[part 11 of 11: packages /CANAnalyzer/CommunicationClusters to /CANAnalyzer/DataTypes]
AUTOSAR XML (schema 00051)
package /CANAnalyzer/CommunicationClusters  (continued)
  can cluster CAN_FD_IPB_41  (continued)
    can physical channel Channel  (continued)
      frame TPDiagnosisFlash_FBD_Miko_IPB: id 0x2C8, frame-length=64, can-addressing-mode=STANDARD, can-frame-rx-behavior=CAN-FD, can-frame-tx-behavior=CAN-FD
        pdu TPDiagnosisFlash_FBD_Miko_IPB: length=64, unused-bit-pattern=0
          signal TPDiagnosisFlashFBD_MikoIPB_Byte00: start 0, 8 bit, little-endian, data-type-policy=OVERRIDE, base-type=uint8, compu {phys=raw}, range phys 0..252
          signal TPDiagnosisFlashFBD_MikoIPB_Byte01: start 8, 8 bit, little-endian, data-type-policy=OVERRIDE, base-type=uint8, compu {phys=raw}, range phys 0..252
          signal TPDiagnosisFlashFBD_MikoIPB_Byte02: start 16, 8 bit, little-endian, data-type-policy=OVERRIDE, base-type=uint8, compu {phys=raw}, range phys 0..252
          signal TPDiagnosisFlashFBD_MikoIPB_Byte03: start 24, 8 bit, little-endian, data-type-policy=OVERRIDE, base-type=uint8, compu {phys=raw}, range phys 0..252
          signal TPDiagnosisFlashFBD_MikoIPB_Byte04: start 32, 8 bit, little-endian, data-type-policy=OVERRIDE, base-type=uint8, compu {phys=raw}, range phys 0..252
          signal TPDiagnosisFlashFBD_MikoIPB_Byte05: start 40, 8 bit, little-endian, data-type-policy=OVERRIDE, base-type=uint8, compu {phys=raw}, range phys 0..252
          signal TPDiagnosisFlashFBD_MikoIPB_Byte06: start 48, 8 bit, little-endian, data-type-policy=OVERRIDE, base-type=uint8, compu {phys=raw}, range phys 0..252
          signal TPDiagnosisFlashFBD_MikoIPB_Byte07: start 56, 8 bit, little-endian, data-type-policy=OVERRIDE, base-type=uint8, compu {phys=raw}, range phys 0..252
          signal TPDiagnosisFlashFBD_MikoIPB_Byte08: start 64, 8 bit, little-endian, data-type-policy=OVERRIDE, base-type=uint8, compu {phys=raw}, range phys 0..252
          signal TPDiagnosisFlashFBD_MikoIPB_Byte09: start 72, 8 bit, little-endian, data-type-policy=OVERRIDE, base-type=uint8, compu {phys=raw}, range phys 0..252
          signal TPDiagnosisFlashFBD_MikoIPB_Byte10: start 80, 8 bit, little-endian, data-type-policy=OVERRIDE, base-type=uint8, compu {phys=raw}, range phys 0..252
          signal TPDiagnosisFlashFBD_MikoIPB_Byte11: start 88, 8 bit, little-endian, data-type-policy=OVERRIDE, base-type=uint8, compu {phys=raw}, range phys 0..252
          signal TPDiagnosisFlashFBD_MikoIPB_Byte12: start 96, 8 bit, little-endian, data-type-policy=OVERRIDE, base-type=uint8, compu {phys=raw}, range phys 0..252
          signal TPDiagnosisFlashFBD_MikoIPB_Byte13: start 104, 8 bit, little-endian, data-type-policy=OVERRIDE, base-type=uint8, compu {phys=raw}, range phys 0..252
          signal TPDiagnosisFlashFBD_MikoIPB_Byte14: start 112, 8 bit, little-endian, data-type-policy=OVERRIDE, base-type=uint8, compu {phys=raw}, range phys 0..252
          signal TPDiagnosisFlashFBD_MikoIPB_Byte15: start 120, 8 bit, little-endian, data-type-policy=OVERRIDE, base-type=uint8, compu {phys=raw}, range phys 0..252
          signal TPDiagnosisFlashFBD_MikoIPB_Byte16: start 128, 8 bit, little-endian, data-type-policy=OVERRIDE, base-type=uint8, compu {phys=raw}, range phys 0..252
          signal TPDiagnosisFlashFBD_MikoIPB_Byte17: start 136, 8 bit, little-endian, data-type-policy=OVERRIDE, base-type=uint8, compu {phys=raw}, range phys 0..252
          signal TPDiagnosisFlashFBD_MikoIPB_Byte18: start 144, 8 bit, little-endian, data-type-policy=OVERRIDE, base-type=uint8, compu {phys=raw}, range phys 0..252
          signal TPDiagnosisFlashFBD_MikoIPB_Byte19: start 152, 8 bit, little-endian, data-type-policy=OVERRIDE, base-type=uint8, compu {phys=raw}, range phys 0..252
          signal TPDiagnosisFlashFBD_MikoIPB_Byte20: start 160, 8 bit, little-endian, data-type-policy=OVERRIDE, base-type=uint8, compu {phys=raw}, range phys 0..252
          signal TPDiagnosisFlashFBD_MikoIPB_Byte21: start 168, 8 bit, little-endian, data-type-policy=OVERRIDE, base-type=uint8, compu {phys=raw}, range phys 0..252
          signal TPDiagnosisFlashFBD_MikoIPB_Byte22: start 176, 8 bit, little-endian, data-type-policy=OVERRIDE, base-type=uint8, compu {phys=raw}, range phys 0..252
          signal TPDiagnosisFlashFBD_MikoIPB_Byte23: start 184, 8 bit, little-endian, data-type-policy=OVERRIDE, base-type=uint8, compu {phys=raw}, range phys 0..252
          signal TPDiagnosisFlashFBD_MikoIPB_Byte24: start 192, 8 bit, little-endian, data-type-policy=OVERRIDE, base-type=uint8, compu {phys=raw}, range phys 0..252
          signal TPDiagnosisFlashFBD_MikoIPB_Byte25: start 200, 8 bit, little-endian, data-type-policy=OVERRIDE, base-type=uint8, compu {phys=raw}, range phys 0..252
          signal TPDiagnosisFlashFBD_MikoIPB_Byte26: start 208, 8 bit, little-endian, data-type-policy=OVERRIDE, base-type=uint8, compu {phys=raw}, range phys 0..252
          signal TPDiagnosisFlashFBD_MikoIPB_Byte27: start 216, 8 bit, little-endian, data-type-policy=OVERRIDE, base-type=uint8, compu {phys=raw}, range phys 0..252
          signal TPDiagnosisFlashFBD_MikoIPB_Byte28: start 224, 8 bit, little-endian, data-type-policy=OVERRIDE, base-type=uint8, compu {phys=raw}, range phys 0..252
          signal TPDiagnosisFlashFBD_MikoIPB_Byte29: start 232, 8 bit, little-endian, data-type-policy=OVERRIDE, base-type=uint8, compu {phys=raw}, range phys 0..252
          signal TPDiagnosisFlashFBD_MikoIPB_Byte30: start 240, 8 bit, little-endian, data-type-policy=OVERRIDE, base-type=uint8, compu {phys=raw}, range phys 0..252
          signal TPDiagnosisFlashFBD_MikoIPB_Byte31: start 248, 8 bit, little-endian, data-type-policy=OVERRIDE, base-type=uint8, compu {phys=raw}, range phys 0..252
          signal TPDiagnosisFlashFBD_MikoIPB_Byte32: start 256, 8 bit, little-endian, data-type-policy=OVERRIDE, base-type=uint8, compu {phys=raw}, range phys 0..252
          signal TPDiagnosisFlashFBD_MikoIPB_Byte33: start 264, 8 bit, little-endian, data-type-policy=OVERRIDE, base-type=uint8, compu {phys=raw}, range phys 0..252
          signal TPDiagnosisFlashFBD_MikoIPB_Byte34: start 272, 8 bit, little-endian, data-type-policy=OVERRIDE, base-type=uint8, compu {phys=raw}, range phys 0..252
          signal TPDiagnosisFlashFBD_MikoIPB_Byte35: start 280, 8 bit, little-endian, data-type-policy=OVERRIDE, base-type=uint8, compu {phys=raw}, range phys 0..252
          signal TPDiagnosisFlashFBD_MikoIPB_Byte36: start 288, 8 bit, little-endian, data-type-policy=OVERRIDE, base-type=uint8, compu {phys=raw}, range phys 0..252
          signal TPDiagnosisFlashFBD_MikoIPB_Byte37: start 296, 8 bit, little-endian, data-type-policy=OVERRIDE, base-type=uint8, compu {phys=raw}, range phys 0..252
          signal TPDiagnosisFlashFBD_MikoIPB_Byte38: start 304, 8 bit, little-endian, data-type-policy=OVERRIDE, base-type=uint8, compu {phys=raw}, range phys 0..252
          signal TPDiagnosisFlashFBD_MikoIPB_Byte39: start 312, 8 bit, little-endian, data-type-policy=OVERRIDE, base-type=uint8, compu {phys=raw}, range phys 0..252
          signal TPDiagnosisFlashFBD_MikoIPB_Byte40: start 320, 8 bit, little-endian, data-type-policy=OVERRIDE, base-type=uint8, compu {phys=raw}, range phys 0..252
          signal TPDiagnosisFlashFBD_MikoIPB_Byte41: start 328, 8 bit, little-endian, data-type-policy=OVERRIDE, base-type=uint8, compu {phys=raw}, range phys 0..252
          signal TPDiagnosisFlashFBD_MikoIPB_Byte42: start 336, 8 bit, little-endian, data-type-policy=OVERRIDE, base-type=uint8, compu {phys=raw}, range phys 0..252
          signal TPDiagnosisFlashFBD_MikoIPB_Byte43: start 344, 8 bit, little-endian, data-type-policy=OVERRIDE, base-type=uint8, compu {phys=raw}, range phys 0..252
          signal TPDiagnosisFlashFBD_MikoIPB_Byte44: start 352, 8 bit, little-endian, data-type-policy=OVERRIDE, base-type=uint8, compu {phys=raw}, range phys 0..252
          signal TPDiagnosisFlashFBD_MikoIPB_Byte45: start 360, 8 bit, little-endian, data-type-policy=OVERRIDE, base-type=uint8, compu {phys=raw}, range phys 0..252
          signal TPDiagnosisFlashFBD_MikoIPB_Byte46: start 368, 8 bit, little-endian, data-type-policy=OVERRIDE, base-type=uint8, compu {phys=raw}, range phys 0..252
          signal TPDiagnosisFlashFBD_MikoIPB_Byte47: start 376, 8 bit, little-endian, data-type-policy=OVERRIDE, base-type=uint8, compu {phys=raw}, range phys 0..252
          signal TPDiagnosisFlashFBD_MikoIPB_Byte48: start 384, 8 bit, little-endian, data-type-policy=OVERRIDE, base-type=uint8, compu {phys=raw}, range phys 0..252
          signal TPDiagnosisFlashFBD_MikoIPB_Byte49: start 392, 8 bit, little-endian, data-type-policy=OVERRIDE, base-type=uint8, compu {phys=raw}, range phys 0..252
          signal TPDiagnosisFlashFBD_MikoIPB_Byte50: start 400, 8 bit, little-endian, data-type-policy=OVERRIDE, base-type=uint8, compu {phys=raw}, range phys 0..252
          signal TPDiagnosisFlashFBD_MikoIPB_Byte51: start 408, 8 bit, little-endian, data-type-policy=OVERRIDE, base-type=uint8, compu {phys=raw}, range phys 0..252
          signal TPDiagnosisFlashFBD_MikoIPB_Byte52: start 416, 8 bit, little-endian, data-type-policy=OVERRIDE, base-type=uint8, compu {phys=raw}, range phys 0..252
          signal TPDiagnosisFlashFBD_MikoIPB_Byte53: start 424, 8 bit, little-endian, data-type-policy=OVERRIDE, base-type=uint8, compu {phys=raw}, range phys 0..252
          signal TPDiagnosisFlashFBD_MikoIPB_Byte54: start 432, 8 bit, little-endian, data-type-policy=OVERRIDE, base-type=uint8, compu {phys=raw}, range phys 0..252
          signal TPDiagnosisFlashFBD_MikoIPB_Byte55: start 440, 8 bit, little-endian, data-type-policy=OVERRIDE, base-type=uint8, compu {phys=raw}, range phys 0..252
          signal TPDiagnosisFlashFBD_MikoIPB_Byte56: start 448, 8 bit, little-endian, data-type-policy=OVERRIDE, base-type=uint8, compu {phys=raw}, range phys 0..252
          signal TPDiagnosisFlashFBD_MikoIPB_Byte57: start 456, 8 bit, little-endian, data-type-policy=OVERRIDE, base-type=uint8, compu {phys=raw}, range phys 0..252
          signal TPDiagnosisFlashFBD_MikoIPB_Byte58: start 464, 8 bit, little-endian, data-type-policy=OVERRIDE, base-type=uint8, compu {phys=raw}, range phys 0..252
          signal TPDiagnosisFlashFBD_MikoIPB_Byte59: start 472, 8 bit, little-endian, data-type-policy=OVERRIDE, base-type=uint8, compu {phys=raw}, range phys 0..252
          signal TPDiagnosisFlashFBD_MikoIPB_Byte60: start 480, 8 bit, little-endian, data-type-policy=OVERRIDE, base-type=uint8, compu {phys=raw}, range phys 0..252
          signal TPDiagnosisFlashFBD_MikoIPB_Byte61: start 488, 8 bit, little-endian, data-type-policy=OVERRIDE, base-type=uint8, compu {phys=raw}, range phys 0..252
          signal TPDiagnosisFlashFBD_MikoIPB_Byte62: start 496, 8 bit, little-endian, data-type-policy=OVERRIDE, base-type=uint8, compu {phys=raw}, range phys 0..252
          signal TPDiagnosisFlashFBD_MikoIPB_Byte63: start 504, 8 bit, little-endian, data-type-policy=OVERRIDE, base-type=uint8, compu {phys=raw}, range phys 0..252
      frame TPDiagnosisFlash_FBD_MM_IPB: id 0x366, frame-length=64, can-addressing-mode=STANDARD, can-frame-rx-behavior=CAN-FD, can-frame-tx-behavior=CAN-FD
        pdu TPDiagnosisFlash_FBD_MM_IPB: length=64, unused-bit-pattern=0
          signal TPDiagnosisFlashFBD_MMIPB_Byte00: start 0, 8 bit, little-endian, data-type-policy=OVERRIDE, base-type=uint8, compu {phys=raw}, range phys 0..252
          signal TPDiagnosisFlashFBD_MMIPB_Byte01: start 8, 8 bit, little-endian, data-type-policy=OVERRIDE, base-type=uint8, compu {phys=raw}, range phys 0..252
          signal TPDiagnosisFlashFBD_MMIPB_Byte02: start 16, 8 bit, little-endian, data-type-policy=OVERRIDE, base-type=uint8, compu {phys=raw}, range phys 0..252
          signal TPDiagnosisFlashFBD_MMIPB_Byte03: start 24, 8 bit, little-endian, data-type-policy=OVERRIDE, base-type=uint8, compu {phys=raw}, range phys 0..252
          signal TPDiagnosisFlashFBD_MMIPB_Byte04: start 32, 8 bit, little-endian, data-type-policy=OVERRIDE, base-type=uint8, compu {phys=raw}, range phys 0..252
          signal TPDiagnosisFlashFBD_MMIPB_Byte05: start 40, 8 bit, little-endian, data-type-policy=OVERRIDE, base-type=uint8, compu {phys=raw}, range phys 0..252
          signal TPDiagnosisFlashFBD_MMIPB_Byte06: start 48, 8 bit, little-endian, data-type-policy=OVERRIDE, base-type=uint8, compu {phys=raw}, range phys 0..252
          signal TPDiagnosisFlashFBD_MMIPB_Byte07: start 56, 8 bit, little-endian, data-type-policy=OVERRIDE, base-type=uint8, compu {phys=raw}, range phys 0..252
          signal TPDiagnosisFlashFBD_MMIPB_Byte08: start 64, 8 bit, little-endian, data-type-policy=OVERRIDE, base-type=uint8, compu {phys=raw}, range phys 0..252
          signal TPDiagnosisFlashFBD_MMIPB_Byte09: start 72, 8 bit, little-endian, data-type-policy=OVERRIDE, base-type=uint8, compu {phys=raw}, range phys 0..252
          signal TPDiagnosisFlashFBD_MMIPB_Byte10: start 80, 8 bit, little-endian, data-type-policy=OVERRIDE, base-type=uint8, compu {phys=raw}, range phys 0..252
          signal TPDiagnosisFlashFBD_MMIPB_Byte11: start 88, 8 bit, little-endian, data-type-policy=OVERRIDE, base-type=uint8, compu {phys=raw}, range phys 0..252
          signal TPDiagnosisFlashFBD_MMIPB_Byte12: start 96, 8 bit, little-endian, data-type-policy=OVERRIDE, base-type=uint8, compu {phys=raw}, range phys 0..252
          signal TPDiagnosisFlashFBD_MMIPB_Byte13: start 104, 8 bit, little-endian, data-type-policy=OVERRIDE, base-type=uint8, compu {phys=raw}, range phys 0..252
          signal TPDiagnosisFlashFBD_MMIPB_Byte14: start 112, 8 bit, little-endian, data-type-policy=OVERRIDE, base-type=uint8, compu {phys=raw}, range phys 0..252
          signal TPDiagnosisFlashFBD_MMIPB_Byte15: start 120, 8 bit, little-endian, data-type-policy=OVERRIDE, base-type=uint8, compu {phys=raw}, range phys 0..252
          signal TPDiagnosisFlashFBD_MMIPB_Byte16: start 128, 8 bit, little-endian, data-type-policy=OVERRIDE, base-type=uint8, compu {phys=raw}, range phys 0..252
          signal TPDiagnosisFlashFBD_MMIPB_Byte17: start 136, 8 bit, little-endian, data-type-policy=OVERRIDE, base-type=uint8, compu {phys=raw}, range phys 0..252
          signal TPDiagnosisFlashFBD_MMIPB_Byte18: start 144, 8 bit, little-endian, data-type-policy=OVERRIDE, base-type=uint8, compu {phys=raw}, range phys 0..252
          signal TPDiagnosisFlashFBD_MMIPB_Byte19: start 152, 8 bit, little-endian, data-type-policy=OVERRIDE, base-type=uint8, compu {phys=raw}, range phys 0..252
          signal TPDiagnosisFlashFBD_MMIPB_Byte20: start 160, 8 bit, little-endian, data-type-policy=OVERRIDE, base-type=uint8, compu {phys=raw}, range phys 0..252
          signal TPDiagnosisFlashFBD_MMIPB_Byte21: start 168, 8 bit, little-endian, data-type-policy=OVERRIDE, base-type=uint8, compu {phys=raw}, range phys 0..252
          signal TPDiagnosisFlashFBD_MMIPB_Byte22: start 176, 8 bit, little-endian, data-type-policy=OVERRIDE, base-type=uint8, compu {phys=raw}, range phys 0..252
          signal TPDiagnosisFlashFBD_MMIPB_Byte23: start 184, 8 bit, little-endian, data-type-policy=OVERRIDE, base-type=uint8, compu {phys=raw}, range phys 0..252
          signal TPDiagnosisFlashFBD_MMIPB_Byte24: start 192, 8 bit, little-endian, data-type-policy=OVERRIDE, base-type=uint8, compu {phys=raw}, range phys 0..252
          signal TPDiagnosisFlashFBD_MMIPB_Byte25: start 200, 8 bit, little-endian, data-type-policy=OVERRIDE, base-type=uint8, compu {phys=raw}, range phys 0..252
          signal TPDiagnosisFlashFBD_MMIPB_Byte26: start 208, 8 bit, little-endian, data-type-policy=OVERRIDE, base-type=uint8, compu {phys=raw}, range phys 0..252
          signal TPDiagnosisFlashFBD_MMIPB_Byte27: start 216, 8 bit, little-endian, data-type-policy=OVERRIDE, base-type=uint8, compu {phys=raw}, range phys 0..252
          signal TPDiagnosisFlashFBD_MMIPB_Byte28: start 224, 8 bit, little-endian, data-type-policy=OVERRIDE, base-type=uint8, compu {phys=raw}, range phys 0..252
          signal TPDiagnosisFlashFBD_MMIPB_Byte29: start 232, 8 bit, little-endian, data-type-policy=OVERRIDE, base-type=uint8, compu {phys=raw}, range phys 0..252
          signal TPDiagnosisFlashFBD_MMIPB_Byte30: start 240, 8 bit, little-endian, data-type-policy=OVERRIDE, base-type=uint8, compu {phys=raw}, range phys 0..252
          signal TPDiagnosisFlashFBD_MMIPB_Byte31: start 248, 8 bit, little-endian, data-type-policy=OVERRIDE, base-type=uint8, compu {phys=raw}, range phys 0..252
          signal TPDiagnosisFlashFBD_MMIPB_Byte32: start 256, 8 bit, little-endian, data-type-policy=OVERRIDE, base-type=uint8, compu {phys=raw}, range phys 0..252
          signal TPDiagnosisFlashFBD_MMIPB_Byte33: start 264, 8 bit, little-endian, data-type-policy=OVERRIDE, base-type=uint8, compu {phys=raw}, range phys 0..252
          signal TPDiagnosisFlashFBD_MMIPB_Byte34: start 272, 8 bit, little-endian, data-type-policy=OVERRIDE, base-type=uint8, compu {phys=raw}, range phys 0..252
          signal TPDiagnosisFlashFBD_MMIPB_Byte35: start 280, 8 bit, little-endian, data-type-policy=OVERRIDE, base-type=uint8, compu {phys=raw}, range phys 0..252
          signal TPDiagnosisFlashFBD_MMIPB_Byte36: start 288, 8 bit, little-endian, data-type-policy=OVERRIDE, base-type=uint8, compu {phys=raw}, range phys 0..252
          signal TPDiagnosisFlashFBD_MMIPB_Byte37: start 296, 8 bit, little-endian, data-type-policy=OVERRIDE, base-type=uint8, compu {phys=raw}, range phys 0..252
          signal TPDiagnosisFlashFBD_MMIPB_Byte38: start 304, 8 bit, little-endian, data-type-policy=OVERRIDE, base-type=uint8, compu {phys=raw}, range phys 0..252
          signal TPDiagnosisFlashFBD_MMIPB_Byte39: start 312, 8 bit, little-endian, data-type-policy=OVERRIDE, base-type=uint8, compu {phys=raw}, range phys 0..252
          signal TPDiagnosisFlashFBD_MMIPB_Byte40: start 320, 8 bit, little-endian, data-type-policy=OVERRIDE, base-type=uint8, compu {phys=raw}, range phys 0..252
          signal TPDiagnosisFlashFBD_MMIPB_Byte41: start 328, 8 bit, little-endian, data-type-policy=OVERRIDE, base-type=uint8, compu {phys=raw}, range phys 0..252
          signal TPDiagnosisFlashFBD_MMIPB_Byte42: start 336, 8 bit, little-endian, data-type-policy=OVERRIDE, base-type=uint8, compu {phys=raw}, range phys 0..252
          signal TPDiagnosisFlashFBD_MMIPB_Byte43: start 344, 8 bit, little-endian, data-type-policy=OVERRIDE, base-type=uint8, compu {phys=raw}, range phys 0..252
          signal TPDiagnosisFlashFBD_MMIPB_Byte44: start 352, 8 bit, little-endian, data-type-policy=OVERRIDE, base-type=uint8, compu {phys=raw}, range phys 0..252
          signal TPDiagnosisFlashFBD_MMIPB_Byte45: start 360, 8 bit, little-endian, data-type-policy=OVERRIDE, base-type=uint8, compu {phys=raw}, range phys 0..252
          signal TPDiagnosisFlashFBD_MMIPB_Byte46: start 368, 8 bit, little-endian, data-type-policy=OVERRIDE, base-type=uint8, compu {phys=raw}, range phys 0..252
          signal TPDiagnosisFlashFBD_MMIPB_Byte47: start 376, 8 bit, little-endian, data-type-policy=OVERRIDE, base-type=uint8, compu {phys=raw}, range phys 0..252
          signal TPDiagnosisFlashFBD_MMIPB_Byte48: start 384, 8 bit, little-endian, data-type-policy=OVERRIDE, base-type=uint8, compu {phys=raw}, range phys 0..252
          signal TPDiagnosisFlashFBD_MMIPB_Byte49: start 392, 8 bit, little-endian, data-type-policy=OVERRIDE, base-type=uint8, compu {phys=raw}, range phys 0..252
          signal TPDiagnosisFlashFBD_MMIPB_Byte50: start 400, 8 bit, little-endian, data-type-policy=OVERRIDE, base-type=uint8, compu {phys=raw}, range phys 0..252
          signal TPDiagnosisFlashFBD_MMIPB_Byte51: start 408, 8 bit, little-endian, data-type-policy=OVERRIDE, base-type=uint8, compu {phys=raw}, range phys 0..252
          signal TPDiagnosisFlashFBD_MMIPB_Byte52: start 416, 8 bit, little-endian, data-type-policy=OVERRIDE, base-type=uint8, compu {phys=raw}, range phys 0..252
          signal TPDiagnosisFlashFBD_MMIPB_Byte53: start 424, 8 bit, little-endian, data-type-policy=OVERRIDE, base-type=uint8, compu {phys=raw}, range phys 0..252
          signal TPDiagnosisFlashFBD_MMIPB_Byte54: start 432, 8 bit, little-endian, data-type-policy=OVERRIDE, base-type=uint8, compu {phys=raw}, range phys 0..252
          signal TPDiagnosisFlashFBD_MMIPB_Byte55: start 440, 8 bit, little-endian, data-type-policy=OVERRIDE, base-type=uint8, compu {phys=raw}, range phys 0..252
          signal TPDiagnosisFlashFBD_MMIPB_Byte56: start 448, 8 bit, little-endian, data-type-policy=OVERRIDE, base-type=uint8, compu {phys=raw}, range phys 0..252
          signal TPDiagnosisFlashFBD_MMIPB_Byte57: start 456, 8 bit, little-endian, data-type-policy=OVERRIDE, base-type=uint8, compu {phys=raw}, range phys 0..252
          signal TPDiagnosisFlashFBD_MMIPB_Byte58: start 464, 8 bit, little-endian, data-type-policy=OVERRIDE, base-type=uint8, compu {phys=raw}, range phys 0..252
          signal TPDiagnosisFlashFBD_MMIPB_Byte59: start 472, 8 bit, little-endian, data-type-policy=OVERRIDE, base-type=uint8, compu {phys=raw}, range phys 0..252
          signal TPDiagnosisFlashFBD_MMIPB_Byte60: start 480, 8 bit, little-endian, data-type-policy=OVERRIDE, base-type=uint8, compu {phys=raw}, range phys 0..252
          signal TPDiagnosisFlashFBD_MMIPB_Byte61: start 488, 8 bit, little-endian, data-type-policy=OVERRIDE, base-type=uint8, compu {phys=raw}, range phys 0..252
          signal TPDiagnosisFlashFBD_MMIPB_Byte62: start 496, 8 bit, little-endian, data-type-policy=OVERRIDE, base-type=uint8, compu {phys=raw}, range phys 0..252
          signal TPDiagnosisFlashFBD_MMIPB_Byte63: start 504, 8 bit, little-endian, data-type-policy=OVERRIDE, base-type=uint8, compu {phys=raw}, range phys 0..252
      frame TPDiagnosisFlash_FBD_Trunk_IPB: id 0x2C9, frame-length=64, can-addressing-mode=STANDARD, can-frame-rx-behavior=CAN-FD, can-frame-tx-behavior=CAN-FD
        pdu TPDiagnosisFlash_FBD_Trunk_IPB: length=64, unused-bit-pattern=0
          signal TPDiagnosisFlashFBD_TrunkIPB_Byte00: start 0, 8 bit, little-endian, data-type-policy=OVERRIDE, base-type=uint8, compu {phys=raw}, range phys 0..252
          signal TPDiagnosisFlashFBD_TrunkIPB_Byte01: start 8, 8 bit, little-endian, data-type-policy=OVERRIDE, base-type=uint8, compu {phys=raw}, range phys 0..252
          signal TPDiagnosisFlashFBD_TrunkIPB_Byte02: start 16, 8 bit, little-endian, data-type-policy=OVERRIDE, base-type=uint8, compu {phys=raw}, range phys 0..252
          signal TPDiagnosisFlashFBD_TrunkIPB_Byte03: start 24, 8 bit, little-endian, data-type-policy=OVERRIDE, base-type=uint8, compu {phys=raw}, range phys 0..252
          signal TPDiagnosisFlashFBD_TrunkIPB_Byte04: start 32, 8 bit, little-endian, data-type-policy=OVERRIDE, base-type=uint8, compu {phys=raw}, range phys 0..252
          signal TPDiagnosisFlashFBD_TrunkIPB_Byte05: start 40, 8 bit, little-endian, data-type-policy=OVERRIDE, base-type=uint8, compu {phys=raw}, range phys 0..252
          signal TPDiagnosisFlashFBD_TrunkIPB_Byte06: start 48, 8 bit, little-endian, data-type-policy=OVERRIDE, base-type=uint8, compu {phys=raw}, range phys 0..252
          signal TPDiagnosisFlashFBD_TrunkIPB_Byte07: start 56, 8 bit, little-endian, data-type-policy=OVERRIDE, base-type=uint8, compu {phys=raw}, range phys 0..252
          signal TPDiagnosisFlashFBD_TrunkIPB_Byte08: start 64, 8 bit, little-endian, data-type-policy=OVERRIDE, base-type=uint8, compu {phys=raw}, range phys 0..252
          signal TPDiagnosisFlashFBD_TrunkIPB_Byte09: start 72, 8 bit, little-endian, data-type-policy=OVERRIDE, base-type=uint8, compu {phys=raw}, range phys 0..252
          signal TPDiagnosisFlashFBD_TrunkIPB_Byte10: start 80, 8 bit, little-endian, data-type-policy=OVERRIDE, base-type=uint8, compu {phys=raw}, range phys 0..252
          signal TPDiagnosisFlashFBD_TrunkIPB_Byte11: start 88, 8 bit, little-endian, data-type-policy=OVERRIDE, base-type=uint8, compu {phys=raw}, range phys 0..252
          signal TPDiagnosisFlashFBD_TrunkIPB_Byte12: start 96, 8 bit, little-endian, data-type-policy=OVERRIDE, base-type=uint8, compu {phys=raw}, range phys 0..252
          signal TPDiagnosisFlashFBD_TrunkIPB_Byte13: start 104, 8 bit, little-endian, data-type-policy=OVERRIDE, base-type=uint8, compu {phys=raw}, range phys 0..252
          signal TPDiagnosisFlashFBD_TrunkIPB_Byte14: start 112, 8 bit, little-endian, data-type-policy=OVERRIDE, base-type=uint8, compu {phys=raw}, range phys 0..252
          signal TPDiagnosisFlashFBD_TrunkIPB_Byte15: start 120, 8 bit, little-endian, data-type-policy=OVERRIDE, base-type=uint8, compu {phys=raw}, range phys 0..252
          signal TPDiagnosisFlashFBD_TrunkIPB_Byte16: start 128, 8 bit, little-endian, data-type-policy=OVERRIDE, base-type=uint8, compu {phys=raw}, range phys 0..252
          signal TPDiagnosisFlashFBD_TrunkIPB_Byte17: start 136, 8 bit, little-endian, data-type-policy=OVERRIDE, base-type=uint8, compu {phys=raw}, range phys 0..252
          signal TPDiagnosisFlashFBD_TrunkIPB_Byte18: start 144, 8 bit, little-endian, data-type-policy=OVERRIDE, base-type=uint8, compu {phys=raw}, range phys 0..252
          signal TPDiagnosisFlashFBD_TrunkIPB_Byte19: start 152, 8 bit, little-endian, data-type-policy=OVERRIDE, base-type=uint8, compu {phys=raw}, range phys 0..252
          signal TPDiagnosisFlashFBD_TrunkIPB_Byte20: start 160, 8 bit, little-endian, data-type-policy=OVERRIDE, base-type=uint8, compu {phys=raw}, range phys 0..252
          signal TPDiagnosisFlashFBD_TrunkIPB_Byte21: start 168, 8 bit, little-endian, data-type-policy=OVERRIDE, base-type=uint8, compu {phys=raw}, range phys 0..252
          signal TPDiagnosisFlashFBD_TrunkIPB_Byte22: start 176, 8 bit, little-endian, data-type-policy=OVERRIDE, base-type=uint8, compu {phys=raw}, range phys 0..252
          signal TPDiagnosisFlashFBD_TrunkIPB_Byte23: start 184, 8 bit, little-endian, data-type-policy=OVERRIDE, base-type=uint8, compu {phys=raw}, range phys 0..252
          signal TPDiagnosisFlashFBD_TrunkIPB_Byte24: start 192, 8 bit, little-endian, data-type-policy=OVERRIDE, base-type=uint8, compu {phys=raw}, range phys 0..252
          signal TPDiagnosisFlashFBD_TrunkIPB_Byte25: start 200, 8 bit, little-endian, data-type-policy=OVERRIDE, base-type=uint8, compu {phys=raw}, range phys 0..252
          signal TPDiagnosisFlashFBD_TrunkIPB_Byte26: start 208, 8 bit, little-endian, data-type-policy=OVERRIDE, base-type=uint8, compu {phys=raw}, range phys 0..252
          signal TPDiagnosisFlashFBD_TrunkIPB_Byte27: start 216, 8 bit, little-endian, data-type-policy=OVERRIDE, base-type=uint8, compu {phys=raw}, range phys 0..252
          signal TPDiagnosisFlashFBD_TrunkIPB_Byte28: start 224, 8 bit, little-endian, data-type-policy=OVERRIDE, base-type=uint8, compu {phys=raw}, range phys 0..252
          signal TPDiagnosisFlashFBD_TrunkIPB_Byte29: start 232, 8 bit, little-endian, data-type-policy=OVERRIDE, base-type=uint8, compu {phys=raw}, range phys 0..252
          signal TPDiagnosisFlashFBD_TrunkIPB_Byte30: start 240, 8 bit, little-endian, data-type-policy=OVERRIDE, base-type=uint8, compu {phys=raw}, range phys 0..252
          signal TPDiagnosisFlashFBD_TrunkIPB_Byte31: start 248, 8 bit, little-endian, data-type-policy=OVERRIDE, base-type=uint8, compu {phys=raw}, range phys 0..252
          signal TPDiagnosisFlashFBD_TrunkIPB_Byte32: start 256, 8 bit, little-endian, data-type-policy=OVERRIDE, base-type=uint8, compu {phys=raw}, range phys 0..252
          signal TPDiagnosisFlashFBD_TrunkIPB_Byte33: start 264, 8 bit, little-endian, data-type-policy=OVERRIDE, base-type=uint8, compu {phys=raw}, range phys 0..252
          signal TPDiagnosisFlashFBD_TrunkIPB_Byte34: start 272, 8 bit, little-endian, data-type-policy=OVERRIDE, base-type=uint8, compu {phys=raw}, range phys 0..252
          signal TPDiagnosisFlashFBD_TrunkIPB_Byte35: start 280, 8 bit, little-endian, data-type-policy=OVERRIDE, base-type=uint8, compu {phys=raw}, range phys 0..252
          signal TPDiagnosisFlashFBD_TrunkIPB_Byte36: start 288, 8 bit, little-endian, data-type-policy=OVERRIDE, base-type=uint8, compu {phys=raw}, range phys 0..252
          signal TPDiagnosisFlashFBD_TrunkIPB_Byte37: start 296, 8 bit, little-endian, data-type-policy=OVERRIDE, base-type=uint8, compu {phys=raw}, range phys 0..252
          signal TPDiagnosisFlashFBD_TrunkIPB_Byte38: start 304, 8 bit, little-endian, data-type-policy=OVERRIDE, base-type=uint8, compu {phys=raw}, range phys 0..252
          signal TPDiagnosisFlashFBD_TrunkIPB_Byte39: start 312, 8 bit, little-endian, data-type-policy=OVERRIDE, base-type=uint8, compu {phys=raw}, range phys 0..252
          signal TPDiagnosisFlashFBD_TrunkIPB_Byte40: start 320, 8 bit, little-endian, data-type-policy=OVERRIDE, base-type=uint8, compu {phys=raw}, range phys 0..252
          signal TPDiagnosisFlashFBD_TrunkIPB_Byte41: start 328, 8 bit, little-endian, data-type-policy=OVERRIDE, base-type=uint8, compu {phys=raw}, range phys 0..252
          signal TPDiagnosisFlashFBD_TrunkIPB_Byte42: start 336, 8 bit, little-endian, data-type-policy=OVERRIDE, base-type=uint8, compu {phys=raw}, range phys 0..252
          signal TPDiagnosisFlashFBD_TrunkIPB_Byte43: start 344, 8 bit, little-endian, data-type-policy=OVERRIDE, base-type=uint8, compu {phys=raw}, range phys 0..252
          signal TPDiagnosisFlashFBD_TrunkIPB_Byte44: start 352, 8 bit, little-endian, data-type-policy=OVERRIDE, base-type=uint8, compu {phys=raw}, range phys 0..252
          signal TPDiagnosisFlashFBD_TrunkIPB_Byte45: start 360, 8 bit, little-endian, data-type-policy=OVERRIDE, base-type=uint8, compu {phys=raw}, range phys 0..252
          signal TPDiagnosisFlashFBD_TrunkIPB_Byte46: start 368, 8 bit, little-endian, data-type-policy=OVERRIDE, base-type=uint8, compu {phys=raw}, range phys 0..252
          signal TPDiagnosisFlashFBD_TrunkIPB_Byte47: start 376, 8 bit, little-endian, data-type-policy=OVERRIDE, base-type=uint8, compu {phys=raw}, range phys 0..252
          signal TPDiagnosisFlashFBD_TrunkIPB_Byte48: start 384, 8 bit, little-endian, data-type-policy=OVERRIDE, base-type=uint8, compu {phys=raw}, range phys 0..252
          signal TPDiagnosisFlashFBD_TrunkIPB_Byte49: start 392, 8 bit, little-endian, data-type-policy=OVERRIDE, base-type=uint8, compu {phys=raw}, range phys 0..252
          signal TPDiagnosisFlashFBD_TrunkIPB_Byte50: start 400, 8 bit, little-endian, data-type-policy=OVERRIDE, base-type=uint8, compu {phys=raw}, range phys 0..252
          signal TPDiagnosisFlashFBD_TrunkIPB_Byte51: start 408, 8 bit, little-endian, data-type-policy=OVERRIDE, base-type=uint8, compu {phys=raw}, range phys 0..252
          signal TPDiagnosisFlashFBD_TrunkIPB_Byte52: start 416, 8 bit, little-endian, data-type-policy=OVERRIDE, base-type=uint8, compu {phys=raw}, range phys 0..252
          signal TPDiagnosisFlashFBD_TrunkIPB_Byte53: start 424, 8 bit, little-endian, data-type-policy=OVERRIDE, base-type=uint8, compu {phys=raw}, range phys 0..252
          signal TPDiagnosisFlashFBD_TrunkIPB_Byte54: start 432, 8 bit, little-endian, data-type-policy=OVERRIDE, base-type=uint8, compu {phys=raw}, range phys 0..252
          signal TPDiagnosisFlashFBD_TrunkIPB_Byte55: start 440, 8 bit, little-endian, data-type-policy=OVERRIDE, base-type=uint8, compu {phys=raw}, range phys 0..252
          signal TPDiagnosisFlashFBD_TrunkIPB_Byte56: start 448, 8 bit, little-endian, data-type-policy=OVERRIDE, base-type=uint8, compu {phys=raw}, range phys 0..252
          signal TPDiagnosisFlashFBD_TrunkIPB_Byte57: start 456, 8 bit, little-endian, data-type-policy=OVERRIDE, base-type=uint8, compu {phys=raw}, range phys 0..252
          signal TPDiagnosisFlashFBD_TrunkIPB_Byte58: start 464, 8 bit, little-endian, data-type-policy=OVERRIDE, base-type=uint8, compu {phys=raw}, range phys 0..252
          signal TPDiagnosisFlashFBD_TrunkIPB_Byte59: start 472, 8 bit, little-endian, data-type-policy=OVERRIDE, base-type=uint8, compu {phys=raw}, range phys 0..252
          signal TPDiagnosisFlashFBD_TrunkIPB_Byte60: start 480, 8 bit, little-endian, data-type-policy=OVERRIDE, base-type=uint8, compu {phys=raw}, range phys 0..252
          signal TPDiagnosisFlashFBD_TrunkIPB_Byte61: start 488, 8 bit, little-endian, data-type-policy=OVERRIDE, base-type=uint8, compu {phys=raw}, range phys 0..252
          signal TPDiagnosisFlashFBD_TrunkIPB_Byte62: start 496, 8 bit, little-endian, data-type-policy=OVERRIDE, base-type=uint8, compu {phys=raw}, range phys 0..252
          signal TPDiagnosisFlashFBD_TrunkIPB_Byte63: start 504, 8 bit, little-endian, data-type-policy=OVERRIDE, base-type=uint8, compu {phys=raw}, range phys 0..252
      frame TPDiagnosisFlash_FBD_VL_IPB: id 0x2CA, frame-length=64, can-addressing-mode=STANDARD, can-frame-rx-behavior=CAN-FD, can-frame-tx-behavior=CAN-FD
        pdu TPDiagnosisFlash_FBD_VL_IPB: length=64, unused-bit-pattern=0
          signal TPDiagnosisFlashFBD_VLIPB_Byte00: start 0, 8 bit, little-endian, data-type-policy=OVERRIDE, base-type=uint8, compu {phys=raw}, range phys 0..252
          signal TPDiagnosisFlashFBD_VLIPB_Byte01: start 8, 8 bit, little-endian, data-type-policy=OVERRIDE, base-type=uint8, compu {phys=raw}, range phys 0..252
          signal TPDiagnosisFlashFBD_VLIPB_Byte02: start 16, 8 bit, little-endian, data-type-policy=OVERRIDE, base-type=uint8, compu {phys=raw}, range phys 0..252
          signal TPDiagnosisFlashFBD_VLIPB_Byte03: start 24, 8 bit, little-endian, data-type-policy=OVERRIDE, base-type=uint8, compu {phys=raw}, range phys 0..252
          signal TPDiagnosisFlashFBD_VLIPB_Byte04: start 32, 8 bit, little-endian, data-type-policy=OVERRIDE, base-type=uint8, compu {phys=raw}, range phys 0..252
          signal TPDiagnosisFlashFBD_VLIPB_Byte05: start 40, 8 bit, little-endian, data-type-policy=OVERRIDE, base-type=uint8, compu {phys=raw}, range phys 0..252
          signal TPDiagnosisFlashFBD_VLIPB_Byte06: start 48, 8 bit, little-endian, data-type-policy=OVERRIDE, base-type=uint8, compu {phys=raw}, range phys 0..252
          signal TPDiagnosisFlashFBD_VLIPB_Byte07: start 56, 8 bit, little-endian, data-type-policy=OVERRIDE, base-type=uint8, compu {phys=raw}, range phys 0..252
          signal TPDiagnosisFlashFBD_VLIPB_Byte08: start 64, 8 bit, little-endian, data-type-policy=OVERRIDE, base-type=uint8, compu {phys=raw}, range phys 0..252
          signal TPDiagnosisFlashFBD_VLIPB_Byte09: start 72, 8 bit, little-endian, data-type-policy=OVERRIDE, base-type=uint8, compu {phys=raw}, range phys 0..252
          signal TPDiagnosisFlashFBD_VLIPB_Byte10: start 80, 8 bit, little-endian, data-type-policy=OVERRIDE, base-type=uint8, compu {phys=raw}, range phys 0..252
          signal TPDiagnosisFlashFBD_VLIPB_Byte11: start 88, 8 bit, little-endian, data-type-policy=OVERRIDE, base-type=uint8, compu {phys=raw}, range phys 0..252
          signal TPDiagnosisFlashFBD_VLIPB_Byte12: start 96, 8 bit, little-endian, data-type-policy=OVERRIDE, base-type=uint8, compu {phys=raw}, range phys 0..252
          signal TPDiagnosisFlashFBD_VLIPB_Byte13: start 104, 8 bit, little-endian, data-type-policy=OVERRIDE, base-type=uint8, compu {phys=raw}, range phys 0..252
          signal TPDiagnosisFlashFBD_VLIPB_Byte14: start 112, 8 bit, little-endian, data-type-policy=OVERRIDE, base-type=uint8, compu {phys=raw}, range phys 0..252
          signal TPDiagnosisFlashFBD_VLIPB_Byte15: start 120, 8 bit, little-endian, data-type-policy=OVERRIDE, base-type=uint8, compu {phys=raw}, range phys 0..252
          signal TPDiagnosisFlashFBD_VLIPB_Byte16: start 128, 8 bit, little-endian, data-type-policy=OVERRIDE, base-type=uint8, compu {phys=raw}, range phys 0..252
          signal TPDiagnosisFlashFBD_VLIPB_Byte17: start 136, 8 bit, little-endian, data-type-policy=OVERRIDE, base-type=uint8, compu {phys=raw}, range phys 0..252
          signal TPDiagnosisFlashFBD_VLIPB_Byte18: start 144, 8 bit, little-endian, data-type-policy=OVERRIDE, base-type=uint8, compu {phys=raw}, range phys 0..252
          signal TPDiagnosisFlashFBD_VLIPB_Byte19: start 152, 8 bit, little-endian, data-type-policy=OVERRIDE, base-type=uint8, compu {phys=raw}, range phys 0..252
          signal TPDiagnosisFlashFBD_VLIPB_Byte20: start 160, 8 bit, little-endian, data-type-policy=OVERRIDE, base-type=uint8, compu {phys=raw}, range phys 0..252
          signal TPDiagnosisFlashFBD_VLIPB_Byte21: start 168, 8 bit, little-endian, data-type-policy=OVERRIDE, base-type=uint8, compu {phys=raw}, range phys 0..252
          signal TPDiagnosisFlashFBD_VLIPB_Byte22: start 176, 8 bit, little-endian, data-type-policy=OVERRIDE, base-type=uint8, compu {phys=raw}, range phys 0..252
          signal TPDiagnosisFlashFBD_VLIPB_Byte23: start 184, 8 bit, little-endian, data-type-policy=OVERRIDE, base-type=uint8, compu {phys=raw}, range phys 0..252
          signal TPDiagnosisFlashFBD_VLIPB_Byte24: start 192, 8 bit, little-endian, data-type-policy=OVERRIDE, base-type=uint8, compu {phys=raw}, range phys 0..252
          signal TPDiagnosisFlashFBD_VLIPB_Byte25: start 200, 8 bit, little-endian, data-type-policy=OVERRIDE, base-type=uint8, compu {phys=raw}, range phys 0..252
          signal TPDiagnosisFlashFBD_VLIPB_Byte26: start 208, 8 bit, little-endian, data-type-policy=OVERRIDE, base-type=uint8, compu {phys=raw}, range phys 0..252
          signal TPDiagnosisFlashFBD_VLIPB_Byte27: start 216, 8 bit, little-endian, data-type-policy=OVERRIDE, base-type=uint8, compu {phys=raw}, range phys 0..252
          signal TPDiagnosisFlashFBD_VLIPB_Byte28: start 224, 8 bit, little-endian, data-type-policy=OVERRIDE, base-type=uint8, compu {phys=raw}, range phys 0..252
          signal TPDiagnosisFlashFBD_VLIPB_Byte29: start 232, 8 bit, little-endian, data-type-policy=OVERRIDE, base-type=uint8, compu {phys=raw}, range phys 0..252
          signal TPDiagnosisFlashFBD_VLIPB_Byte30: start 240, 8 bit, little-endian, data-type-policy=OVERRIDE, base-type=uint8, compu {phys=raw}, range phys 0..252
          signal TPDiagnosisFlashFBD_VLIPB_Byte31: start 248, 8 bit, little-endian, data-type-policy=OVERRIDE, base-type=uint8, compu {phys=raw}, range phys 0..252
          signal TPDiagnosisFlashFBD_VLIPB_Byte32: start 256, 8 bit, little-endian, data-type-policy=OVERRIDE, base-type=uint8, compu {phys=raw}, range phys 0..252
          signal TPDiagnosisFlashFBD_VLIPB_Byte33: start 264, 8 bit, little-endian, data-type-policy=OVERRIDE, base-type=uint8, compu {phys=raw}, range phys 0..252
          signal TPDiagnosisFlashFBD_VLIPB_Byte34: start 272, 8 bit, little-endian, data-type-policy=OVERRIDE, base-type=uint8, compu {phys=raw}, range phys 0..252
          signal TPDiagnosisFlashFBD_VLIPB_Byte35: start 280, 8 bit, little-endian, data-type-policy=OVERRIDE, base-type=uint8, compu {phys=raw}, range phys 0..252
          signal TPDiagnosisFlashFBD_VLIPB_Byte36: start 288, 8 bit, little-endian, data-type-policy=OVERRIDE, base-type=uint8, compu {phys=raw}, range phys 0..252
          signal TPDiagnosisFlashFBD_VLIPB_Byte37: start 296, 8 bit, little-endian, data-type-policy=OVERRIDE, base-type=uint8, compu {phys=raw}, range phys 0..252
          signal TPDiagnosisFlashFBD_VLIPB_Byte38: start 304, 8 bit, little-endian, data-type-policy=OVERRIDE, base-type=uint8, compu {phys=raw}, range phys 0..252
          signal TPDiagnosisFlashFBD_VLIPB_Byte39: start 312, 8 bit, little-endian, data-type-policy=OVERRIDE, base-type=uint8, compu {phys=raw}, range phys 0..252
          signal TPDiagnosisFlashFBD_VLIPB_Byte40: start 320, 8 bit, little-endian, data-type-policy=OVERRIDE, base-type=uint8, compu {phys=raw}, range phys 0..252
          signal TPDiagnosisFlashFBD_VLIPB_Byte41: start 328, 8 bit, little-endian, data-type-policy=OVERRIDE, base-type=uint8, compu {phys=raw}, range phys 0..252
          signal TPDiagnosisFlashFBD_VLIPB_Byte42: start 336, 8 bit, little-endian, data-type-policy=OVERRIDE, base-type=uint8, compu {phys=raw}, range phys 0..252
          signal TPDiagnosisFlashFBD_VLIPB_Byte43: start 344, 8 bit, little-endian, data-type-policy=OVERRIDE, base-type=uint8, compu {phys=raw}, range phys 0..252
          signal TPDiagnosisFlashFBD_VLIPB_Byte44: start 352, 8 bit, little-endian, data-type-policy=OVERRIDE, base-type=uint8, compu {phys=raw}, range phys 0..252
          signal TPDiagnosisFlashFBD_VLIPB_Byte45: start 360, 8 bit, little-endian, data-type-policy=OVERRIDE, base-type=uint8, compu {phys=raw}, range phys 0..252
          signal TPDiagnosisFlashFBD_VLIPB_Byte46: start 368, 8 bit, little-endian, data-type-policy=OVERRIDE, base-type=uint8, compu {phys=raw}, range phys 0..252
          signal TPDiagnosisFlashFBD_VLIPB_Byte47: start 376, 8 bit, little-endian, data-type-policy=OVERRIDE, base-type=uint8, compu {phys=raw}, range phys 0..252
          signal TPDiagnosisFlashFBD_VLIPB_Byte48: start 384, 8 bit, little-endian, data-type-policy=OVERRIDE, base-type=uint8, compu {phys=raw}, range phys 0..252
          signal TPDiagnosisFlashFBD_VLIPB_Byte49: start 392, 8 bit, little-endian, data-type-policy=OVERRIDE, base-type=uint8, compu {phys=raw}, range phys 0..252
          signal TPDiagnosisFlashFBD_VLIPB_Byte50: start 400, 8 bit, little-endian, data-type-policy=OVERRIDE, base-type=uint8, compu {phys=raw}, range phys 0..252
          signal TPDiagnosisFlashFBD_VLIPB_Byte51: start 408, 8 bit, little-endian, data-type-policy=OVERRIDE, base-type=uint8, compu {phys=raw}, range phys 0..252
          signal TPDiagnosisFlashFBD_VLIPB_Byte52: start 416, 8 bit, little-endian, data-type-policy=OVERRIDE, base-type=uint8, compu {phys=raw}, range phys 0..252
          signal TPDiagnosisFlashFBD_VLIPB_Byte53: start 424, 8 bit, little-endian, data-type-policy=OVERRIDE, base-type=uint8, compu {phys=raw}, range phys 0..252
          signal TPDiagnosisFlashFBD_VLIPB_Byte54: start 432, 8 bit, little-endian, data-type-policy=OVERRIDE, base-type=uint8, compu {phys=raw}, range phys 0..252
          signal TPDiagnosisFlashFBD_VLIPB_Byte55: start 440, 8 bit, little-endian, data-type-policy=OVERRIDE, base-type=uint8, compu {phys=raw}, range phys 0..252
          signal TPDiagnosisFlashFBD_VLIPB_Byte56: start 448, 8 bit, little-endian, data-type-policy=OVERRIDE, base-type=uint8, compu {phys=raw}, range phys 0..252
          signal TPDiagnosisFlashFBD_VLIPB_Byte57: start 456, 8 bit, little-endian, data-type-policy=OVERRIDE, base-type=uint8, compu {phys=raw}, range phys 0..252
          signal TPDiagnosisFlashFBD_VLIPB_Byte58: start 464, 8 bit, little-endian, data-type-policy=OVERRIDE, base-type=uint8, compu {phys=raw}, range phys 0..252
          signal TPDiagnosisFlashFBD_VLIPB_Byte59: start 472, 8 bit, little-endian, data-type-policy=OVERRIDE, base-type=uint8, compu {phys=raw}, range phys 0..252
          signal TPDiagnosisFlashFBD_VLIPB_Byte60: start 480, 8 bit, little-endian, data-type-policy=OVERRIDE, base-type=uint8, compu {phys=raw}, range phys 0..252
          signal TPDiagnosisFlashFBD_VLIPB_Byte61: start 488, 8 bit, little-endian, data-type-policy=OVERRIDE, base-type=uint8, compu {phys=raw}, range phys 0..252
          signal TPDiagnosisFlashFBD_VLIPB_Byte62: start 496, 8 bit, little-endian, data-type-policy=OVERRIDE, base-type=uint8, compu {phys=raw}, range phys 0..252
          signal TPDiagnosisFlashFBD_VLIPB_Byte63: start 504, 8 bit, little-endian, data-type-policy=OVERRIDE, base-type=uint8, compu {phys=raw}, range phys 0..252
      frame TPDiagnosisFlash_FBD_VM_IPB: id 0x2C6, frame-length=64, can-addressing-mode=STANDARD, can-frame-rx-behavior=CAN-FD, can-frame-tx-behavior=CAN-FD
        pdu TPDiagnosisFlash_FBD_VM_IPB: length=64, unused-bit-pattern=0
          signal TPDiagnosisFlashFBD_VMIPB_Byte00: start 0, 8 bit, little-endian, data-type-policy=OVERRIDE, base-type=uint8, compu {phys=raw}, range phys 0..252
          signal TPDiagnosisFlashFBD_VMIPB_Byte01: start 8, 8 bit, little-endian, data-type-policy=OVERRIDE, base-type=uint8, compu {phys=raw}, range phys 0..252
          signal TPDiagnosisFlashFBD_VMIPB_Byte02: start 16, 8 bit, little-endian, data-type-policy=OVERRIDE, base-type=uint8, compu {phys=raw}, range phys 0..252
          signal TPDiagnosisFlashFBD_VMIPB_Byte03: start 24, 8 bit, little-endian, data-type-policy=OVERRIDE, base-type=uint8, compu {phys=raw}, range phys 0..252
          signal TPDiagnosisFlashFBD_VMIPB_Byte04: start 32, 8 bit, little-endian, data-type-policy=OVERRIDE, base-type=uint8, compu {phys=raw}, range phys 0..252
          signal TPDiagnosisFlashFBD_VMIPB_Byte05: start 40, 8 bit, little-endian, data-type-policy=OVERRIDE, base-type=uint8, compu {phys=raw}, range phys 0..252
          signal TPDiagnosisFlashFBD_VMIPB_Byte06: start 48, 8 bit, little-endian, data-type-policy=OVERRIDE, base-type=uint8, compu {phys=raw}, range phys 0..252
          signal TPDiagnosisFlashFBD_VMIPB_Byte07: start 56, 8 bit, little-endian, data-type-policy=OVERRIDE, base-type=uint8, compu {phys=raw}, range phys 0..252
          signal TPDiagnosisFlashFBD_VMIPB_Byte08: start 64, 8 bit, little-endian, data-type-policy=OVERRIDE, base-type=uint8, compu {phys=raw}, range phys 0..252
          signal TPDiagnosisFlashFBD_VMIPB_Byte09: start 72, 8 bit, little-endian, data-type-policy=OVERRIDE, base-type=uint8, compu {phys=raw}, range phys 0..252
          signal TPDiagnosisFlashFBD_VMIPB_Byte10: start 80, 8 bit, little-endian, data-type-policy=OVERRIDE, base-type=uint8, compu {phys=raw}, range phys 0..252
          signal TPDiagnosisFlashFBD_VMIPB_Byte11: start 88, 8 bit, little-endian, data-type-policy=OVERRIDE, base-type=uint8, compu {phys=raw}, range phys 0..252
          signal TPDiagnosisFlashFBD_VMIPB_Byte12: start 96, 8 bit, little-endian, data-type-policy=OVERRIDE, base-type=uint8, compu {phys=raw}, range phys 0..252
          signal TPDiagnosisFlashFBD_VMIPB_Byte13: start 104, 8 bit, little-endian, data-type-policy=OVERRIDE, base-type=uint8, compu {phys=raw}, range phys 0..252
          signal TPDiagnosisFlashFBD_VMIPB_Byte14: start 112, 8 bit, little-endian, data-type-policy=OVERRIDE, base-type=uint8, compu {phys=raw}, range phys 0..252
          signal TPDiagnosisFlashFBD_VMIPB_Byte15: start 120, 8 bit, little-endian, data-type-policy=OVERRIDE, base-type=uint8, compu {phys=raw}, range phys 0..252
          signal TPDiagnosisFlashFBD_VMIPB_Byte16: start 128, 8 bit, little-endian, data-type-policy=OVERRIDE, base-type=uint8, compu {phys=raw}, range phys 0..252
          signal TPDiagnosisFlashFBD_VMIPB_Byte17: start 136, 8 bit, little-endian, data-type-policy=OVERRIDE, base-type=uint8, compu {phys=raw}, range phys 0..252
          signal TPDiagnosisFlashFBD_VMIPB_Byte18: start 144, 8 bit, little-endian, data-type-policy=OVERRIDE, base-type=uint8, compu {phys=raw}, range phys 0..252
          signal TPDiagnosisFlashFBD_VMIPB_Byte19: start 152, 8 bit, little-endian, data-type-policy=OVERRIDE, base-type=uint8, compu {phys=raw}, range phys 0..252
          signal TPDiagnosisFlashFBD_VMIPB_Byte20: start 160, 8 bit, little-endian, data-type-policy=OVERRIDE, base-type=uint8, compu {phys=raw}, range phys 0..252
          signal TPDiagnosisFlashFBD_VMIPB_Byte21: start 168, 8 bit, little-endian, data-type-policy=OVERRIDE, base-type=uint8, compu {phys=raw}, range phys 0..252
          signal TPDiagnosisFlashFBD_VMIPB_Byte22: start 176, 8 bit, little-endian, data-type-policy=OVERRIDE, base-type=uint8, compu {phys=raw}, range phys 0..252
          signal TPDiagnosisFlashFBD_VMIPB_Byte23: start 184, 8 bit, little-endian, data-type-policy=OVERRIDE, base-type=uint8, compu {phys=raw}, range phys 0..252
          signal TPDiagnosisFlashFBD_VMIPB_Byte24: start 192, 8 bit, little-endian, data-type-policy=OVERRIDE, base-type=uint8, compu {phys=raw}, range phys 0..252
          signal TPDiagnosisFlashFBD_VMIPB_Byte25: start 200, 8 bit, little-endian, data-type-policy=OVERRIDE, base-type=uint8, compu {phys=raw}, range phys 0..252
          signal TPDiagnosisFlashFBD_VMIPB_Byte26: start 208, 8 bit, little-endian, data-type-policy=OVERRIDE, base-type=uint8, compu {phys=raw}, range phys 0..252
          signal TPDiagnosisFlashFBD_VMIPB_Byte27: start 216, 8 bit, little-endian, data-type-policy=OVERRIDE, base-type=uint8, compu {phys=raw}, range phys 0..252
          signal TPDiagnosisFlashFBD_VMIPB_Byte28: start 224, 8 bit, little-endian, data-type-policy=OVERRIDE, base-type=uint8, compu {phys=raw}, range phys 0..252
          signal TPDiagnosisFlashFBD_VMIPB_Byte29: start 232, 8 bit, little-endian, data-type-policy=OVERRIDE, base-type=uint8, compu {phys=raw}, range phys 0..252
          signal TPDiagnosisFlashFBD_VMIPB_Byte30: start 240, 8 bit, little-endian, data-type-policy=OVERRIDE, base-type=uint8, compu {phys=raw}, range phys 0..252
          signal TPDiagnosisFlashFBD_VMIPB_Byte31: start 248, 8 bit, little-endian, data-type-policy=OVERRIDE, base-type=uint8, compu {phys=raw}, range phys 0..252
          signal TPDiagnosisFlashFBD_VMIPB_Byte32: start 256, 8 bit, little-endian, data-type-policy=OVERRIDE, base-type=uint8, compu {phys=raw}, range phys 0..252
          signal TPDiagnosisFlashFBD_VMIPB_Byte33: start 264, 8 bit, little-endian, data-type-policy=OVERRIDE, base-type=uint8, compu {phys=raw}, range phys 0..252
          signal TPDiagnosisFlashFBD_VMIPB_Byte34: start 272, 8 bit, little-endian, data-type-policy=OVERRIDE, base-type=uint8, compu {phys=raw}, range phys 0..252
          signal TPDiagnosisFlashFBD_VMIPB_Byte35: start 280, 8 bit, little-endian, data-type-policy=OVERRIDE, base-type=uint8, compu {phys=raw}, range phys 0..252
          signal TPDiagnosisFlashFBD_VMIPB_Byte36: start 288, 8 bit, little-endian, data-type-policy=OVERRIDE, base-type=uint8, compu {phys=raw}, range phys 0..252
          signal TPDiagnosisFlashFBD_VMIPB_Byte37: start 296, 8 bit, little-endian, data-type-policy=OVERRIDE, base-type=uint8, compu {phys=raw}, range phys 0..252
          signal TPDiagnosisFlashFBD_VMIPB_Byte38: start 304, 8 bit, little-endian, data-type-policy=OVERRIDE, base-type=uint8, compu {phys=raw}, range phys 0..252
          signal TPDiagnosisFlashFBD_VMIPB_Byte39: start 312, 8 bit, little-endian, data-type-policy=OVERRIDE, base-type=uint8, compu {phys=raw}, range phys 0..252
          signal TPDiagnosisFlashFBD_VMIPB_Byte40: start 320, 8 bit, little-endian, data-type-policy=OVERRIDE, base-type=uint8, compu {phys=raw}, range phys 0..252
          signal TPDiagnosisFlashFBD_VMIPB_Byte41: start 328, 8 bit, little-endian, data-type-policy=OVERRIDE, base-type=uint8, compu {phys=raw}, range phys 0..252
          signal TPDiagnosisFlashFBD_VMIPB_Byte42: start 336, 8 bit, little-endian, data-type-policy=OVERRIDE, base-type=uint8, compu {phys=raw}, range phys 0..252
          signal TPDiagnosisFlashFBD_VMIPB_Byte43: start 344, 8 bit, little-endian, data-type-policy=OVERRIDE, base-type=uint8, compu {phys=raw}, range phys 0..252
          signal TPDiagnosisFlashFBD_VMIPB_Byte44: start 352, 8 bit, little-endian, data-type-policy=OVERRIDE, base-type=uint8, compu {phys=raw}, range phys 0..252
          signal TPDiagnosisFlashFBD_VMIPB_Byte45: start 360, 8 bit, little-endian, data-type-policy=OVERRIDE, base-type=uint8, compu {phys=raw}, range phys 0..252
          signal TPDiagnosisFlashFBD_VMIPB_Byte46: start 368, 8 bit, little-endian, data-type-policy=OVERRIDE, base-type=uint8, compu {phys=raw}, range phys 0..252
          signal TPDiagnosisFlashFBD_VMIPB_Byte47: start 376, 8 bit, little-endian, data-type-policy=OVERRIDE, base-type=uint8, compu {phys=raw}, range phys 0..252
          signal TPDiagnosisFlashFBD_VMIPB_Byte48: start 384, 8 bit, little-endian, data-type-policy=OVERRIDE, base-type=uint8, compu {phys=raw}, range phys 0..252
          signal TPDiagnosisFlashFBD_VMIPB_Byte49: start 392, 8 bit, little-endian, data-type-policy=OVERRIDE, base-type=uint8, compu {phys=raw}, range phys 0..252
          signal TPDiagnosisFlashFBD_VMIPB_Byte50: start 400, 8 bit, little-endian, data-type-policy=OVERRIDE, base-type=uint8, compu {phys=raw}, range phys 0..252
          signal TPDiagnosisFlashFBD_VMIPB_Byte51: start 408, 8 bit, little-endian, data-type-policy=OVERRIDE, base-type=uint8, compu {phys=raw}, range phys 0..252
          signal TPDiagnosisFlashFBD_VMIPB_Byte52: start 416, 8 bit, little-endian, data-type-policy=OVERRIDE, base-type=uint8, compu {phys=raw}, range phys 0..252
          signal TPDiagnosisFlashFBD_VMIPB_Byte53: start 424, 8 bit, little-endian, data-type-policy=OVERRIDE, base-type=uint8, compu {phys=raw}, range phys 0..252
          signal TPDiagnosisFlashFBD_VMIPB_Byte54: start 432, 8 bit, little-endian, data-type-policy=OVERRIDE, base-type=uint8, compu {phys=raw}, range phys 0..252
          signal TPDiagnosisFlashFBD_VMIPB_Byte55: start 440, 8 bit, little-endian, data-type-policy=OVERRIDE, base-type=uint8, compu {phys=raw}, range phys 0..252
          signal TPDiagnosisFlashFBD_VMIPB_Byte56: start 448, 8 bit, little-endian, data-type-policy=OVERRIDE, base-type=uint8, compu {phys=raw}, range phys 0..252
          signal TPDiagnosisFlashFBD_VMIPB_Byte57: start 456, 8 bit, little-endian, data-type-policy=OVERRIDE, base-type=uint8, compu {phys=raw}, range phys 0..252
          signal TPDiagnosisFlashFBD_VMIPB_Byte58: start 464, 8 bit, little-endian, data-type-policy=OVERRIDE, base-type=uint8, compu {phys=raw}, range phys 0..252
          signal TPDiagnosisFlashFBD_VMIPB_Byte59: start 472, 8 bit, little-endian, data-type-policy=OVERRIDE, base-type=uint8, compu {phys=raw}, range phys 0..252
          signal TPDiagnosisFlashFBD_VMIPB_Byte60: start 480, 8 bit, little-endian, data-type-policy=OVERRIDE, base-type=uint8, compu {phys=raw}, range phys 0..252
          signal TPDiagnosisFlashFBD_VMIPB_Byte61: start 488, 8 bit, little-endian, data-type-policy=OVERRIDE, base-type=uint8, compu {phys=raw}, range phys 0..252
          signal TPDiagnosisFlashFBD_VMIPB_Byte62: start 496, 8 bit, little-endian, data-type-policy=OVERRIDE, base-type=uint8, compu {phys=raw}, range phys 0..252
          signal TPDiagnosisFlashFBD_VMIPB_Byte63: start 504, 8 bit, little-endian, data-type-policy=OVERRIDE, base-type=uint8, compu {phys=raw}, range phys 0..252
      frame TPDiagnosisFlash_FBD_VR_IPB: id 0x2CB, frame-length=64, can-addressing-mode=STANDARD, can-frame-rx-behavior=CAN-FD, can-frame-tx-behavior=CAN-FD
        pdu TPDiagnosisFlash_FBD_VR_IPB: length=64, unused-bit-pattern=0
          signal TPDiagnosisFlashFBD_VRIPB_Byte00: start 0, 8 bit, little-endian, data-type-policy=OVERRIDE, base-type=uint8, compu {phys=raw}, range phys 0..252
          signal TPDiagnosisFlashFBD_VRIPB_Byte01: start 8, 8 bit, little-endian, data-type-policy=OVERRIDE, base-type=uint8, compu {phys=raw}, range phys 0..252
          signal TPDiagnosisFlashFBD_VRIPB_Byte02: start 16, 8 bit, little-endian, data-type-policy=OVERRIDE, base-type=uint8, compu {phys=raw}, range phys 0..252
          signal TPDiagnosisFlashFBD_VRIPB_Byte03: start 24, 8 bit, little-endian, data-type-policy=OVERRIDE, base-type=uint8, compu {phys=raw}, range phys 0..252
          signal TPDiagnosisFlashFBD_VRIPB_Byte04: start 32, 8 bit, little-endian, data-type-policy=OVERRIDE, base-type=uint8, compu {phys=raw}, range phys 0..252
          signal TPDiagnosisFlashFBD_VRIPB_Byte05: start 40, 8 bit, little-endian, data-type-policy=OVERRIDE, base-type=uint8, compu {phys=raw}, range phys 0..252
          signal TPDiagnosisFlashFBD_VRIPB_Byte06: start 48, 8 bit, little-endian, data-type-policy=OVERRIDE, base-type=uint8, compu {phys=raw}, range phys 0..252
          signal TPDiagnosisFlashFBD_VRIPB_Byte07: start 56, 8 bit, little-endian, data-type-policy=OVERRIDE, base-type=uint8, compu {phys=raw}, range phys 0..252
          signal TPDiagnosisFlashFBD_VRIPB_Byte08: start 64, 8 bit, little-endian, data-type-policy=OVERRIDE, base-type=uint8, compu {phys=raw}, range phys 0..252
          signal TPDiagnosisFlashFBD_VRIPB_Byte09: start 72, 8 bit, little-endian, data-type-policy=OVERRIDE, base-type=uint8, compu {phys=raw}, range phys 0..252
          signal TPDiagnosisFlashFBD_VRIPB_Byte10: start 80, 8 bit, little-endian, data-type-policy=OVERRIDE, base-type=uint8, compu {phys=raw}, range phys 0..252
          signal TPDiagnosisFlashFBD_VRIPB_Byte11: start 88, 8 bit, little-endian, data-type-policy=OVERRIDE, base-type=uint8, compu {phys=raw}, range phys 0..252
          signal TPDiagnosisFlashFBD_VRIPB_Byte12: start 96, 8 bit, little-endian, data-type-policy=OVERRIDE, base-type=uint8, compu {phys=raw}, range phys 0..252
          signal TPDiagnosisFlashFBD_VRIPB_Byte13: start 104, 8 bit, little-endian, data-type-policy=OVERRIDE, base-type=uint8, compu {phys=raw}, range phys 0..252
          signal TPDiagnosisFlashFBD_VRIPB_Byte14: start 112, 8 bit, little-endian, data-type-policy=OVERRIDE, base-type=uint8, compu {phys=raw}, range phys 0..252
          signal TPDiagnosisFlashFBD_VRIPB_Byte15: start 120, 8 bit, little-endian, data-type-policy=OVERRIDE, base-type=uint8, compu {phys=raw}, range phys 0..252
          signal TPDiagnosisFlashFBD_VRIPB_Byte16: start 128, 8 bit, little-endian, data-type-policy=OVERRIDE, base-type=uint8, compu {phys=raw}, range phys 0..252
          signal TPDiagnosisFlashFBD_VRIPB_Byte17: start 136, 8 bit, little-endian, data-type-policy=OVERRIDE, base-type=uint8, compu {phys=raw}, range phys 0..252
          signal TPDiagnosisFlashFBD_VRIPB_Byte18: start 144, 8 bit, little-endian, data-type-policy=OVERRIDE, base-type=uint8, compu {phys=raw}, range phys 0..252
          signal TPDiagnosisFlashFBD_VRIPB_Byte19: start 152, 8 bit, little-endian, data-type-policy=OVERRIDE, base-type=uint8, compu {phys=raw}, range phys 0..252
          signal TPDiagnosisFlashFBD_VRIPB_Byte20: start 160, 8 bit, little-endian, data-type-policy=OVERRIDE, base-type=uint8, compu {phys=raw}, range phys 0..252
          signal TPDiagnosisFlashFBD_VRIPB_Byte21: start 168, 8 bit, little-endian, data-type-policy=OVERRIDE, base-type=uint8, compu {phys=raw}, range phys 0..252
          signal TPDiagnosisFlashFBD_VRIPB_Byte22: start 176, 8 bit, little-endian, data-type-policy=OVERRIDE, base-type=uint8, compu {phys=raw}, range phys 0..252
          signal TPDiagnosisFlashFBD_VRIPB_Byte23: start 184, 8 bit, little-endian, data-type-policy=OVERRIDE, base-type=uint8, compu {phys=raw}, range phys 0..252
          signal TPDiagnosisFlashFBD_VRIPB_Byte24: start 192, 8 bit, little-endian, data-type-policy=OVERRIDE, base-type=uint8, compu {phys=raw}, range phys 0..252
          signal TPDiagnosisFlashFBD_VRIPB_Byte25: start 200, 8 bit, little-endian, data-type-policy=OVERRIDE, base-type=uint8, compu {phys=raw}, range phys 0..252
          signal TPDiagnosisFlashFBD_VRIPB_Byte26: start 208, 8 bit, little-endian, data-type-policy=OVERRIDE, base-type=uint8, compu {phys=raw}, range phys 0..252
          signal TPDiagnosisFlashFBD_VRIPB_Byte27: start 216, 8 bit, little-endian, data-type-policy=OVERRIDE, base-type=uint8, compu {phys=raw}, range phys 0..252
          signal TPDiagnosisFlashFBD_VRIPB_Byte28: start 224, 8 bit, little-endian, data-type-policy=OVERRIDE, base-type=uint8, compu {phys=raw}, range phys 0..252
          signal TPDiagnosisFlashFBD_VRIPB_Byte29: start 232, 8 bit, little-endian, data-type-policy=OVERRIDE, base-type=uint8, compu {phys=raw}, range phys 0..252
          signal TPDiagnosisFlashFBD_VRIPB_Byte30: start 240, 8 bit, little-endian, data-type-policy=OVERRIDE, base-type=uint8, compu {phys=raw}, range phys 0..252
          signal TPDiagnosisFlashFBD_VRIPB_Byte31: start 248, 8 bit, little-endian, data-type-policy=OVERRIDE, base-type=uint8, compu {phys=raw}, range phys 0..252
          signal TPDiagnosisFlashFBD_VRIPB_Byte32: start 256, 8 bit, little-endian, data-type-policy=OVERRIDE, base-type=uint8, compu {phys=raw}, range phys 0..252
          signal TPDiagnosisFlashFBD_VRIPB_Byte33: start 264, 8 bit, little-endian, data-type-policy=OVERRIDE, base-type=uint8, compu {phys=raw}, range phys 0..252
          signal TPDiagnosisFlashFBD_VRIPB_Byte34: start 272, 8 bit, little-endian, data-type-policy=OVERRIDE, base-type=uint8, compu {phys=raw}, range phys 0..252
          signal TPDiagnosisFlashFBD_VRIPB_Byte35: start 280, 8 bit, little-endian, data-type-policy=OVERRIDE, base-type=uint8, compu {phys=raw}, range phys 0..252
          signal TPDiagnosisFlashFBD_VRIPB_Byte36: start 288, 8 bit, little-endian, data-type-policy=OVERRIDE, base-type=uint8, compu {phys=raw}, range phys 0..252
          signal TPDiagnosisFlashFBD_VRIPB_Byte37: start 296, 8 bit, little-endian, data-type-policy=OVERRIDE, base-type=uint8, compu {phys=raw}, range phys 0..252
          signal TPDiagnosisFlashFBD_VRIPB_Byte38: start 304, 8 bit, little-endian, data-type-policy=OVERRIDE, base-type=uint8, compu {phys=raw}, range phys 0..252
          signal TPDiagnosisFlashFBD_VRIPB_Byte39: start 312, 8 bit, little-endian, data-type-policy=OVERRIDE, base-type=uint8, compu {phys=raw}, range phys 0..252
          signal TPDiagnosisFlashFBD_VRIPB_Byte40: start 320, 8 bit, little-endian, data-type-policy=OVERRIDE, base-type=uint8, compu {phys=raw}, range phys 0..252
          signal TPDiagnosisFlashFBD_VRIPB_Byte41: start 328, 8 bit, little-endian, data-type-policy=OVERRIDE, base-type=uint8, compu {phys=raw}, range phys 0..252
          signal TPDiagnosisFlashFBD_VRIPB_Byte42: start 336, 8 bit, little-endian, data-type-policy=OVERRIDE, base-type=uint8, compu {phys=raw}, range phys 0..252
          signal TPDiagnosisFlashFBD_VRIPB_Byte43: start 344, 8 bit, little-endian, data-type-policy=OVERRIDE, base-type=uint8, compu {phys=raw}, range phys 0..252
          signal TPDiagnosisFlashFBD_VRIPB_Byte44: start 352, 8 bit, little-endian, data-type-policy=OVERRIDE, base-type=uint8, compu {phys=raw}, range phys 0..252
          signal TPDiagnosisFlashFBD_VRIPB_Byte45: start 360, 8 bit, little-endian, data-type-policy=OVERRIDE, base-type=uint8, compu {phys=raw}, range phys 0..252
          signal TPDiagnosisFlashFBD_VRIPB_Byte46: start 368, 8 bit, little-endian, data-type-policy=OVERRIDE, base-type=uint8, compu {phys=raw}, range phys 0..252
          signal TPDiagnosisFlashFBD_VRIPB_Byte47: start 376, 8 bit, little-endian, data-type-policy=OVERRIDE, base-type=uint8, compu {phys=raw}, range phys 0..252
          signal TPDiagnosisFlashFBD_VRIPB_Byte48: start 384, 8 bit, little-endian, data-type-policy=OVERRIDE, base-type=uint8, compu {phys=raw}, range phys 0..252
          signal TPDiagnosisFlashFBD_VRIPB_Byte49: start 392, 8 bit, little-endian, data-type-policy=OVERRIDE, base-type=uint8, compu {phys=raw}, range phys 0..252
          signal TPDiagnosisFlashFBD_VRIPB_Byte50: start 400, 8 bit, little-endian, data-type-policy=OVERRIDE, base-type=uint8, compu {phys=raw}, range phys 0..252
          signal TPDiagnosisFlashFBD_VRIPB_Byte51: start 408, 8 bit, little-endian, data-type-policy=OVERRIDE, base-type=uint8, compu {phys=raw}, range phys 0..252
          signal TPDiagnosisFlashFBD_VRIPB_Byte52: start 416, 8 bit, little-endian, data-type-policy=OVERRIDE, base-type=uint8, compu {phys=raw}, range phys 0..252
          signal TPDiagnosisFlashFBD_VRIPB_Byte53: start 424, 8 bit, little-endian, data-type-policy=OVERRIDE, base-type=uint8, compu {phys=raw}, range phys 0..252
          signal TPDiagnosisFlashFBD_VRIPB_Byte54: start 432, 8 bit, little-endian, data-type-policy=OVERRIDE, base-type=uint8, compu {phys=raw}, range phys 0..252
          signal TPDiagnosisFlashFBD_VRIPB_Byte55: start 440, 8 bit, little-endian, data-type-policy=OVERRIDE, base-type=uint8, compu {phys=raw}, range phys 0..252
          signal TPDiagnosisFlashFBD_VRIPB_Byte56: start 448, 8 bit, little-endian, data-type-policy=OVERRIDE, base-type=uint8, compu {phys=raw}, range phys 0..252
          signal TPDiagnosisFlashFBD_VRIPB_Byte57: start 456, 8 bit, little-endian, data-type-policy=OVERRIDE, base-type=uint8, compu {phys=raw}, range phys 0..252
          signal TPDiagnosisFlashFBD_VRIPB_Byte58: start 464, 8 bit, little-endian, data-type-policy=OVERRIDE, base-type=uint8, compu {phys=raw}, range phys 0..252
          signal TPDiagnosisFlashFBD_VRIPB_Byte59: start 472, 8 bit, little-endian, data-type-policy=OVERRIDE, base-type=uint8, compu {phys=raw}, range phys 0..252
          signal TPDiagnosisFlashFBD_VRIPB_Byte60: start 480, 8 bit, little-endian, data-type-policy=OVERRIDE, base-type=uint8, compu {phys=raw}, range phys 0..252
          signal TPDiagnosisFlashFBD_VRIPB_Byte61: start 488, 8 bit, little-endian, data-type-policy=OVERRIDE, base-type=uint8, compu {phys=raw}, range phys 0..252
          signal TPDiagnosisFlashFBD_VRIPB_Byte62: start 496, 8 bit, little-endian, data-type-policy=OVERRIDE, base-type=uint8, compu {phys=raw}, range phys 0..252
          signal TPDiagnosisFlashFBD_VRIPB_Byte63: start 504, 8 bit, little-endian, data-type-policy=OVERRIDE, base-type=uint8, compu {phys=raw}, range phys 0..252
      frame TPDiagnosisFlash_IPB_FBD_HL: id 0x2C2, frame-length=64, can-addressing-mode=STANDARD, can-frame-rx-behavior=CAN-FD, can-frame-tx-behavior=CAN-FD
        pdu TPDiagnosisFlash_IPB_FBD_HL: length=64, unused-bit-pattern=0
          signal TPDiagnosisFlashIPBFBD_HL_Byte00: start 0, 8 bit, little-endian, data-type-policy=OVERRIDE, base-type=uint8, compu {phys=raw}, range phys 0..252
          signal TPDiagnosisFlashIPBFBD_HL_Byte01: start 8, 8 bit, little-endian, data-type-policy=OVERRIDE, base-type=uint8, compu {phys=raw}, range phys 0..252
          signal TPDiagnosisFlashIPBFBD_HL_Byte02: start 16, 8 bit, little-endian, data-type-policy=OVERRIDE, base-type=uint8, compu {phys=raw}, range phys 0..252
          signal TPDiagnosisFlashIPBFBD_HL_Byte03: start 24, 8 bit, little-endian, data-type-policy=OVERRIDE, base-type=uint8, compu {phys=raw}, range phys 0..252
          signal TPDiagnosisFlashIPBFBD_HL_Byte04: start 32, 8 bit, little-endian, data-type-policy=OVERRIDE, base-type=uint8, compu {phys=raw}, range phys 0..252
          signal TPDiagnosisFlashIPBFBD_HL_Byte05: start 40, 8 bit, little-endian, data-type-policy=OVERRIDE, base-type=uint8, compu {phys=raw}, range phys 0..252
          signal TPDiagnosisFlashIPBFBD_HL_Byte06: start 48, 8 bit, little-endian, data-type-policy=OVERRIDE, base-type=uint8, compu {phys=raw}, range phys 0..252
          signal TPDiagnosisFlashIPBFBD_HL_Byte07: start 56, 8 bit, little-endian, data-type-policy=OVERRIDE, base-type=uint8, compu {phys=raw}, range phys 0..252
          signal TPDiagnosisFlashIPBFBD_HL_Byte08: start 64, 8 bit, little-endian, data-type-policy=OVERRIDE, base-type=uint8, compu {phys=raw}, range phys 0..252
          signal TPDiagnosisFlashIPBFBD_HL_Byte09: start 72, 8 bit, little-endian, data-type-policy=OVERRIDE, base-type=uint8, compu {phys=raw}, range phys 0..252
          signal TPDiagnosisFlashIPBFBD_HL_Byte10: start 80, 8 bit, little-endian, data-type-policy=OVERRIDE, base-type=uint8, compu {phys=raw}, range phys 0..252
          signal TPDiagnosisFlashIPBFBD_HL_Byte11: start 88, 8 bit, little-endian, data-type-policy=OVERRIDE, base-type=uint8, compu {phys=raw}, range phys 0..252
          signal TPDiagnosisFlashIPBFBD_HL_Byte12: start 96, 8 bit, little-endian, data-type-policy=OVERRIDE, base-type=uint8, compu {phys=raw}, range phys 0..252
          signal TPDiagnosisFlashIPBFBD_HL_Byte13: start 104, 8 bit, little-endian, data-type-policy=OVERRIDE, base-type=uint8, compu {phys=raw}, range phys 0..252
          signal TPDiagnosisFlashIPBFBD_HL_Byte14: start 112, 8 bit, little-endian, data-type-policy=OVERRIDE, base-type=uint8, compu {phys=raw}, range phys 0..252
          signal TPDiagnosisFlashIPBFBD_HL_Byte15: start 120, 8 bit, little-endian, data-type-policy=OVERRIDE, base-type=uint8, compu {phys=raw}, range phys 0..252
          signal TPDiagnosisFlashIPBFBD_HL_Byte16: start 128, 8 bit, little-endian, data-type-policy=OVERRIDE, base-type=uint8, compu {phys=raw}, range phys 0..252
          signal TPDiagnosisFlashIPBFBD_HL_Byte17: start 136, 8 bit, little-endian, data-type-policy=OVERRIDE, base-type=uint8, compu {phys=raw}, range phys 0..252
          signal TPDiagnosisFlashIPBFBD_HL_Byte18: start 144, 8 bit, little-endian, data-type-policy=OVERRIDE, base-type=uint8, compu {phys=raw}, range phys 0..252
          signal TPDiagnosisFlashIPBFBD_HL_Byte19: start 152, 8 bit, little-endian, data-type-policy=OVERRIDE, base-type=uint8, compu {phys=raw}, range phys 0..252
          signal TPDiagnosisFlashIPBFBD_HL_Byte20: start 160, 8 bit, little-endian, data-type-policy=OVERRIDE, base-type=uint8, compu {phys=raw}, range phys 0..252
          signal TPDiagnosisFlashIPBFBD_HL_Byte21: start 168, 8 bit, little-endian, data-type-policy=OVERRIDE, base-type=uint8, compu {phys=raw}, range phys 0..252
          signal TPDiagnosisFlashIPBFBD_HL_Byte22: start 176, 8 bit, little-endian, data-type-policy=OVERRIDE, base-type=uint8, compu {phys=raw}, range phys 0..252
          signal TPDiagnosisFlashIPBFBD_HL_Byte23: start 184, 8 bit, little-endian, data-type-policy=OVERRIDE, base-type=uint8, compu {phys=raw}, range phys 0..252
          signal TPDiagnosisFlashIPBFBD_HL_Byte24: start 192, 8 bit, little-endian, data-type-policy=OVERRIDE, base-type=uint8, compu {phys=raw}, range phys 0..252
          signal TPDiagnosisFlashIPBFBD_HL_Byte25: start 200, 8 bit, little-endian, data-type-policy=OVERRIDE, base-type=uint8, compu {phys=raw}, range phys 0..252
          signal TPDiagnosisFlashIPBFBD_HL_Byte26: start 208, 8 bit, little-endian, data-type-policy=OVERRIDE, base-type=uint8, compu {phys=raw}, range phys 0..252
          signal TPDiagnosisFlashIPBFBD_HL_Byte27: start 216, 8 bit, little-endian, data-type-policy=OVERRIDE, base-type=uint8, compu {phys=raw}, range phys 0..252
          signal TPDiagnosisFlashIPBFBD_HL_Byte28: start 224, 8 bit, little-endian, data-type-policy=OVERRIDE, base-type=uint8, compu {phys=raw}, range phys 0..252
          signal TPDiagnosisFlashIPBFBD_HL_Byte29: start 232, 8 bit, little-endian, data-type-policy=OVERRIDE, base-type=uint8, compu {phys=raw}, range phys 0..252
          signal TPDiagnosisFlashIPBFBD_HL_Byte30: start 240, 8 bit, little-endian, data-type-policy=OVERRIDE, base-type=uint8, compu {phys=raw}, range phys 0..252
          signal TPDiagnosisFlashIPBFBD_HL_Byte31: start 248, 8 bit, little-endian, data-type-policy=OVERRIDE, base-type=uint8, compu {phys=raw}, range phys 0..252
          signal TPDiagnosisFlashIPBFBD_HL_Byte32: start 256, 8 bit, little-endian, data-type-policy=OVERRIDE, base-type=uint8, compu {phys=raw}, range phys 0..252
          signal TPDiagnosisFlashIPBFBD_HL_Byte33: start 264, 8 bit, little-endian, data-type-policy=OVERRIDE, base-type=uint8, compu {phys=raw}, range phys 0..252
          signal TPDiagnosisFlashIPBFBD_HL_Byte34: start 272, 8 bit, little-endian, data-type-policy=OVERRIDE, base-type=uint8, compu {phys=raw}, range phys 0..252
          signal TPDiagnosisFlashIPBFBD_HL_Byte35: start 280, 8 bit, little-endian, data-type-policy=OVERRIDE, base-type=uint8, compu {phys=raw}, range phys 0..252
          signal TPDiagnosisFlashIPBFBD_HL_Byte36: start 288, 8 bit, little-endian, data-type-policy=OVERRIDE, base-type=uint8, compu {phys=raw}, range phys 0..252
          signal TPDiagnosisFlashIPBFBD_HL_Byte37: start 296, 8 bit, little-endian, data-type-policy=OVERRIDE, base-type=uint8, compu {phys=raw}, range phys 0..252
          signal TPDiagnosisFlashIPBFBD_HL_Byte38: start 304, 8 bit, little-endian, data-type-policy=OVERRIDE, base-type=uint8, compu {phys=raw}, range phys 0..252
          signal TPDiagnosisFlashIPBFBD_HL_Byte39: start 312, 8 bit, little-endian, data-type-policy=OVERRIDE, base-type=uint8, compu {phys=raw}, range phys 0..252
          signal TPDiagnosisFlashIPBFBD_HL_Byte40: start 320, 8 bit, little-endian, data-type-policy=OVERRIDE, base-type=uint8, compu {phys=raw}, range phys 0..252
          signal TPDiagnosisFlashIPBFBD_HL_Byte41: start 328, 8 bit, little-endian, data-type-policy=OVERRIDE, base-type=uint8, compu {phys=raw}, range phys 0..252
          signal TPDiagnosisFlashIPBFBD_HL_Byte42: start 336, 8 bit, little-endian, data-type-policy=OVERRIDE, base-type=uint8, compu {phys=raw}, range phys 0..252
          signal TPDiagnosisFlashIPBFBD_HL_Byte43: start 344, 8 bit, little-endian, data-type-policy=OVERRIDE, base-type=uint8, compu {phys=raw}, range phys 0..252
          signal TPDiagnosisFlashIPBFBD_HL_Byte44: start 352, 8 bit, little-endian, data-type-policy=OVERRIDE, base-type=uint8, compu {phys=raw}, range phys 0..252
          signal TPDiagnosisFlashIPBFBD_HL_Byte45: start 360, 8 bit, little-endian, data-type-policy=OVERRIDE, base-type=uint8, compu {phys=raw}, range phys 0..252
          signal TPDiagnosisFlashIPBFBD_HL_Byte46: start 368, 8 bit, little-endian, data-type-policy=OVERRIDE, base-type=uint8, compu {phys=raw}, range phys 0..252
          signal TPDiagnosisFlashIPBFBD_HL_Byte47: start 376, 8 bit, little-endian, data-type-policy=OVERRIDE, base-type=uint8, compu {phys=raw}, range phys 0..252
          signal TPDiagnosisFlashIPBFBD_HL_Byte48: start 384, 8 bit, little-endian, data-type-policy=OVERRIDE, base-type=uint8, compu {phys=raw}, range phys 0..252
          signal TPDiagnosisFlashIPBFBD_HL_Byte49: start 392, 8 bit, little-endian, data-type-policy=OVERRIDE, base-type=uint8, compu {phys=raw}, range phys 0..252
          signal TPDiagnosisFlashIPBFBD_HL_Byte50: start 400, 8 bit, little-endian, data-type-policy=OVERRIDE, base-type=uint8, compu {phys=raw}, range phys 0..252
          signal TPDiagnosisFlashIPBFBD_HL_Byte51: start 408, 8 bit, little-endian, data-type-policy=OVERRIDE, base-type=uint8, compu {phys=raw}, range phys 0..252
          signal TPDiagnosisFlashIPBFBD_HL_Byte52: start 416, 8 bit, little-endian, data-type-policy=OVERRIDE, base-type=uint8, compu {phys=raw}, range phys 0..252
          signal TPDiagnosisFlashIPBFBD_HL_Byte53: start 424, 8 bit, little-endian, data-type-policy=OVERRIDE, base-type=uint8, compu {phys=raw}, range phys 0..252
          signal TPDiagnosisFlashIPBFBD_HL_Byte54: start 432, 8 bit, little-endian, data-type-policy=OVERRIDE, base-type=uint8, compu {phys=raw}, range phys 0..252
          signal TPDiagnosisFlashIPBFBD_HL_Byte55: start 440, 8 bit, little-endian, data-type-policy=OVERRIDE, base-type=uint8, compu {phys=raw}, range phys 0..252
          signal TPDiagnosisFlashIPBFBD_HL_Byte56: start 448, 8 bit, little-endian, data-type-policy=OVERRIDE, base-type=uint8, compu {phys=raw}, range phys 0..252
          signal TPDiagnosisFlashIPBFBD_HL_Byte57: start 456, 8 bit, little-endian, data-type-policy=OVERRIDE, base-type=uint8, compu {phys=raw}, range phys 0..252
          signal TPDiagnosisFlashIPBFBD_HL_Byte58: start 464, 8 bit, little-endian, data-type-policy=OVERRIDE, base-type=uint8, compu {phys=raw}, range phys 0..252
          signal TPDiagnosisFlashIPBFBD_HL_Byte59: start 472, 8 bit, little-endian, data-type-policy=OVERRIDE, base-type=uint8, compu {phys=raw}, range phys 0..252
          signal TPDiagnosisFlashIPBFBD_HL_Byte60: start 480, 8 bit, little-endian, data-type-policy=OVERRIDE, base-type=uint8, compu {phys=raw}, range phys 0..252
          signal TPDiagnosisFlashIPBFBD_HL_Byte61: start 488, 8 bit, little-endian, data-type-policy=OVERRIDE, base-type=uint8, compu {phys=raw}, range phys 0..252
          signal TPDiagnosisFlashIPBFBD_HL_Byte62: start 496, 8 bit, little-endian, data-type-policy=OVERRIDE, base-type=uint8, compu {phys=raw}, range phys 0..252
          signal TPDiagnosisFlashIPBFBD_HL_Byte63: start 504, 8 bit, little-endian, data-type-policy=OVERRIDE, base-type=uint8, compu {phys=raw}, range phys 0..252
      frame TPDiagnosisFlash_IPB_FBD_HM: id 0x2BD, frame-length=64, can-addressing-mode=STANDARD, can-frame-rx-behavior=CAN-FD, can-frame-tx-behavior=CAN-FD
        pdu TPDiagnosisFlash_IPB_FBD_HM: length=64, unused-bit-pattern=0
          signal TPDiagnosisFlashIPBFBD_HM_Byte00: start 0, 8 bit, little-endian, data-type-policy=OVERRIDE, base-type=uint8, compu {phys=raw}, range phys 0..252
          signal TPDiagnosisFlashIPBFBD_HM_Byte01: start 8, 8 bit, little-endian, data-type-policy=OVERRIDE, base-type=uint8, compu {phys=raw}, range phys 0..252
          signal TPDiagnosisFlashIPBFBD_HM_Byte02: start 16, 8 bit, little-endian, data-type-policy=OVERRIDE, base-type=uint8, compu {phys=raw}, range phys 0..252
          signal TPDiagnosisFlashIPBFBD_HM_Byte03: start 24, 8 bit, little-endian, data-type-policy=OVERRIDE, base-type=uint8, compu {phys=raw}, range phys 0..252
          signal TPDiagnosisFlashIPBFBD_HM_Byte04: start 32, 8 bit, little-endian, data-type-policy=OVERRIDE, base-type=uint8, compu {phys=raw}, range phys 0..252
          signal TPDiagnosisFlashIPBFBD_HM_Byte05: start 40, 8 bit, little-endian, data-type-policy=OVERRIDE, base-type=uint8, compu {phys=raw}, range phys 0..252
          signal TPDiagnosisFlashIPBFBD_HM_Byte06: start 48, 8 bit, little-endian, data-type-policy=OVERRIDE, base-type=uint8, compu {phys=raw}, range phys 0..252
          signal TPDiagnosisFlashIPBFBD_HM_Byte07: start 56, 8 bit, little-endian, data-type-policy=OVERRIDE, base-type=uint8, compu {phys=raw}, range phys 0..252
          signal TPDiagnosisFlashIPBFBD_HM_Byte08: start 64, 8 bit, little-endian, data-type-policy=OVERRIDE, base-type=uint8, compu {phys=raw}, range phys 0..252
          signal TPDiagnosisFlashIPBFBD_HM_Byte09: start 72, 8 bit, little-endian, data-type-policy=OVERRIDE, base-type=uint8, compu {phys=raw}, range phys 0..252
          signal TPDiagnosisFlashIPBFBD_HM_Byte10: start 80, 8 bit, little-endian, data-type-policy=OVERRIDE, base-type=uint8, compu {phys=raw}, range phys 0..252
          signal TPDiagnosisFlashIPBFBD_HM_Byte11: start 88, 8 bit, little-endian, data-type-policy=OVERRIDE, base-type=uint8, compu {phys=raw}, range phys 0..252
          signal TPDiagnosisFlashIPBFBD_HM_Byte12: start 96, 8 bit, little-endian, data-type-policy=OVERRIDE, base-type=uint8, compu {phys=raw}, range phys 0..252
          signal TPDiagnosisFlashIPBFBD_HM_Byte13: start 104, 8 bit, little-endian, data-type-policy=OVERRIDE, base-type=uint8, compu {phys=raw}, range phys 0..252
          signal TPDiagnosisFlashIPBFBD_HM_Byte14: start 112, 8 bit, little-endian, data-type-policy=OVERRIDE, base-type=uint8, compu {phys=raw}, range phys 0..252
          signal TPDiagnosisFlashIPBFBD_HM_Byte15: start 120, 8 bit, little-endian, data-type-policy=OVERRIDE, base-type=uint8, compu {phys=raw}, range phys 0..252
          signal TPDiagnosisFlashIPBFBD_HM_Byte16: start 128, 8 bit, little-endian, data-type-policy=OVERRIDE, base-type=uint8, compu {phys=raw}, range phys 0..252
          signal TPDiagnosisFlashIPBFBD_HM_Byte17: start 136, 8 bit, little-endian, data-type-policy=OVERRIDE, base-type=uint8, compu {phys=raw}, range phys 0..252
          signal TPDiagnosisFlashIPBFBD_HM_Byte18: start 144, 8 bit, little-endian, data-type-policy=OVERRIDE, base-type=uint8, compu {phys=raw}, range phys 0..252
          signal TPDiagnosisFlashIPBFBD_HM_Byte19: start 152, 8 bit, little-endian, data-type-policy=OVERRIDE, base-type=uint8, compu {phys=raw}, range phys 0..252
          signal TPDiagnosisFlashIPBFBD_HM_Byte20: start 160, 8 bit, little-endian, data-type-policy=OVERRIDE, base-type=uint8, compu {phys=raw}, range phys 0..252
          signal TPDiagnosisFlashIPBFBD_HM_Byte21: start 168, 8 bit, little-endian, data-type-policy=OVERRIDE, base-type=uint8, compu {phys=raw}, range phys 0..252
          signal TPDiagnosisFlashIPBFBD_HM_Byte22: start 176, 8 bit, little-endian, data-type-policy=OVERRIDE, base-type=uint8, compu {phys=raw}, range phys 0..252
          signal TPDiagnosisFlashIPBFBD_HM_Byte23: start 184, 8 bit, little-endian, data-type-policy=OVERRIDE, base-type=uint8, compu {phys=raw}, range phys 0..252
          signal TPDiagnosisFlashIPBFBD_HM_Byte24: start 192, 8 bit, little-endian, data-type-policy=OVERRIDE, base-type=uint8, compu {phys=raw}, range phys 0..252
          signal TPDiagnosisFlashIPBFBD_HM_Byte25: start 200, 8 bit, little-endian, data-type-policy=OVERRIDE, base-type=uint8, compu {phys=raw}, range phys 0..252
          signal TPDiagnosisFlashIPBFBD_HM_Byte26: start 208, 8 bit, little-endian, data-type-policy=OVERRIDE, base-type=uint8, compu {phys=raw}, range phys 0..252
          signal TPDiagnosisFlashIPBFBD_HM_Byte27: start 216, 8 bit, little-endian, data-type-policy=OVERRIDE, base-type=uint8, compu {phys=raw}, range phys 0..252
          signal TPDiagnosisFlashIPBFBD_HM_Byte28: start 224, 8 bit, little-endian, data-type-policy=OVERRIDE, base-type=uint8, compu {phys=raw}, range phys 0..252
          signal TPDiagnosisFlashIPBFBD_HM_Byte29: start 232, 8 bit, little-endian, data-type-policy=OVERRIDE, base-type=uint8, compu {phys=raw}, range phys 0..252
          signal TPDiagnosisFlashIPBFBD_HM_Byte30: start 240, 8 bit, little-endian, data-type-policy=OVERRIDE, base-type=uint8, compu {phys=raw}, range phys 0..252
          signal TPDiagnosisFlashIPBFBD_HM_Byte31: start 248, 8 bit, little-endian, data-type-policy=OVERRIDE, base-type=uint8, compu {phys=raw}, range phys 0..252
          signal TPDiagnosisFlashIPBFBD_HM_Byte32: start 256, 8 bit, little-endian, data-type-policy=OVERRIDE, base-type=uint8, compu {phys=raw}, range phys 0..252
          signal TPDiagnosisFlashIPBFBD_HM_Byte33: start 264, 8 bit, little-endian, data-type-policy=OVERRIDE, base-type=uint8, compu {phys=raw}, range phys 0..252
          signal TPDiagnosisFlashIPBFBD_HM_Byte34: start 272, 8 bit, little-endian, data-type-policy=OVERRIDE, base-type=uint8, compu {phys=raw}, range phys 0..252
          signal TPDiagnosisFlashIPBFBD_HM_Byte35: start 280, 8 bit, little-endian, data-type-policy=OVERRIDE, base-type=uint8, compu {phys=raw}, range phys 0..252
          signal TPDiagnosisFlashIPBFBD_HM_Byte36: start 288, 8 bit, little-endian, data-type-policy=OVERRIDE, base-type=uint8, compu {phys=raw}, range phys 0..252
          signal TPDiagnosisFlashIPBFBD_HM_Byte37: start 296, 8 bit, little-endian, data-type-policy=OVERRIDE, base-type=uint8, compu {phys=raw}, range phys 0..252
          signal TPDiagnosisFlashIPBFBD_HM_Byte38: start 304, 8 bit, little-endian, data-type-policy=OVERRIDE, base-type=uint8, compu {phys=raw}, range phys 0..252
          signal TPDiagnosisFlashIPBFBD_HM_Byte39: start 312, 8 bit, little-endian, data-type-policy=OVERRIDE, base-type=uint8, compu {phys=raw}, range phys 0..252
          signal TPDiagnosisFlashIPBFBD_HM_Byte40: start 320, 8 bit, little-endian, data-type-policy=OVERRIDE, base-type=uint8, compu {phys=raw}, range phys 0..252
          signal TPDiagnosisFlashIPBFBD_HM_Byte41: start 328, 8 bit, little-endian, data-type-policy=OVERRIDE, base-type=uint8, compu {phys=raw}, range phys 0..252
          signal TPDiagnosisFlashIPBFBD_HM_Byte42: start 336, 8 bit, little-endian, data-type-policy=OVERRIDE, base-type=uint8, compu {phys=raw}, range phys 0..252
          signal TPDiagnosisFlashIPBFBD_HM_Byte43: start 344, 8 bit, little-endian, data-type-policy=OVERRIDE, base-type=uint8, compu {phys=raw}, range phys 0..252
          signal TPDiagnosisFlashIPBFBD_HM_Byte44: start 352, 8 bit, little-endian, data-type-policy=OVERRIDE, base-type=uint8, compu {phys=raw}, range phys 0..252
          signal TPDiagnosisFlashIPBFBD_HM_Byte45: start 360, 8 bit, little-endian, data-type-policy=OVERRIDE, base-type=uint8, compu {phys=raw}, range phys 0..252
          signal TPDiagnosisFlashIPBFBD_HM_Byte46: start 368, 8 bit, little-endian, data-type-policy=OVERRIDE, base-type=uint8, compu {phys=raw}, range phys 0..252
          signal TPDiagnosisFlashIPBFBD_HM_Byte47: start 376, 8 bit, little-endian, data-type-policy=OVERRIDE, base-type=uint8, compu {phys=raw}, range phys 0..252
          signal TPDiagnosisFlashIPBFBD_HM_Byte48: start 384, 8 bit, little-endian, data-type-policy=OVERRIDE, base-type=uint8, compu {phys=raw}, range phys 0..252
          signal TPDiagnosisFlashIPBFBD_HM_Byte49: start 392, 8 bit, little-endian, data-type-policy=OVERRIDE, base-type=uint8, compu {phys=raw}, range phys 0..252
          signal TPDiagnosisFlashIPBFBD_HM_Byte50: start 400, 8 bit, little-endian, data-type-policy=OVERRIDE, base-type=uint8, compu {phys=raw}, range phys 0..252
          signal TPDiagnosisFlashIPBFBD_HM_Byte51: start 408, 8 bit, little-endian, data-type-policy=OVERRIDE, base-type=uint8, compu {phys=raw}, range phys 0..252
          signal TPDiagnosisFlashIPBFBD_HM_Byte52: start 416, 8 bit, little-endian, data-type-policy=OVERRIDE, base-type=uint8, compu {phys=raw}, range phys 0..252
          signal TPDiagnosisFlashIPBFBD_HM_Byte53: start 424, 8 bit, little-endian, data-type-policy=OVERRIDE, base-type=uint8, compu {phys=raw}, range phys 0..252
          signal TPDiagnosisFlashIPBFBD_HM_Byte54: start 432, 8 bit, little-endian, data-type-policy=OVERRIDE, base-type=uint8, compu {phys=raw}, range phys 0..252
          signal TPDiagnosisFlashIPBFBD_HM_Byte55: start 440, 8 bit, little-endian, data-type-policy=OVERRIDE, base-type=uint8, compu {phys=raw}, range phys 0..252
          signal TPDiagnosisFlashIPBFBD_HM_Byte56: start 448, 8 bit, little-endian, data-type-policy=OVERRIDE, base-type=uint8, compu {phys=raw}, range phys 0..252
          signal TPDiagnosisFlashIPBFBD_HM_Byte57: start 456, 8 bit, little-endian, data-type-policy=OVERRIDE, base-type=uint8, compu {phys=raw}, range phys 0..252
          signal TPDiagnosisFlashIPBFBD_HM_Byte58: start 464, 8 bit, little-endian, data-type-policy=OVERRIDE, base-type=uint8, compu {phys=raw}, range phys 0..252
          signal TPDiagnosisFlashIPBFBD_HM_Byte59: start 472, 8 bit, little-endian, data-type-policy=OVERRIDE, base-type=uint8, compu {phys=raw}, range phys 0..252
          signal TPDiagnosisFlashIPBFBD_HM_Byte60: start 480, 8 bit, little-endian, data-type-policy=OVERRIDE, base-type=uint8, compu {phys=raw}, range phys 0..252
          signal TPDiagnosisFlashIPBFBD_HM_Byte61: start 488, 8 bit, little-endian, data-type-policy=OVERRIDE, base-type=uint8, compu {phys=raw}, range phys 0..252
          signal TPDiagnosisFlashIPBFBD_HM_Byte62: start 496, 8 bit, little-endian, data-type-policy=OVERRIDE, base-type=uint8, compu {phys=raw}, range phys 0..252
          signal TPDiagnosisFlashIPBFBD_HM_Byte63: start 504, 8 bit, little-endian, data-type-policy=OVERRIDE, base-type=uint8, compu {phys=raw}, range phys 0..252
      frame TPDiagnosisFlash_IPB_FBD_HR: id 0x2C3, frame-length=64, can-addressing-mode=STANDARD, can-frame-rx-behavior=CAN-FD, can-frame-tx-behavior=CAN-FD
        pdu TPDiagnosisFlash_IPB_FBD_HR: length=64, unused-bit-pattern=0
          signal TPDiagnosisFlashIPBFBD_HR_Byte00: start 0, 8 bit, little-endian, data-type-policy=OVERRIDE, base-type=uint8, compu {phys=raw}, range phys 0..252
          signal TPDiagnosisFlashIPBFBD_HR_Byte01: start 8, 8 bit, little-endian, data-type-policy=OVERRIDE, base-type=uint8, compu {phys=raw}, range phys 0..252
          signal TPDiagnosisFlashIPBFBD_HR_Byte02: start 16, 8 bit, little-endian, data-type-policy=OVERRIDE, base-type=uint8, compu {phys=raw}, range phys 0..252
          signal TPDiagnosisFlashIPBFBD_HR_Byte03: start 24, 8 bit, little-endian, data-type-policy=OVERRIDE, base-type=uint8, compu {phys=raw}, range phys 0..252
          signal TPDiagnosisFlashIPBFBD_HR_Byte04: start 32, 8 bit, little-endian, data-type-policy=OVERRIDE, base-type=uint8, compu {phys=raw}, range phys 0..252
          signal TPDiagnosisFlashIPBFBD_HR_Byte05: start 40, 8 bit, little-endian, data-type-policy=OVERRIDE, base-type=uint8, compu {phys=raw}, range phys 0..252
          signal TPDiagnosisFlashIPBFBD_HR_Byte06: start 48, 8 bit, little-endian, data-type-policy=OVERRIDE, base-type=uint8, compu {phys=raw}, range phys 0..252
          signal TPDiagnosisFlashIPBFBD_HR_Byte07: start 56, 8 bit, little-endian, data-type-policy=OVERRIDE, base-type=uint8, compu {phys=raw}, range phys 0..252
          signal TPDiagnosisFlashIPBFBD_HR_Byte08: start 64, 8 bit, little-endian, data-type-policy=OVERRIDE, base-type=uint8, compu {phys=raw}, range phys 0..252
          signal TPDiagnosisFlashIPBFBD_HR_Byte09: start 72, 8 bit, little-endian, data-type-policy=OVERRIDE, base-type=uint8, compu {phys=raw}, range phys 0..252
          signal TPDiagnosisFlashIPBFBD_HR_Byte10: start 80, 8 bit, little-endian, data-type-policy=OVERRIDE, base-type=uint8, compu {phys=raw}, range phys 0..252
          signal TPDiagnosisFlashIPBFBD_HR_Byte11: start 88, 8 bit, little-endian, data-type-policy=OVERRIDE, base-type=uint8, compu {phys=raw}, range phys 0..252
          signal TPDiagnosisFlashIPBFBD_HR_Byte12: start 96, 8 bit, little-endian, data-type-policy=OVERRIDE, base-type=uint8, compu {phys=raw}, range phys 0..252
          signal TPDiagnosisFlashIPBFBD_HR_Byte13: start 104, 8 bit, little-endian, data-type-policy=OVERRIDE, base-type=uint8, compu {phys=raw}, range phys 0..252
          signal TPDiagnosisFlashIPBFBD_HR_Byte14: start 112, 8 bit, little-endian, data-type-policy=OVERRIDE, base-type=uint8, compu {phys=raw}, range phys 0..252
          signal TPDiagnosisFlashIPBFBD_HR_Byte15: start 120, 8 bit, little-endian, data-type-policy=OVERRIDE, base-type=uint8, compu {phys=raw}, range phys 0..252
          signal TPDiagnosisFlashIPBFBD_HR_Byte16: start 128, 8 bit, little-endian, data-type-policy=OVERRIDE, base-type=uint8, compu {phys=raw}, range phys 0..252
          signal TPDiagnosisFlashIPBFBD_HR_Byte17: start 136, 8 bit, little-endian, data-type-policy=OVERRIDE, base-type=uint8, compu {phys=raw}, range phys 0..252
          signal TPDiagnosisFlashIPBFBD_HR_Byte18: start 144, 8 bit, little-endian, data-type-policy=OVERRIDE, base-type=uint8, compu {phys=raw}, range phys 0..252
          signal TPDiagnosisFlashIPBFBD_HR_Byte19: start 152, 8 bit, little-endian, data-type-policy=OVERRIDE, base-type=uint8, compu {phys=raw}, range phys 0..252
          signal TPDiagnosisFlashIPBFBD_HR_Byte20: start 160, 8 bit, little-endian, data-type-policy=OVERRIDE, base-type=uint8, compu {phys=raw}, range phys 0..252
          signal TPDiagnosisFlashIPBFBD_HR_Byte21: start 168, 8 bit, little-endian, data-type-policy=OVERRIDE, base-type=uint8, compu {phys=raw}, range phys 0..252
          signal TPDiagnosisFlashIPBFBD_HR_Byte22: start 176, 8 bit, little-endian, data-type-policy=OVERRIDE, base-type=uint8, compu {phys=raw}, range phys 0..252
          signal TPDiagnosisFlashIPBFBD_HR_Byte23: start 184, 8 bit, little-endian, data-type-policy=OVERRIDE, base-type=uint8, compu {phys=raw}, range phys 0..252
          signal TPDiagnosisFlashIPBFBD_HR_Byte24: start 192, 8 bit, little-endian, data-type-policy=OVERRIDE, base-type=uint8, compu {phys=raw}, range phys 0..252
          signal TPDiagnosisFlashIPBFBD_HR_Byte25: start 200, 8 bit, little-endian, data-type-policy=OVERRIDE, base-type=uint8, compu {phys=raw}, range phys 0..252
          signal TPDiagnosisFlashIPBFBD_HR_Byte26: start 208, 8 bit, little-endian, data-type-policy=OVERRIDE, base-type=uint8, compu {phys=raw}, range phys 0..252
          signal TPDiagnosisFlashIPBFBD_HR_Byte27: start 216, 8 bit, little-endian, data-type-policy=OVERRIDE, base-type=uint8, compu {phys=raw}, range phys 0..252
          signal TPDiagnosisFlashIPBFBD_HR_Byte28: start 224, 8 bit, little-endian, data-type-policy=OVERRIDE, base-type=uint8, compu {phys=raw}, range phys 0..252
          signal TPDiagnosisFlashIPBFBD_HR_Byte29: start 232, 8 bit, little-endian, data-type-policy=OVERRIDE, base-type=uint8, compu {phys=raw}, range phys 0..252
          signal TPDiagnosisFlashIPBFBD_HR_Byte30: start 240, 8 bit, little-endian, data-type-policy=OVERRIDE, base-type=uint8, compu {phys=raw}, range phys 0..252
          signal TPDiagnosisFlashIPBFBD_HR_Byte31: start 248, 8 bit, little-endian, data-type-policy=OVERRIDE, base-type=uint8, compu {phys=raw}, range phys 0..252
          signal TPDiagnosisFlashIPBFBD_HR_Byte32: start 256, 8 bit, little-endian, data-type-policy=OVERRIDE, base-type=uint8, compu {phys=raw}, range phys 0..252
          signal TPDiagnosisFlashIPBFBD_HR_Byte33: start 264, 8 bit, little-endian, data-type-policy=OVERRIDE, base-type=uint8, compu {phys=raw}, range phys 0..252
          signal TPDiagnosisFlashIPBFBD_HR_Byte34: start 272, 8 bit, little-endian, data-type-policy=OVERRIDE, base-type=uint8, compu {phys=raw}, range phys 0..252
          signal TPDiagnosisFlashIPBFBD_HR_Byte35: start 280, 8 bit, little-endian, data-type-policy=OVERRIDE, base-type=uint8, compu {phys=raw}, range phys 0..252
          signal TPDiagnosisFlashIPBFBD_HR_Byte36: start 288, 8 bit, little-endian, data-type-policy=OVERRIDE, base-type=uint8, compu {phys=raw}, range phys 0..252
          signal TPDiagnosisFlashIPBFBD_HR_Byte37: start 296, 8 bit, little-endian, data-type-policy=OVERRIDE, base-type=uint8, compu {phys=raw}, range phys 0..252
          signal TPDiagnosisFlashIPBFBD_HR_Byte38: start 304, 8 bit, little-endian, data-type-policy=OVERRIDE, base-type=uint8, compu {phys=raw}, range phys 0..252
          signal TPDiagnosisFlashIPBFBD_HR_Byte39: start 312, 8 bit, little-endian, data-type-policy=OVERRIDE, base-type=uint8, compu {phys=raw}, range phys 0..252
          signal TPDiagnosisFlashIPBFBD_HR_Byte40: start 320, 8 bit, little-endian, data-type-policy=OVERRIDE, base-type=uint8, compu {phys=raw}, range phys 0..252
          signal TPDiagnosisFlashIPBFBD_HR_Byte41: start 328, 8 bit, little-endian, data-type-policy=OVERRIDE, base-type=uint8, compu {phys=raw}, range phys 0..252
          signal TPDiagnosisFlashIPBFBD_HR_Byte42: start 336, 8 bit, little-endian, data-type-policy=OVERRIDE, base-type=uint8, compu {phys=raw}, range phys 0..252
          signal TPDiagnosisFlashIPBFBD_HR_Byte43: start 344, 8 bit, little-endian, data-type-policy=OVERRIDE, base-type=uint8, compu {phys=raw}, range phys 0..252
          signal TPDiagnosisFlashIPBFBD_HR_Byte44: start 352, 8 bit, little-endian, data-type-policy=OVERRIDE, base-type=uint8, compu {phys=raw}, range phys 0..252
          signal TPDiagnosisFlashIPBFBD_HR_Byte45: start 360, 8 bit, little-endian, data-type-policy=OVERRIDE, base-type=uint8, compu {phys=raw}, range phys 0..252
          signal TPDiagnosisFlashIPBFBD_HR_Byte46: start 368, 8 bit, little-endian, data-type-policy=OVERRIDE, base-type=uint8, compu {phys=raw}, range phys 0..252
          signal TPDiagnosisFlashIPBFBD_HR_Byte47: start 376, 8 bit, little-endian, data-type-policy=OVERRIDE, base-type=uint8, compu {phys=raw}, range phys 0..252
          signal TPDiagnosisFlashIPBFBD_HR_Byte48: start 384, 8 bit, little-endian, data-type-policy=OVERRIDE, base-type=uint8, compu {phys=raw}, range phys 0..252
          signal TPDiagnosisFlashIPBFBD_HR_Byte49: start 392, 8 bit, little-endian, data-type-policy=OVERRIDE, base-type=uint8, compu {phys=raw}, range phys 0..252
          signal TPDiagnosisFlashIPBFBD_HR_Byte50: start 400, 8 bit, little-endian, data-type-policy=OVERRIDE, base-type=uint8, compu {phys=raw}, range phys 0..252
          signal TPDiagnosisFlashIPBFBD_HR_Byte51: start 408, 8 bit, little-endian, data-type-policy=OVERRIDE, base-type=uint8, compu {phys=raw}, range phys 0..252
          signal TPDiagnosisFlashIPBFBD_HR_Byte52: start 416, 8 bit, little-endian, data-type-policy=OVERRIDE, base-type=uint8, compu {phys=raw}, range phys 0..252
          signal TPDiagnosisFlashIPBFBD_HR_Byte53: start 424, 8 bit, little-endian, data-type-policy=OVERRIDE, base-type=uint8, compu {phys=raw}, range phys 0..252
          signal TPDiagnosisFlashIPBFBD_HR_Byte54: start 432, 8 bit, little-endian, data-type-policy=OVERRIDE, base-type=uint8, compu {phys=raw}, range phys 0..252
          signal TPDiagnosisFlashIPBFBD_HR_Byte55: start 440, 8 bit, little-endian, data-type-policy=OVERRIDE, base-type=uint8, compu {phys=raw}, range phys 0..252
          signal TPDiagnosisFlashIPBFBD_HR_Byte56: start 448, 8 bit, little-endian, data-type-policy=OVERRIDE, base-type=uint8, compu {phys=raw}, range phys 0..252
          signal TPDiagnosisFlashIPBFBD_HR_Byte57: start 456, 8 bit, little-endian, data-type-policy=OVERRIDE, base-type=uint8, compu {phys=raw}, range phys 0..252
          signal TPDiagnosisFlashIPBFBD_HR_Byte58: start 464, 8 bit, little-endian, data-type-policy=OVERRIDE, base-type=uint8, compu {phys=raw}, range phys 0..252
          signal TPDiagnosisFlashIPBFBD_HR_Byte59: start 472, 8 bit, little-endian, data-type-policy=OVERRIDE, base-type=uint8, compu {phys=raw}, range phys 0..252
          signal TPDiagnosisFlashIPBFBD_HR_Byte60: start 480, 8 bit, little-endian, data-type-policy=OVERRIDE, base-type=uint8, compu {phys=raw}, range phys 0..252
          signal TPDiagnosisFlashIPBFBD_HR_Byte61: start 488, 8 bit, little-endian, data-type-policy=OVERRIDE, base-type=uint8, compu {phys=raw}, range phys 0..252
          signal TPDiagnosisFlashIPBFBD_HR_Byte62: start 496, 8 bit, little-endian, data-type-policy=OVERRIDE, base-type=uint8, compu {phys=raw}, range phys 0..252
          signal TPDiagnosisFlashIPBFBD_HR_Byte63: start 504, 8 bit, little-endian, data-type-policy=OVERRIDE, base-type=uint8, compu {phys=raw}, range phys 0..252
      frame TPDiagnosisFlash_IPB_FBD_Miko: id 0x2BE, frame-length=64, can-addressing-mode=STANDARD, can-frame-rx-behavior=CAN-FD, can-frame-tx-behavior=CAN-FD
        pdu TPDiagnosisFlash_IPB_FBD_Miko: length=64, unused-bit-pattern=0
          signal TPDiagnosisFlashIPBFBD_Miko_Byte00: start 0, 8 bit, little-endian, data-type-policy=OVERRIDE, base-type=uint8, compu {phys=raw}, range phys 0..252
          signal TPDiagnosisFlashIPBFBD_Miko_Byte01: start 8, 8 bit, little-endian, data-type-policy=OVERRIDE, base-type=uint8, compu {phys=raw}, range phys 0..252
          signal TPDiagnosisFlashIPBFBD_Miko_Byte02: start 16, 8 bit, little-endian, data-type-policy=OVERRIDE, base-type=uint8, compu {phys=raw}, range phys 0..252
          signal TPDiagnosisFlashIPBFBD_Miko_Byte03: start 24, 8 bit, little-endian, data-type-policy=OVERRIDE, base-type=uint8, compu {phys=raw}, range phys 0..252
          signal TPDiagnosisFlashIPBFBD_Miko_Byte04: start 32, 8 bit, little-endian, data-type-policy=OVERRIDE, base-type=uint8, compu {phys=raw}, range phys 0..252
          signal TPDiagnosisFlashIPBFBD_Miko_Byte05: start 40, 8 bit, little-endian, data-type-policy=OVERRIDE, base-type=uint8, compu {phys=raw}, range phys 0..252
          signal TPDiagnosisFlashIPBFBD_Miko_Byte06: start 48, 8 bit, little-endian, data-type-policy=OVERRIDE, base-type=uint8, compu {phys=raw}, range phys 0..252
          signal TPDiagnosisFlashIPBFBD_Miko_Byte07: start 56, 8 bit, little-endian, data-type-policy=OVERRIDE, base-type=uint8, compu {phys=raw}, range phys 0..252
          signal TPDiagnosisFlashIPBFBD_Miko_Byte08: start 64, 8 bit, little-endian, data-type-policy=OVERRIDE, base-type=uint8, compu {phys=raw}, range phys 0..252
          signal TPDiagnosisFlashIPBFBD_Miko_Byte09: start 72, 8 bit, little-endian, data-type-policy=OVERRIDE, base-type=uint8, compu {phys=raw}, range phys 0..252
          signal TPDiagnosisFlashIPBFBD_Miko_Byte10: start 80, 8 bit, little-endian, data-type-policy=OVERRIDE, base-type=uint8, compu {phys=raw}, range phys 0..252
          signal TPDiagnosisFlashIPBFBD_Miko_Byte11: start 88, 8 bit, little-endian, data-type-policy=OVERRIDE, base-type=uint8, compu {phys=raw}, range phys 0..252
          signal TPDiagnosisFlashIPBFBD_Miko_Byte12: start 96, 8 bit, little-endian, data-type-policy=OVERRIDE, base-type=uint8, compu {phys=raw}, range phys 0..252
          signal TPDiagnosisFlashIPBFBD_Miko_Byte13: start 104, 8 bit, little-endian, data-type-policy=OVERRIDE, base-type=uint8, compu {phys=raw}, range phys 0..252
          signal TPDiagnosisFlashIPBFBD_Miko_Byte14: start 112, 8 bit, little-endian, data-type-policy=OVERRIDE, base-type=uint8, compu {phys=raw}, range phys 0..252
          signal TPDiagnosisFlashIPBFBD_Miko_Byte15: start 120, 8 bit, little-endian, data-type-policy=OVERRIDE, base-type=uint8, compu {phys=raw}, range phys 0..252
          signal TPDiagnosisFlashIPBFBD_Miko_Byte16: start 128, 8 bit, little-endian, data-type-policy=OVERRIDE, base-type=uint8, compu {phys=raw}, range phys 0..252
          signal TPDiagnosisFlashIPBFBD_Miko_Byte17: start 136, 8 bit, little-endian, data-type-policy=OVERRIDE, base-type=uint8, compu {phys=raw}, range phys 0..252
          signal TPDiagnosisFlashIPBFBD_Miko_Byte18: start 144, 8 bit, little-endian, data-type-policy=OVERRIDE, base-type=uint8, compu {phys=raw}, range phys 0..252
          signal TPDiagnosisFlashIPBFBD_Miko_Byte19: start 152, 8 bit, little-endian, data-type-policy=OVERRIDE, base-type=uint8, compu {phys=raw}, range phys 0..252
          signal TPDiagnosisFlashIPBFBD_Miko_Byte20: start 160, 8 bit, little-endian, data-type-policy=OVERRIDE, base-type=uint8, compu {phys=raw}, range phys 0..252
          signal TPDiagnosisFlashIPBFBD_Miko_Byte21: start 168, 8 bit, little-endian, data-type-policy=OVERRIDE, base-type=uint8, compu {phys=raw}, range phys 0..252
          signal TPDiagnosisFlashIPBFBD_Miko_Byte22: start 176, 8 bit, little-endian, data-type-policy=OVERRIDE, base-type=uint8, compu {phys=raw}, range phys 0..252
          signal TPDiagnosisFlashIPBFBD_Miko_Byte23: start 184, 8 bit, little-endian, data-type-policy=OVERRIDE, base-type=uint8, compu {phys=raw}, range phys 0..252
          signal TPDiagnosisFlashIPBFBD_Miko_Byte24: start 192, 8 bit, little-endian, data-type-policy=OVERRIDE, base-type=uint8, compu {phys=raw}, range phys 0..252
          signal TPDiagnosisFlashIPBFBD_Miko_Byte25: start 200, 8 bit, little-endian, data-type-policy=OVERRIDE, base-type=uint8, compu {phys=raw}, range phys 0..252
          signal TPDiagnosisFlashIPBFBD_Miko_Byte26: start 208, 8 bit, little-endian, data-type-policy=OVERRIDE, base-type=uint8, compu {phys=raw}, range phys 0..252
          signal TPDiagnosisFlashIPBFBD_Miko_Byte27: start 216, 8 bit, little-endian, data-type-policy=OVERRIDE, base-type=uint8, compu {phys=raw}, range phys 0..252
          signal TPDiagnosisFlashIPBFBD_Miko_Byte28: start 224, 8 bit, little-endian, data-type-policy=OVERRIDE, base-type=uint8, compu {phys=raw}, range phys 0..252
          signal TPDiagnosisFlashIPBFBD_Miko_Byte29: start 232, 8 bit, little-endian, data-type-policy=OVERRIDE, base-type=uint8, compu {phys=raw}, range phys 0..252
          signal TPDiagnosisFlashIPBFBD_Miko_Byte30: start 240, 8 bit, little-endian, data-type-policy=OVERRIDE, base-type=uint8, compu {phys=raw}, range phys 0..252
          signal TPDiagnosisFlashIPBFBD_Miko_Byte31: start 248, 8 bit, little-endian, data-type-policy=OVERRIDE, base-type=uint8, compu {phys=raw}, range phys 0..252
          signal TPDiagnosisFlashIPBFBD_Miko_Byte32: start 256, 8 bit, little-endian, data-type-policy=OVERRIDE, base-type=uint8, compu {phys=raw}, range phys 0..252
          signal TPDiagnosisFlashIPBFBD_Miko_Byte33: start 264, 8 bit, little-endian, data-type-policy=OVERRIDE, base-type=uint8, compu {phys=raw}, range phys 0..252
          signal TPDiagnosisFlashIPBFBD_Miko_Byte34: start 272, 8 bit, little-endian, data-type-policy=OVERRIDE, base-type=uint8, compu {phys=raw}, range phys 0..252
          signal TPDiagnosisFlashIPBFBD_Miko_Byte35: start 280, 8 bit, little-endian, data-type-policy=OVERRIDE, base-type=uint8, compu {phys=raw}, range phys 0..252
          signal TPDiagnosisFlashIPBFBD_Miko_Byte36: start 288, 8 bit, little-endian, data-type-policy=OVERRIDE, base-type=uint8, compu {phys=raw}, range phys 0..252
          signal TPDiagnosisFlashIPBFBD_Miko_Byte37: start 296, 8 bit, little-endian, data-type-policy=OVERRIDE, base-type=uint8, compu {phys=raw}, range phys 0..252
          signal TPDiagnosisFlashIPBFBD_Miko_Byte38: start 304, 8 bit, little-endian, data-type-policy=OVERRIDE, base-type=uint8, compu {phys=raw}, range phys 0..252
          signal TPDiagnosisFlashIPBFBD_Miko_Byte39: start 312, 8 bit, little-endian, data-type-policy=OVERRIDE, base-type=uint8, compu {phys=raw}, range phys 0..252
          signal TPDiagnosisFlashIPBFBD_Miko_Byte40: start 320, 8 bit, little-endian, data-type-policy=OVERRIDE, base-type=uint8, compu {phys=raw}, range phys 0..252
          signal TPDiagnosisFlashIPBFBD_Miko_Byte41: start 328, 8 bit, little-endian, data-type-policy=OVERRIDE, base-type=uint8, compu {phys=raw}, range phys 0..252
          signal TPDiagnosisFlashIPBFBD_Miko_Byte42: start 336, 8 bit, little-endian, data-type-policy=OVERRIDE, base-type=uint8, compu {phys=raw}, range phys 0..252
          signal TPDiagnosisFlashIPBFBD_Miko_Byte43: start 344, 8 bit, little-endian, data-type-policy=OVERRIDE, base-type=uint8, compu {phys=raw}, range phys 0..252
          signal TPDiagnosisFlashIPBFBD_Miko_Byte44: start 352, 8 bit, little-endian, data-type-policy=OVERRIDE, base-type=uint8, compu {phys=raw}, range phys 0..252
          signal TPDiagnosisFlashIPBFBD_Miko_Byte45: start 360, 8 bit, little-endian, data-type-policy=OVERRIDE, base-type=uint8, compu {phys=raw}, range phys 0..252
          signal TPDiagnosisFlashIPBFBD_Miko_Byte46: start 368, 8 bit, little-endian, data-type-policy=OVERRIDE, base-type=uint8, compu {phys=raw}, range phys 0..252
          signal TPDiagnosisFlashIPBFBD_Miko_Byte47: start 376, 8 bit, little-endian, data-type-policy=OVERRIDE, base-type=uint8, compu {phys=raw}, range phys 0..252
          signal TPDiagnosisFlashIPBFBD_Miko_Byte48: start 384, 8 bit, little-endian, data-type-policy=OVERRIDE, base-type=uint8, compu {phys=raw}, range phys 0..252
          signal TPDiagnosisFlashIPBFBD_Miko_Byte49: start 392, 8 bit, little-endian, data-type-policy=OVERRIDE, base-type=uint8, compu {phys=raw}, range phys 0..252
          signal TPDiagnosisFlashIPBFBD_Miko_Byte50: start 400, 8 bit, little-endian, data-type-policy=OVERRIDE, base-type=uint8, compu {phys=raw}, range phys 0..252
          signal TPDiagnosisFlashIPBFBD_Miko_Byte51: start 408, 8 bit, little-endian, data-type-policy=OVERRIDE, base-type=uint8, compu {phys=raw}, range phys 0..252
          signal TPDiagnosisFlashIPBFBD_Miko_Byte52: start 416, 8 bit, little-endian, data-type-policy=OVERRIDE, base-type=uint8, compu {phys=raw}, range phys 0..252
          signal TPDiagnosisFlashIPBFBD_Miko_Byte53: start 424, 8 bit, little-endian, data-type-policy=OVERRIDE, base-type=uint8, compu {phys=raw}, range phys 0..252
          signal TPDiagnosisFlashIPBFBD_Miko_Byte54: start 432, 8 bit, little-endian, data-type-policy=OVERRIDE, base-type=uint8, compu {phys=raw}, range phys 0..252
          signal TPDiagnosisFlashIPBFBD_Miko_Byte55: start 440, 8 bit, little-endian, data-type-policy=OVERRIDE, base-type=uint8, compu {phys=raw}, range phys 0..252
          signal TPDiagnosisFlashIPBFBD_Miko_Byte56: start 448, 8 bit, little-endian, data-type-policy=OVERRIDE, base-type=uint8, compu {phys=raw}, range phys 0..252
          signal TPDiagnosisFlashIPBFBD_Miko_Byte57: start 456, 8 bit, little-endian, data-type-policy=OVERRIDE, base-type=uint8, compu {phys=raw}, range phys 0..252
          signal TPDiagnosisFlashIPBFBD_Miko_Byte58: start 464, 8 bit, little-endian, data-type-policy=OVERRIDE, base-type=uint8, compu {phys=raw}, range phys 0..252
          signal TPDiagnosisFlashIPBFBD_Miko_Byte59: start 472, 8 bit, little-endian, data-type-policy=OVERRIDE, base-type=uint8, compu {phys=raw}, range phys 0..252
          signal TPDiagnosisFlashIPBFBD_Miko_Byte60: start 480, 8 bit, little-endian, data-type-policy=OVERRIDE, base-type=uint8, compu {phys=raw}, range phys 0..252
          signal TPDiagnosisFlashIPBFBD_Miko_Byte61: start 488, 8 bit, little-endian, data-type-policy=OVERRIDE, base-type=uint8, compu {phys=raw}, range phys 0..252
          signal TPDiagnosisFlashIPBFBD_Miko_Byte62: start 496, 8 bit, little-endian, data-type-policy=OVERRIDE, base-type=uint8, compu {phys=raw}, range phys 0..252
          signal TPDiagnosisFlashIPBFBD_Miko_Byte63: start 504, 8 bit, little-endian, data-type-policy=OVERRIDE, base-type=uint8, compu {phys=raw}, range phys 0..252
      frame TPDiagnosisFlash_IPB_FBD_MM: id 0x367, frame-length=64, can-addressing-mode=STANDARD, can-frame-rx-behavior=CAN-FD, can-frame-tx-behavior=CAN-FD
        pdu TPDiagnosisFlash_IPB_FBD_MM: length=64, unused-bit-pattern=0
          signal TPDiagnosisFlashIPBFBD_MM_Byte00: start 0, 8 bit, little-endian, data-type-policy=OVERRIDE, base-type=uint8, compu {phys=raw}, range phys 0..252
          signal TPDiagnosisFlashIPBFBD_MM_Byte01: start 8, 8 bit, little-endian, data-type-policy=OVERRIDE, base-type=uint8, compu {phys=raw}, range phys 0..252
          signal TPDiagnosisFlashIPBFBD_MM_Byte02: start 16, 8 bit, little-endian, data-type-policy=OVERRIDE, base-type=uint8, compu {phys=raw}, range phys 0..252
          signal TPDiagnosisFlashIPBFBD_MM_Byte03: start 24, 8 bit, little-endian, data-type-policy=OVERRIDE, base-type=uint8, compu {phys=raw}, range phys 0..252
          signal TPDiagnosisFlashIPBFBD_MM_Byte04: start 32, 8 bit, little-endian, data-type-policy=OVERRIDE, base-type=uint8, compu {phys=raw}, range phys 0..252
          signal TPDiagnosisFlashIPBFBD_MM_Byte05: start 40, 8 bit, little-endian, data-type-policy=OVERRIDE, base-type=uint8, compu {phys=raw}, range phys 0..252
          signal TPDiagnosisFlashIPBFBD_MM_Byte06: start 48, 8 bit, little-endian, data-type-policy=OVERRIDE, base-type=uint8, compu {phys=raw}, range phys 0..252
          signal TPDiagnosisFlashIPBFBD_MM_Byte07: start 56, 8 bit, little-endian, data-type-policy=OVERRIDE, base-type=uint8, compu {phys=raw}, range phys 0..252
          signal TPDiagnosisFlashIPBFBD_MM_Byte08: start 64, 8 bit, little-endian, data-type-policy=OVERRIDE, base-type=uint8, compu {phys=raw}, range phys 0..252
          signal TPDiagnosisFlashIPBFBD_MM_Byte09: start 72, 8 bit, little-endian, data-type-policy=OVERRIDE, base-type=uint8, compu {phys=raw}, range phys 0..252
          signal TPDiagnosisFlashIPBFBD_MM_Byte10: start 80, 8 bit, little-endian, data-type-policy=OVERRIDE, base-type=uint8, compu {phys=raw}, range phys 0..252
          signal TPDiagnosisFlashIPBFBD_MM_Byte11: start 88, 8 bit, little-endian, data-type-policy=OVERRIDE, base-type=uint8, compu {phys=raw}, range phys 0..252
          signal TPDiagnosisFlashIPBFBD_MM_Byte12: start 96, 8 bit, little-endian, data-type-policy=OVERRIDE, base-type=uint8, compu {phys=raw}, range phys 0..252
          signal TPDiagnosisFlashIPBFBD_MM_Byte13: start 104, 8 bit, little-endian, data-type-policy=OVERRIDE, base-type=uint8, compu {phys=raw}, range phys 0..252
          signal TPDiagnosisFlashIPBFBD_MM_Byte14: start 112, 8 bit, little-endian, data-type-policy=OVERRIDE, base-type=uint8, compu {phys=raw}, range phys 0..252
          signal TPDiagnosisFlashIPBFBD_MM_Byte15: start 120, 8 bit, little-endian, data-type-policy=OVERRIDE, base-type=uint8, compu {phys=raw}, range phys 0..252
          signal TPDiagnosisFlashIPBFBD_MM_Byte16: start 128, 8 bit, little-endian, data-type-policy=OVERRIDE, base-type=uint8, compu {phys=raw}, range phys 0..252
          signal TPDiagnosisFlashIPBFBD_MM_Byte17: start 136, 8 bit, little-endian, data-type-policy=OVERRIDE, base-type=uint8, compu {phys=raw}, range phys 0..252
          signal TPDiagnosisFlashIPBFBD_MM_Byte18: start 144, 8 bit, little-endian, data-type-policy=OVERRIDE, base-type=uint8, compu {phys=raw}, range phys 0..252
          signal TPDiagnosisFlashIPBFBD_MM_Byte19: start 152, 8 bit, little-endian, data-type-policy=OVERRIDE, base-type=uint8, compu {phys=raw}, range phys 0..252
          signal TPDiagnosisFlashIPBFBD_MM_Byte20: start 160, 8 bit, little-endian, data-type-policy=OVERRIDE, base-type=uint8, compu {phys=raw}, range phys 0..252
          signal TPDiagnosisFlashIPBFBD_MM_Byte21: start 168, 8 bit, little-endian, data-type-policy=OVERRIDE, base-type=uint8, compu {phys=raw}, range phys 0..252
          signal TPDiagnosisFlashIPBFBD_MM_Byte22: start 176, 8 bit, little-endian, data-type-policy=OVERRIDE, base-type=uint8, compu {phys=raw}, range phys 0..252
          signal TPDiagnosisFlashIPBFBD_MM_Byte23: start 184, 8 bit, little-endian, data-type-policy=OVERRIDE, base-type=uint8, compu {phys=raw}, range phys 0..252
          signal TPDiagnosisFlashIPBFBD_MM_Byte24: start 192, 8 bit, little-endian, data-type-policy=OVERRIDE, base-type=uint8, compu {phys=raw}, range phys 0..252
          signal TPDiagnosisFlashIPBFBD_MM_Byte25: start 200, 8 bit, little-endian, data-type-policy=OVERRIDE, base-type=uint8, compu {phys=raw}, range phys 0..252
          signal TPDiagnosisFlashIPBFBD_MM_Byte26: start 208, 8 bit, little-endian, data-type-policy=OVERRIDE, base-type=uint8, compu {phys=raw}, range phys 0..252
          signal TPDiagnosisFlashIPBFBD_MM_Byte27: start 216, 8 bit, little-endian, data-type-policy=OVERRIDE, base-type=uint8, compu {phys=raw}, range phys 0..252
          signal TPDiagnosisFlashIPBFBD_MM_Byte28: start 224, 8 bit, little-endian, data-type-policy=OVERRIDE, base-type=uint8, compu {phys=raw}, range phys 0..252
          signal TPDiagnosisFlashIPBFBD_MM_Byte29: start 232, 8 bit, little-endian, data-type-policy=OVERRIDE, base-type=uint8, compu {phys=raw}, range phys 0..252
          signal TPDiagnosisFlashIPBFBD_MM_Byte30: start 240, 8 bit, little-endian, data-type-policy=OVERRIDE, base-type=uint8, compu {phys=raw}, range phys 0..252
          signal TPDiagnosisFlashIPBFBD_MM_Byte31: start 248, 8 bit, little-endian, data-type-policy=OVERRIDE, base-type=uint8, compu {phys=raw}, range phys 0..252
          signal TPDiagnosisFlashIPBFBD_MM_Byte32: start 256, 8 bit, little-endian, data-type-policy=OVERRIDE, base-type=uint8, compu {phys=raw}, range phys 0..252
          signal TPDiagnosisFlashIPBFBD_MM_Byte33: start 264, 8 bit, little-endian, data-type-policy=OVERRIDE, base-type=uint8, compu {phys=raw}, range phys 0..252
          signal TPDiagnosisFlashIPBFBD_MM_Byte34: start 272, 8 bit, little-endian, data-type-policy=OVERRIDE, base-type=uint8, compu {phys=raw}, range phys 0..252
          signal TPDiagnosisFlashIPBFBD_MM_Byte35: start 280, 8 bit, little-endian, data-type-policy=OVERRIDE, base-type=uint8, compu {phys=raw}, range phys 0..252
          signal TPDiagnosisFlashIPBFBD_MM_Byte36: start 288, 8 bit, little-endian, data-type-policy=OVERRIDE, base-type=uint8, compu {phys=raw}, range phys 0..252
          signal TPDiagnosisFlashIPBFBD_MM_Byte37: start 296, 8 bit, little-endian, data-type-policy=OVERRIDE, base-type=uint8, compu {phys=raw}, range phys 0..252
          signal TPDiagnosisFlashIPBFBD_MM_Byte38: start 304, 8 bit, little-endian, data-type-policy=OVERRIDE, base-type=uint8, compu {phys=raw}, range phys 0..252
          signal TPDiagnosisFlashIPBFBD_MM_Byte39: start 312, 8 bit, little-endian, data-type-policy=OVERRIDE, base-type=uint8, compu {phys=raw}, range phys 0..252
          signal TPDiagnosisFlashIPBFBD_MM_Byte40: start 320, 8 bit, little-endian, data-type-policy=OVERRIDE, base-type=uint8, compu {phys=raw}, range phys 0..252
          signal TPDiagnosisFlashIPBFBD_MM_Byte41: start 328, 8 bit, little-endian, data-type-policy=OVERRIDE, base-type=uint8, compu {phys=raw}, range phys 0..252
          signal TPDiagnosisFlashIPBFBD_MM_Byte42: start 336, 8 bit, little-endian, data-type-policy=OVERRIDE, base-type=uint8, compu {phys=raw}, range phys 0..252
          signal TPDiagnosisFlashIPBFBD_MM_Byte43: start 344, 8 bit, little-endian, data-type-policy=OVERRIDE, base-type=uint8, compu {phys=raw}, range phys 0..252
          signal TPDiagnosisFlashIPBFBD_MM_Byte44: start 352, 8 bit, little-endian, data-type-policy=OVERRIDE, base-type=uint8, compu {phys=raw}, range phys 0..252
          signal TPDiagnosisFlashIPBFBD_MM_Byte45: start 360, 8 bit, little-endian, data-type-policy=OVERRIDE, base-type=uint8, compu {phys=raw}, range phys 0..252
          signal TPDiagnosisFlashIPBFBD_MM_Byte46: start 368, 8 bit, little-endian, data-type-policy=OVERRIDE, base-type=uint8, compu {phys=raw}, range phys 0..252
          signal TPDiagnosisFlashIPBFBD_MM_Byte47: start 376, 8 bit, little-endian, data-type-policy=OVERRIDE, base-type=uint8, compu {phys=raw}, range phys 0..252
          signal TPDiagnosisFlashIPBFBD_MM_Byte48: start 384, 8 bit, little-endian, data-type-policy=OVERRIDE, base-type=uint8, compu {phys=raw}, range phys 0..252
          signal TPDiagnosisFlashIPBFBD_MM_Byte49: start 392, 8 bit, little-endian, data-type-policy=OVERRIDE, base-type=uint8, compu {phys=raw}, range phys 0..252
          signal TPDiagnosisFlashIPBFBD_MM_Byte50: start 400, 8 bit, little-endian, data-type-policy=OVERRIDE, base-type=uint8, compu {phys=raw}, range phys 0..252
          signal TPDiagnosisFlashIPBFBD_MM_Byte51: start 408, 8 bit, little-endian, data-type-policy=OVERRIDE, base-type=uint8, compu {phys=raw}, range phys 0..252
          signal TPDiagnosisFlashIPBFBD_MM_Byte52: start 416, 8 bit, little-endian, data-type-policy=OVERRIDE, base-type=uint8, compu {phys=raw}, range phys 0..252
          signal TPDiagnosisFlashIPBFBD_MM_Byte53: start 424, 8 bit, little-endian, data-type-policy=OVERRIDE, base-type=uint8, compu {phys=raw}, range phys 0..252
          signal TPDiagnosisFlashIPBFBD_MM_Byte54: start 432, 8 bit, little-endian, data-type-policy=OVERRIDE, base-type=uint8, compu {phys=raw}, range phys 0..252
          signal TPDiagnosisFlashIPBFBD_MM_Byte55: start 440, 8 bit, little-endian, data-type-policy=OVERRIDE, base-type=uint8, compu {phys=raw}, range phys 0..252
          signal TPDiagnosisFlashIPBFBD_MM_Byte56: start 448, 8 bit, little-endian, data-type-policy=OVERRIDE, base-type=uint8, compu {phys=raw}, range phys 0..252
          signal TPDiagnosisFlashIPBFBD_MM_Byte57: start 456, 8 bit, little-endian, data-type-policy=OVERRIDE, base-type=uint8, compu {phys=raw}, range phys 0..252
          signal TPDiagnosisFlashIPBFBD_MM_Byte58: start 464, 8 bit, little-endian, data-type-policy=OVERRIDE, base-type=uint8, compu {phys=raw}, range phys 0..252
          signal TPDiagnosisFlashIPBFBD_MM_Byte59: start 472, 8 bit, little-endian, data-type-policy=OVERRIDE, base-type=uint8, compu {phys=raw}, range phys 0..252
          signal TPDiagnosisFlashIPBFBD_MM_Byte60: start 480, 8 bit, little-endian, data-type-policy=OVERRIDE, base-type=uint8, compu {phys=raw}, range phys 0..252
          signal TPDiagnosisFlashIPBFBD_MM_Byte61: start 488, 8 bit, little-endian, data-type-policy=OVERRIDE, base-type=uint8, compu {phys=raw}, range phys 0..252
          signal TPDiagnosisFlashIPBFBD_MM_Byte62: start 496, 8 bit, little-endian, data-type-policy=OVERRIDE, base-type=uint8, compu {phys=raw}, range phys 0..252
          signal TPDiagnosisFlashIPBFBD_MM_Byte63: start 504, 8 bit, little-endian, data-type-policy=OVERRIDE, base-type=uint8, compu {phys=raw}, range phys 0..252
      frame TPDiagnosisFlash_IPB_FBD_Trunk: id 0x2BF, frame-length=64, can-addressing-mode=STANDARD, can-frame-rx-behavior=CAN-FD, can-frame-tx-behavior=CAN-FD
        pdu TPDiagnosisFlash_IPB_FBD_Trunk: length=64, unused-bit-pattern=0
          signal TPDiagnosisFlashIPBFBD_Trunk_Byte00: start 0, 8 bit, little-endian, data-type-policy=OVERRIDE, base-type=uint8, compu {phys=raw}, range phys 0..252
          signal TPDiagnosisFlashIPBFBD_Trunk_Byte01: start 8, 8 bit, little-endian, data-type-policy=OVERRIDE, base-type=uint8, compu {phys=raw}, range phys 0..252
          signal TPDiagnosisFlashIPBFBD_Trunk_Byte02: start 16, 8 bit, little-endian, data-type-policy=OVERRIDE, base-type=uint8, compu {phys=raw}, range phys 0..252
          signal TPDiagnosisFlashIPBFBD_Trunk_Byte03: start 24, 8 bit, little-endian, data-type-policy=OVERRIDE, base-type=uint8, compu {phys=raw}, range phys 0..252
          signal TPDiagnosisFlashIPBFBD_Trunk_Byte04: start 32, 8 bit, little-endian, data-type-policy=OVERRIDE, base-type=uint8, compu {phys=raw}, range phys 0..252
          signal TPDiagnosisFlashIPBFBD_Trunk_Byte05: start 40, 8 bit, little-endian, data-type-policy=OVERRIDE, base-type=uint8, compu {phys=raw}, range phys 0..252
          signal TPDiagnosisFlashIPBFBD_Trunk_Byte06: start 48, 8 bit, little-endian, data-type-policy=OVERRIDE, base-type=uint8, compu {phys=raw}, range phys 0..252
          signal TPDiagnosisFlashIPBFBD_Trunk_Byte07: start 56, 8 bit, little-endian, data-type-policy=OVERRIDE, base-type=uint8, compu {phys=raw}, range phys 0..252
          signal TPDiagnosisFlashIPBFBD_Trunk_Byte08: start 64, 8 bit, little-endian, data-type-policy=OVERRIDE, base-type=uint8, compu {phys=raw}, range phys 0..252
          signal TPDiagnosisFlashIPBFBD_Trunk_Byte09: start 72, 8 bit, little-endian, data-type-policy=OVERRIDE, base-type=uint8, compu {phys=raw}, range phys 0..252
          signal TPDiagnosisFlashIPBFBD_Trunk_Byte10: start 80, 8 bit, little-endian, data-type-policy=OVERRIDE, base-type=uint8, compu {phys=raw}, range phys 0..252
          signal TPDiagnosisFlashIPBFBD_Trunk_Byte11: start 88, 8 bit, little-endian, data-type-policy=OVERRIDE, base-type=uint8, compu {phys=raw}, range phys 0..252
          signal TPDiagnosisFlashIPBFBD_Trunk_Byte12: start 96, 8 bit, little-endian, data-type-policy=OVERRIDE, base-type=uint8, compu {phys=raw}, range phys 0..252
          signal TPDiagnosisFlashIPBFBD_Trunk_Byte13: start 104, 8 bit, little-endian, data-type-policy=OVERRIDE, base-type=uint8, compu {phys=raw}, range phys 0..252
          signal TPDiagnosisFlashIPBFBD_Trunk_Byte14: start 112, 8 bit, little-endian, data-type-policy=OVERRIDE, base-type=uint8, compu {phys=raw}, range phys 0..252
          signal TPDiagnosisFlashIPBFBD_Trunk_Byte15: start 120, 8 bit, little-endian, data-type-policy=OVERRIDE, base-type=uint8, compu {phys=raw}, range phys 0..252
          signal TPDiagnosisFlashIPBFBD_Trunk_Byte16: start 128, 8 bit, little-endian, data-type-policy=OVERRIDE, base-type=uint8, compu {phys=raw}, range phys 0..252
          signal TPDiagnosisFlashIPBFBD_Trunk_Byte17: start 136, 8 bit, little-endian, data-type-policy=OVERRIDE, base-type=uint8, compu {phys=raw}, range phys 0..252
          signal TPDiagnosisFlashIPBFBD_Trunk_Byte18: start 144, 8 bit, little-endian, data-type-policy=OVERRIDE, base-type=uint8, compu {phys=raw}, range phys 0..252
          signal TPDiagnosisFlashIPBFBD_Trunk_Byte19: start 152, 8 bit, little-endian, data-type-policy=OVERRIDE, base-type=uint8, compu {phys=raw}, range phys 0..252
          signal TPDiagnosisFlashIPBFBD_Trunk_Byte20: start 160, 8 bit, little-endian, data-type-policy=OVERRIDE, base-type=uint8, compu {phys=raw}, range phys 0..252
          signal TPDiagnosisFlashIPBFBD_Trunk_Byte21: start 168, 8 bit, little-endian, data-type-policy=OVERRIDE, base-type=uint8, compu {phys=raw}, range phys 0..252
          signal TPDiagnosisFlashIPBFBD_Trunk_Byte22: start 176, 8 bit, little-endian, data-type-policy=OVERRIDE, base-type=uint8, compu {phys=raw}, range phys 0..252
          signal TPDiagnosisFlashIPBFBD_Trunk_Byte23: start 184, 8 bit, little-endian, data-type-policy=OVERRIDE, base-type=uint8, compu {phys=raw}, range phys 0..252
          signal TPDiagnosisFlashIPBFBD_Trunk_Byte24: start 192, 8 bit, little-endian, data-type-policy=OVERRIDE, base-type=uint8, compu {phys=raw}, range phys 0..252
          signal TPDiagnosisFlashIPBFBD_Trunk_Byte25: start 200, 8 bit, little-endian, data-type-policy=OVERRIDE, base-type=uint8, compu {phys=raw}, range phys 0..252
          signal TPDiagnosisFlashIPBFBD_Trunk_Byte26: start 208, 8 bit, little-endian, data-type-policy=OVERRIDE, base-type=uint8, compu {phys=raw}, range phys 0..252
          signal TPDiagnosisFlashIPBFBD_Trunk_Byte27: start 216, 8 bit, little-endian, data-type-policy=OVERRIDE, base-type=uint8, compu {phys=raw}, range phys 0..252
          signal TPDiagnosisFlashIPBFBD_Trunk_Byte28: start 224, 8 bit, little-endian, data-type-policy=OVERRIDE, base-type=uint8, compu {phys=raw}, range phys 0..252
          signal TPDiagnosisFlashIPBFBD_Trunk_Byte29: start 232, 8 bit, little-endian, data-type-policy=OVERRIDE, base-type=uint8, compu {phys=raw}, range phys 0..252
          signal TPDiagnosisFlashIPBFBD_Trunk_Byte30: start 240, 8 bit, little-endian, data-type-policy=OVERRIDE, base-type=uint8, compu {phys=raw}, range phys 0..252
          signal TPDiagnosisFlashIPBFBD_Trunk_Byte31: start 248, 8 bit, little-endian, data-type-policy=OVERRIDE, base-type=uint8, compu {phys=raw}, range phys 0..252
          signal TPDiagnosisFlashIPBFBD_Trunk_Byte32: start 256, 8 bit, little-endian, data-type-policy=OVERRIDE, base-type=uint8, compu {phys=raw}, range phys 0..252
          signal TPDiagnosisFlashIPBFBD_Trunk_Byte33: start 264, 8 bit, little-endian, data-type-policy=OVERRIDE, base-type=uint8, compu {phys=raw}, range phys 0..252
          signal TPDiagnosisFlashIPBFBD_Trunk_Byte34: start 272, 8 bit, little-endian, data-type-policy=OVERRIDE, base-type=uint8, compu {phys=raw}, range phys 0..252
          signal TPDiagnosisFlashIPBFBD_Trunk_Byte35: start 280, 8 bit, little-endian, data-type-policy=OVERRIDE, base-type=uint8, compu {phys=raw}, range phys 0..252
          signal TPDiagnosisFlashIPBFBD_Trunk_Byte36: start 288, 8 bit, little-endian, data-type-policy=OVERRIDE, base-type=uint8, compu {phys=raw}, range phys 0..252
          signal TPDiagnosisFlashIPBFBD_Trunk_Byte37: start 296, 8 bit, little-endian, data-type-policy=OVERRIDE, base-type=uint8, compu {phys=raw}, range phys 0..252
          signal TPDiagnosisFlashIPBFBD_Trunk_Byte38: start 304, 8 bit, little-endian, data-type-policy=OVERRIDE, base-type=uint8, compu {phys=raw}, range phys 0..252
          signal TPDiagnosisFlashIPBFBD_Trunk_Byte39: start 312, 8 bit, little-endian, data-type-policy=OVERRIDE, base-type=uint8, compu {phys=raw}, range phys 0..252
          signal TPDiagnosisFlashIPBFBD_Trunk_Byte40: start 320, 8 bit, little-endian, data-type-policy=OVERRIDE, base-type=uint8, compu {phys=raw}, range phys 0..252
          signal TPDiagnosisFlashIPBFBD_Trunk_Byte41: start 328, 8 bit, little-endian, data-type-policy=OVERRIDE, base-type=uint8, compu {phys=raw}, range phys 0..252
          signal TPDiagnosisFlashIPBFBD_Trunk_Byte42: start 336, 8 bit, little-endian, data-type-policy=OVERRIDE, base-type=uint8, compu {phys=raw}, range phys 0..252
          signal TPDiagnosisFlashIPBFBD_Trunk_Byte43: start 344, 8 bit, little-endian, data-type-policy=OVERRIDE, base-type=uint8, compu {phys=raw}, range phys 0..252
          signal TPDiagnosisFlashIPBFBD_Trunk_Byte44: start 352, 8 bit, little-endian, data-type-policy=OVERRIDE, base-type=uint8, compu {phys=raw}, range phys 0..252
          signal TPDiagnosisFlashIPBFBD_Trunk_Byte45: start 360, 8 bit, little-endian, data-type-policy=OVERRIDE, base-type=uint8, compu {phys=raw}, range phys 0..252
          signal TPDiagnosisFlashIPBFBD_Trunk_Byte46: start 368, 8 bit, little-endian, data-type-policy=OVERRIDE, base-type=uint8, compu {phys=raw}, range phys 0..252
          signal TPDiagnosisFlashIPBFBD_Trunk_Byte47: start 376, 8 bit, little-endian, data-type-policy=OVERRIDE, base-type=uint8, compu {phys=raw}, range phys 0..252
          signal TPDiagnosisFlashIPBFBD_Trunk_Byte48: start 384, 8 bit, little-endian, data-type-policy=OVERRIDE, base-type=uint8, compu {phys=raw}, range phys 0..252
          signal TPDiagnosisFlashIPBFBD_Trunk_Byte49: start 392, 8 bit, little-endian, data-type-policy=OVERRIDE, base-type=uint8, compu {phys=raw}, range phys 0..252
          signal TPDiagnosisFlashIPBFBD_Trunk_Byte50: start 400, 8 bit, little-endian, data-type-policy=OVERRIDE, base-type=uint8, compu {phys=raw}, range phys 0..252
          signal TPDiagnosisFlashIPBFBD_Trunk_Byte51: start 408, 8 bit, little-endian, data-type-policy=OVERRIDE, base-type=uint8, compu {phys=raw}, range phys 0..252
          signal TPDiagnosisFlashIPBFBD_Trunk_Byte52: start 416, 8 bit, little-endian, data-type-policy=OVERRIDE, base-type=uint8, compu {phys=raw}, range phys 0..252
          signal TPDiagnosisFlashIPBFBD_Trunk_Byte53: start 424, 8 bit, little-endian, data-type-policy=OVERRIDE, base-type=uint8, compu {phys=raw}, range phys 0..252
          signal TPDiagnosisFlashIPBFBD_Trunk_Byte54: start 432, 8 bit, little-endian, data-type-policy=OVERRIDE, base-type=uint8, compu {phys=raw}, range phys 0..252
          signal TPDiagnosisFlashIPBFBD_Trunk_Byte55: start 440, 8 bit, little-endian, data-type-policy=OVERRIDE, base-type=uint8, compu {phys=raw}, range phys 0..252
          signal TPDiagnosisFlashIPBFBD_Trunk_Byte56: start 448, 8 bit, little-endian, data-type-policy=OVERRIDE, base-type=uint8, compu {phys=raw}, range phys 0..252
          signal TPDiagnosisFlashIPBFBD_Trunk_Byte57: start 456, 8 bit, little-endian, data-type-policy=OVERRIDE, base-type=uint8, compu {phys=raw}, range phys 0..252
          signal TPDiagnosisFlashIPBFBD_Trunk_Byte58: start 464, 8 bit, little-endian, data-type-policy=OVERRIDE, base-type=uint8, compu {phys=raw}, range phys 0..252
          signal TPDiagnosisFlashIPBFBD_Trunk_Byte59: start 472, 8 bit, little-endian, data-type-policy=OVERRIDE, base-type=uint8, compu {phys=raw}, range phys 0..252
          signal TPDiagnosisFlashIPBFBD_Trunk_Byte60: start 480, 8 bit, little-endian, data-type-policy=OVERRIDE, base-type=uint8, compu {phys=raw}, range phys 0..252
          signal TPDiagnosisFlashIPBFBD_Trunk_Byte61: start 488, 8 bit, little-endian, data-type-policy=OVERRIDE, base-type=uint8, compu {phys=raw}, range phys 0..252
          signal TPDiagnosisFlashIPBFBD_Trunk_Byte62: start 496, 8 bit, little-endian, data-type-policy=OVERRIDE, base-type=uint8, compu {phys=raw}, range phys 0..252
          signal TPDiagnosisFlashIPBFBD_Trunk_Byte63: start 504, 8 bit, little-endian, data-type-policy=OVERRIDE, base-type=uint8, compu {phys=raw}, range phys 0..252
      frame TPDiagnosisFlash_IPB_FBD_VL: id 0x2C0, frame-length=64, can-addressing-mode=STANDARD, can-frame-rx-behavior=CAN-FD, can-frame-tx-behavior=CAN-FD
        pdu TPDiagnosisFlash_IPB_FBD_VL: length=64, unused-bit-pattern=0
          signal TPDiagnosisFlashIPBFBD_VL_Byte00: start 0, 8 bit, little-endian, data-type-policy=OVERRIDE, base-type=uint8, compu {phys=raw}, range phys 0..252
          signal TPDiagnosisFlashIPBFBD_VL_Byte01: start 8, 8 bit, little-endian, data-type-policy=OVERRIDE, base-type=uint8, compu {phys=raw}, range phys 0..252
          signal TPDiagnosisFlashIPBFBD_VL_Byte02: start 16, 8 bit, little-endian, data-type-policy=OVERRIDE, base-type=uint8, compu {phys=raw}, range phys 0..252
          signal TPDiagnosisFlashIPBFBD_VL_Byte03: start 24, 8 bit, little-endian, data-type-policy=OVERRIDE, base-type=uint8, compu {phys=raw}, range phys 0..252
          signal TPDiagnosisFlashIPBFBD_VL_Byte04: start 32, 8 bit, little-endian, data-type-policy=OVERRIDE, base-type=uint8, compu {phys=raw}, range phys 0..252
          signal TPDiagnosisFlashIPBFBD_VL_Byte05: start 40, 8 bit, little-endian, data-type-policy=OVERRIDE, base-type=uint8, compu {phys=raw}, range phys 0..252
          signal TPDiagnosisFlashIPBFBD_VL_Byte06: start 48, 8 bit, little-endian, data-type-policy=OVERRIDE, base-type=uint8, compu {phys=raw}, range phys 0..252
          signal TPDiagnosisFlashIPBFBD_VL_Byte07: start 56, 8 bit, little-endian, data-type-policy=OVERRIDE, base-type=uint8, compu {phys=raw}, range phys 0..252
          signal TPDiagnosisFlashIPBFBD_VL_Byte08: start 64, 8 bit, little-endian, data-type-policy=OVERRIDE, base-type=uint8, compu {phys=raw}, range phys 0..252
          signal TPDiagnosisFlashIPBFBD_VL_Byte09: start 72, 8 bit, little-endian, data-type-policy=OVERRIDE, base-type=uint8, compu {phys=raw}, range phys 0..252
          signal TPDiagnosisFlashIPBFBD_VL_Byte10: start 80, 8 bit, little-endian, data-type-policy=OVERRIDE, base-type=uint8, compu {phys=raw}, range phys 0..252
          signal TPDiagnosisFlashIPBFBD_VL_Byte11: start 88, 8 bit, little-endian, data-type-policy=OVERRIDE, base-type=uint8, compu {phys=raw}, range phys 0..252
          signal TPDiagnosisFlashIPBFBD_VL_Byte12: start 96, 8 bit, little-endian, data-type-policy=OVERRIDE, base-type=uint8, compu {phys=raw}, range phys 0..252
          signal TPDiagnosisFlashIPBFBD_VL_Byte13: start 104, 8 bit, little-endian, data-type-policy=OVERRIDE, base-type=uint8, compu {phys=raw}, range phys 0..252
          signal TPDiagnosisFlashIPBFBD_VL_Byte14: start 112, 8 bit, little-endian, data-type-policy=OVERRIDE, base-type=uint8, compu {phys=raw}, range phys 0..252
          signal TPDiagnosisFlashIPBFBD_VL_Byte15: start 120, 8 bit, little-endian, data-type-policy=OVERRIDE, base-type=uint8, compu {phys=raw}, range phys 0..252
          signal TPDiagnosisFlashIPBFBD_VL_Byte16: start 128, 8 bit, little-endian, data-type-policy=OVERRIDE, base-type=uint8, compu {phys=raw}, range phys 0..252
          signal TPDiagnosisFlashIPBFBD_VL_Byte17: start 136, 8 bit, little-endian, data-type-policy=OVERRIDE, base-type=uint8, compu {phys=raw}, range phys 0..252
          signal TPDiagnosisFlashIPBFBD_VL_Byte18: start 144, 8 bit, little-endian, data-type-policy=OVERRIDE, base-type=uint8, compu {phys=raw}, range phys 0..252
          signal TPDiagnosisFlashIPBFBD_VL_Byte19: start 152, 8 bit, little-endian, data-type-policy=OVERRIDE, base-type=uint8, compu {phys=raw}, range phys 0..252
          signal TPDiagnosisFlashIPBFBD_VL_Byte20: start 160, 8 bit, little-endian, data-type-policy=OVERRIDE, base-type=uint8, compu {phys=raw}, range phys 0..252
          signal TPDiagnosisFlashIPBFBD_VL_Byte21: start 168, 8 bit, little-endian, data-type-policy=OVERRIDE, base-type=uint8, compu {phys=raw}, range phys 0..252
          signal TPDiagnosisFlashIPBFBD_VL_Byte22: start 176, 8 bit, little-endian, data-type-policy=OVERRIDE, base-type=uint8, compu {phys=raw}, range phys 0..252
          signal TPDiagnosisFlashIPBFBD_VL_Byte23: start 184, 8 bit, little-endian, data-type-policy=OVERRIDE, base-type=uint8, compu {phys=raw}, range phys 0..252
          signal TPDiagnosisFlashIPBFBD_VL_Byte24: start 192, 8 bit, little-endian, data-type-policy=OVERRIDE, base-type=uint8, compu {phys=raw}, range phys 0..252
          signal TPDiagnosisFlashIPBFBD_VL_Byte25: start 200, 8 bit, little-endian, data-type-policy=OVERRIDE, base-type=uint8, compu {phys=raw}, range phys 0..252
          signal TPDiagnosisFlashIPBFBD_VL_Byte26: start 208, 8 bit, little-endian, data-type-policy=OVERRIDE, base-type=uint8, compu {phys=raw}, range phys 0..252
          signal TPDiagnosisFlashIPBFBD_VL_Byte27: start 216, 8 bit, little-endian, data-type-policy=OVERRIDE, base-type=uint8, compu {phys=raw}, range phys 0..252
          signal TPDiagnosisFlashIPBFBD_VL_Byte28: start 224, 8 bit, little-endian, data-type-policy=OVERRIDE, base-type=uint8, compu {phys=raw}, range phys 0..252
          signal TPDiagnosisFlashIPBFBD_VL_Byte29: start 232, 8 bit, little-endian, data-type-policy=OVERRIDE, base-type=uint8, compu {phys=raw}, range phys 0..252
          signal TPDiagnosisFlashIPBFBD_VL_Byte30: start 240, 8 bit, little-endian, data-type-policy=OVERRIDE, base-type=uint8, compu {phys=raw}, range phys 0..252
          signal TPDiagnosisFlashIPBFBD_VL_Byte31: start 248, 8 bit, little-endian, data-type-policy=OVERRIDE, base-type=uint8, compu {phys=raw}, range phys 0..252
          signal TPDiagnosisFlashIPBFBD_VL_Byte32: start 256, 8 bit, little-endian, data-type-policy=OVERRIDE, base-type=uint8, compu {phys=raw}, range phys 0..252
          signal TPDiagnosisFlashIPBFBD_VL_Byte33: start 264, 8 bit, little-endian, data-type-policy=OVERRIDE, base-type=uint8, compu {phys=raw}, range phys 0..252
          signal TPDiagnosisFlashIPBFBD_VL_Byte34: start 272, 8 bit, little-endian, data-type-policy=OVERRIDE, base-type=uint8, compu {phys=raw}, range phys 0..252
          signal TPDiagnosisFlashIPBFBD_VL_Byte35: start 280, 8 bit, little-endian, data-type-policy=OVERRIDE, base-type=uint8, compu {phys=raw}, range phys 0..252
          signal TPDiagnosisFlashIPBFBD_VL_Byte36: start 288, 8 bit, little-endian, data-type-policy=OVERRIDE, base-type=uint8, compu {phys=raw}, range phys 0..252
          signal TPDiagnosisFlashIPBFBD_VL_Byte37: start 296, 8 bit, little-endian, data-type-policy=OVERRIDE, base-type=uint8, compu {phys=raw}, range phys 0..252
          signal TPDiagnosisFlashIPBFBD_VL_Byte38: start 304, 8 bit, little-endian, data-type-policy=OVERRIDE, base-type=uint8, compu {phys=raw}, range phys 0..252
          signal TPDiagnosisFlashIPBFBD_VL_Byte39: start 312, 8 bit, little-endian, data-type-policy=OVERRIDE, base-type=uint8, compu {phys=raw}, range phys 0..252
          signal TPDiagnosisFlashIPBFBD_VL_Byte40: start 320, 8 bit, little-endian, data-type-policy=OVERRIDE, base-type=uint8, compu {phys=raw}, range phys 0..252
          signal TPDiagnosisFlashIPBFBD_VL_Byte41: start 328, 8 bit, little-endian, data-type-policy=OVERRIDE, base-type=uint8, compu {phys=raw}, range phys 0..252
          signal TPDiagnosisFlashIPBFBD_VL_Byte42: start 336, 8 bit, little-endian, data-type-policy=OVERRIDE, base-type=uint8, compu {phys=raw}, range phys 0..252
          signal TPDiagnosisFlashIPBFBD_VL_Byte43: start 344, 8 bit, little-endian, data-type-policy=OVERRIDE, base-type=uint8, compu {phys=raw}, range phys 0..252
          signal TPDiagnosisFlashIPBFBD_VL_Byte44: start 352, 8 bit, little-endian, data-type-policy=OVERRIDE, base-type=uint8, compu {phys=raw}, range phys 0..252
          signal TPDiagnosisFlashIPBFBD_VL_Byte45: start 360, 8 bit, little-endian, data-type-policy=OVERRIDE, base-type=uint8, compu {phys=raw}, range phys 0..252
          signal TPDiagnosisFlashIPBFBD_VL_Byte46: start 368, 8 bit, little-endian, data-type-policy=OVERRIDE, base-type=uint8, compu {phys=raw}, range phys 0..252
          signal TPDiagnosisFlashIPBFBD_VL_Byte47: start 376, 8 bit, little-endian, data-type-policy=OVERRIDE, base-type=uint8, compu {phys=raw}, range phys 0..252
          signal TPDiagnosisFlashIPBFBD_VL_Byte48: start 384, 8 bit, little-endian, data-type-policy=OVERRIDE, base-type=uint8, compu {phys=raw}, range phys 0..252
          signal TPDiagnosisFlashIPBFBD_VL_Byte49: start 392, 8 bit, little-endian, data-type-policy=OVERRIDE, base-type=uint8, compu {phys=raw}, range phys 0..252
          signal TPDiagnosisFlashIPBFBD_VL_Byte50: start 400, 8 bit, little-endian, data-type-policy=OVERRIDE, base-type=uint8, compu {phys=raw}, range phys 0..252
          signal TPDiagnosisFlashIPBFBD_VL_Byte51: start 408, 8 bit, little-endian, data-type-policy=OVERRIDE, base-type=uint8, compu {phys=raw}, range phys 0..252
          signal TPDiagnosisFlashIPBFBD_VL_Byte52: start 416, 8 bit, little-endian, data-type-policy=OVERRIDE, base-type=uint8, compu {phys=raw}, range phys 0..252
          signal TPDiagnosisFlashIPBFBD_VL_Byte53: start 424, 8 bit, little-endian, data-type-policy=OVERRIDE, base-type=uint8, compu {phys=raw}, range phys 0..252
          signal TPDiagnosisFlashIPBFBD_VL_Byte54: start 432, 8 bit, little-endian, data-type-policy=OVERRIDE, base-type=uint8, compu {phys=raw}, range phys 0..252
          signal TPDiagnosisFlashIPBFBD_VL_Byte55: start 440, 8 bit, little-endian, data-type-policy=OVERRIDE, base-type=uint8, compu {phys=raw}, range phys 0..252
          signal TPDiagnosisFlashIPBFBD_VL_Byte56: start 448, 8 bit, little-endian, data-type-policy=OVERRIDE, base-type=uint8, compu {phys=raw}, range phys 0..252
          signal TPDiagnosisFlashIPBFBD_VL_Byte57: start 456, 8 bit, little-endian, data-type-policy=OVERRIDE, base-type=uint8, compu {phys=raw}, range phys 0..252
          signal TPDiagnosisFlashIPBFBD_VL_Byte58: start 464, 8 bit, little-endian, data-type-policy=OVERRIDE, base-type=uint8, compu {phys=raw}, range phys 0..252
          signal TPDiagnosisFlashIPBFBD_VL_Byte59: start 472, 8 bit, little-endian, data-type-policy=OVERRIDE, base-type=uint8, compu {phys=raw}, range phys 0..252
          signal TPDiagnosisFlashIPBFBD_VL_Byte60: start 480, 8 bit, little-endian, data-type-policy=OVERRIDE, base-type=uint8, compu {phys=raw}, range phys 0..252
          signal TPDiagnosisFlashIPBFBD_VL_Byte61: start 488, 8 bit, little-endian, data-type-policy=OVERRIDE, base-type=uint8, compu {phys=raw}, range phys 0..252
          signal TPDiagnosisFlashIPBFBD_VL_Byte62: start 496, 8 bit, little-endian, data-type-policy=OVERRIDE, base-type=uint8, compu {phys=raw}, range phys 0..252
          signal TPDiagnosisFlashIPBFBD_VL_Byte63: start 504, 8 bit, little-endian, data-type-policy=OVERRIDE, base-type=uint8, compu {phys=raw}, range phys 0..252
      frame TPDiagnosisFlash_IPB_FBD_VM: id 0x2BC, frame-length=64, can-addressing-mode=STANDARD, can-frame-rx-behavior=CAN-FD, can-frame-tx-behavior=CAN-FD
        pdu TPDiagnosisFlash_IPB_FBD_VM: length=64, unused-bit-pattern=0
          signal TPDiagnosisFlashIPBFBD_VM_Byte00: start 0, 8 bit, little-endian, data-type-policy=OVERRIDE, base-type=uint8, compu {phys=raw}, range phys 0..252
          signal TPDiagnosisFlashIPBFBD_VM_Byte01: start 8, 8 bit, little-endian, data-type-policy=OVERRIDE, base-type=uint8, compu {phys=raw}, range phys 0..252
          signal TPDiagnosisFlashIPBFBD_VM_Byte02: start 16, 8 bit, little-endian, data-type-policy=OVERRIDE, base-type=uint8, compu {phys=raw}, range phys 0..252
          signal TPDiagnosisFlashIPBFBD_VM_Byte03: start 24, 8 bit, little-endian, data-type-policy=OVERRIDE, base-type=uint8, compu {phys=raw}, range phys 0..252
          signal TPDiagnosisFlashIPBFBD_VM_Byte04: start 32, 8 bit, little-endian, data-type-policy=OVERRIDE, base-type=uint8, compu {phys=raw}, range phys 0..252
          signal TPDiagnosisFlashIPBFBD_VM_Byte05: start 40, 8 bit, little-endian, data-type-policy=OVERRIDE, base-type=uint8, compu {phys=raw}, range phys 0..252
          signal TPDiagnosisFlashIPBFBD_VM_Byte06: start 48, 8 bit, little-endian, data-type-policy=OVERRIDE, base-type=uint8, compu {phys=raw}, range phys 0..252
          signal TPDiagnosisFlashIPBFBD_VM_Byte07: start 56, 8 bit, little-endian, data-type-policy=OVERRIDE, base-type=uint8, compu {phys=raw}, range phys 0..252
          signal TPDiagnosisFlashIPBFBD_VM_Byte08: start 64, 8 bit, little-endian, data-type-policy=OVERRIDE, base-type=uint8, compu {phys=raw}, range phys 0..252
          signal TPDiagnosisFlashIPBFBD_VM_Byte09: start 72, 8 bit, little-endian, data-type-policy=OVERRIDE, base-type=uint8, compu {phys=raw}, range phys 0..252
          signal TPDiagnosisFlashIPBFBD_VM_Byte10: start 80, 8 bit, little-endian, data-type-policy=OVERRIDE, base-type=uint8, compu {phys=raw}, range phys 0..252
          signal TPDiagnosisFlashIPBFBD_VM_Byte11: start 88, 8 bit, little-endian, data-type-policy=OVERRIDE, base-type=uint8, compu {phys=raw}, range phys 0..252
          signal TPDiagnosisFlashIPBFBD_VM_Byte12: start 96, 8 bit, little-endian, data-type-policy=OVERRIDE, base-type=uint8, compu {phys=raw}, range phys 0..252
          signal TPDiagnosisFlashIPBFBD_VM_Byte13: start 104, 8 bit, little-endian, data-type-policy=OVERRIDE, base-type=uint8, compu {phys=raw}, range phys 0..252
          signal TPDiagnosisFlashIPBFBD_VM_Byte14: start 112, 8 bit, little-endian, data-type-policy=OVERRIDE, base-type=uint8, compu {phys=raw}, range phys 0..252
          signal TPDiagnosisFlashIPBFBD_VM_Byte15: start 120, 8 bit, little-endian, data-type-policy=OVERRIDE, base-type=uint8, compu {phys=raw}, range phys 0..252
          signal TPDiagnosisFlashIPBFBD_VM_Byte16: start 128, 8 bit, little-endian, data-type-policy=OVERRIDE, base-type=uint8, compu {phys=raw}, range phys 0..252
          signal TPDiagnosisFlashIPBFBD_VM_Byte17: start 136, 8 bit, little-endian, data-type-policy=OVERRIDE, base-type=uint8, compu {phys=raw}, range phys 0..252
          signal TPDiagnosisFlashIPBFBD_VM_Byte18: start 144, 8 bit, little-endian, data-type-policy=OVERRIDE, base-type=uint8, compu {phys=raw}, range phys 0..252
          signal TPDiagnosisFlashIPBFBD_VM_Byte19: start 152, 8 bit, little-endian, data-type-policy=OVERRIDE, base-type=uint8, compu {phys=raw}, range phys 0..252
          signal TPDiagnosisFlashIPBFBD_VM_Byte20: start 160, 8 bit, little-endian, data-type-policy=OVERRIDE, base-type=uint8, compu {phys=raw}, range phys 0..252
          signal TPDiagnosisFlashIPBFBD_VM_Byte21: start 168, 8 bit, little-endian, data-type-policy=OVERRIDE, base-type=uint8, compu {phys=raw}, range phys 0..252
          signal TPDiagnosisFlashIPBFBD_VM_Byte22: start 176, 8 bit, little-endian, data-type-policy=OVERRIDE, base-type=uint8, compu {phys=raw}, range phys 0..252
          signal TPDiagnosisFlashIPBFBD_VM_Byte23: start 184, 8 bit, little-endian, data-type-policy=OVERRIDE, base-type=uint8, compu {phys=raw}, range phys 0..252
          signal TPDiagnosisFlashIPBFBD_VM_Byte24: start 192, 8 bit, little-endian, data-type-policy=OVERRIDE, base-type=uint8, compu {phys=raw}, range phys 0..252
          signal TPDiagnosisFlashIPBFBD_VM_Byte25: start 200, 8 bit, little-endian, data-type-policy=OVERRIDE, base-type=uint8, compu {phys=raw}, range phys 0..252
          signal TPDiagnosisFlashIPBFBD_VM_Byte26: start 208, 8 bit, little-endian, data-type-policy=OVERRIDE, base-type=uint8, compu {phys=raw}, range phys 0..252
          signal TPDiagnosisFlashIPBFBD_VM_Byte27: start 216, 8 bit, little-endian, data-type-policy=OVERRIDE, base-type=uint8, compu {phys=raw}, range phys 0..252
          signal TPDiagnosisFlashIPBFBD_VM_Byte28: start 224, 8 bit, little-endian, data-type-policy=OVERRIDE, base-type=uint8, compu {phys=raw}, range phys 0..252
          signal TPDiagnosisFlashIPBFBD_VM_Byte29: start 232, 8 bit, little-endian, data-type-policy=OVERRIDE, base-type=uint8, compu {phys=raw}, range phys 0..252
          signal TPDiagnosisFlashIPBFBD_VM_Byte30: start 240, 8 bit, little-endian, data-type-policy=OVERRIDE, base-type=uint8, compu {phys=raw}, range phys 0..252
          signal TPDiagnosisFlashIPBFBD_VM_Byte31: start 248, 8 bit, little-endian, data-type-policy=OVERRIDE, base-type=uint8, compu {phys=raw}, range phys 0..252
          signal TPDiagnosisFlashIPBFBD_VM_Byte32: start 256, 8 bit, little-endian, data-type-policy=OVERRIDE, base-type=uint8, compu {phys=raw}, range phys 0..252
          signal TPDiagnosisFlashIPBFBD_VM_Byte33: start 264, 8 bit, little-endian, data-type-policy=OVERRIDE, base-type=uint8, compu {phys=raw}, range phys 0..252
          signal TPDiagnosisFlashIPBFBD_VM_Byte34: start 272, 8 bit, little-endian, data-type-policy=OVERRIDE, base-type=uint8, compu {phys=raw}, range phys 0..252
          signal TPDiagnosisFlashIPBFBD_VM_Byte35: start 280, 8 bit, little-endian, data-type-policy=OVERRIDE, base-type=uint8, compu {phys=raw}, range phys 0..252
          signal TPDiagnosisFlashIPBFBD_VM_Byte36: start 288, 8 bit, little-endian, data-type-policy=OVERRIDE, base-type=uint8, compu {phys=raw}, range phys 0..252
          signal TPDiagnosisFlashIPBFBD_VM_Byte37: start 296, 8 bit, little-endian, data-type-policy=OVERRIDE, base-type=uint8, compu {phys=raw}, range phys 0..252
          signal TPDiagnosisFlashIPBFBD_VM_Byte38: start 304, 8 bit, little-endian, data-type-policy=OVERRIDE, base-type=uint8, compu {phys=raw}, range phys 0..252
          signal TPDiagnosisFlashIPBFBD_VM_Byte39: start 312, 8 bit, little-endian, data-type-policy=OVERRIDE, base-type=uint8, compu {phys=raw}, range phys 0..252
          signal TPDiagnosisFlashIPBFBD_VM_Byte40: start 320, 8 bit, little-endian, data-type-policy=OVERRIDE, base-type=uint8, compu {phys=raw}, range phys 0..252
          signal TPDiagnosisFlashIPBFBD_VM_Byte41: start 328, 8 bit, little-endian, data-type-policy=OVERRIDE, base-type=uint8, compu {phys=raw}, range phys 0..252
          signal TPDiagnosisFlashIPBFBD_VM_Byte42: start 336, 8 bit, little-endian, data-type-policy=OVERRIDE, base-type=uint8, compu {phys=raw}, range phys 0..252
          signal TPDiagnosisFlashIPBFBD_VM_Byte43: start 344, 8 bit, little-endian, data-type-policy=OVERRIDE, base-type=uint8, compu {phys=raw}, range phys 0..252
          signal TPDiagnosisFlashIPBFBD_VM_Byte44: start 352, 8 bit, little-endian, data-type-policy=OVERRIDE, base-type=uint8, compu {phys=raw}, range phys 0..252
          signal TPDiagnosisFlashIPBFBD_VM_Byte45: start 360, 8 bit, little-endian, data-type-policy=OVERRIDE, base-type=uint8, compu {phys=raw}, range phys 0..252
          signal TPDiagnosisFlashIPBFBD_VM_Byte46: start 368, 8 bit, little-endian, data-type-policy=OVERRIDE, base-type=uint8, compu {phys=raw}, range phys 0..252
          signal TPDiagnosisFlashIPBFBD_VM_Byte47: start 376, 8 bit, little-endian, data-type-policy=OVERRIDE, base-type=uint8, compu {phys=raw}, range phys 0..252
          signal TPDiagnosisFlashIPBFBD_VM_Byte48: start 384, 8 bit, little-endian, data-type-policy=OVERRIDE, base-type=uint8, compu {phys=raw}, range phys 0..252
          signal TPDiagnosisFlashIPBFBD_VM_Byte49: start 392, 8 bit, little-endian, data-type-policy=OVERRIDE, base-type=uint8, compu {phys=raw}, range phys 0..252
          signal TPDiagnosisFlashIPBFBD_VM_Byte50: start 400, 8 bit, little-endian, data-type-policy=OVERRIDE, base-type=uint8, compu {phys=raw}, range phys 0..252
          signal TPDiagnosisFlashIPBFBD_VM_Byte51: start 408, 8 bit, little-endian, data-type-policy=OVERRIDE, base-type=uint8, compu {phys=raw}, range phys 0..252
          signal TPDiagnosisFlashIPBFBD_VM_Byte52: start 416, 8 bit, little-endian, data-type-policy=OVERRIDE, base-type=uint8, compu {phys=raw}, range phys 0..252
          signal TPDiagnosisFlashIPBFBD_VM_Byte53: start 424, 8 bit, little-endian, data-type-policy=OVERRIDE, base-type=uint8, compu {phys=raw}, range phys 0..252
          signal TPDiagnosisFlashIPBFBD_VM_Byte54: start 432, 8 bit, little-endian, data-type-policy=OVERRIDE, base-type=uint8, compu {phys=raw}, range phys 0..252
          signal TPDiagnosisFlashIPBFBD_VM_Byte55: start 440, 8 bit, little-endian, data-type-policy=OVERRIDE, base-type=uint8, compu {phys=raw}, range phys 0..252
          signal TPDiagnosisFlashIPBFBD_VM_Byte56: start 448, 8 bit, little-endian, data-type-policy=OVERRIDE, base-type=uint8, compu {phys=raw}, range phys 0..252
          signal TPDiagnosisFlashIPBFBD_VM_Byte57: start 456, 8 bit, little-endian, data-type-policy=OVERRIDE, base-type=uint8, compu {phys=raw}, range phys 0..252
          signal TPDiagnosisFlashIPBFBD_VM_Byte58: start 464, 8 bit, little-endian, data-type-policy=OVERRIDE, base-type=uint8, compu {phys=raw}, range phys 0..252
          signal TPDiagnosisFlashIPBFBD_VM_Byte59: start 472, 8 bit, little-endian, data-type-policy=OVERRIDE, base-type=uint8, compu {phys=raw}, range phys 0..252
          signal TPDiagnosisFlashIPBFBD_VM_Byte60: start 480, 8 bit, little-endian, data-type-policy=OVERRIDE, base-type=uint8, compu {phys=raw}, range phys 0..252
          signal TPDiagnosisFlashIPBFBD_VM_Byte61: start 488, 8 bit, little-endian, data-type-policy=OVERRIDE, base-type=uint8, compu {phys=raw}, range phys 0..252
          signal TPDiagnosisFlashIPBFBD_VM_Byte62: start 496, 8 bit, little-endian, data-type-policy=OVERRIDE, base-type=uint8, compu {phys=raw}, range phys 0..252
          signal TPDiagnosisFlashIPBFBD_VM_Byte63: start 504, 8 bit, little-endian, data-type-policy=OVERRIDE, base-type=uint8, compu {phys=raw}, range phys 0..252
      frame TPDiagnosisFlash_IPB_FBD_VR: id 0x2C1, frame-length=64, can-addressing-mode=STANDARD, can-frame-rx-behavior=CAN-FD, can-frame-tx-behavior=CAN-FD
        pdu TPDiagnosisFlash_IPB_FBD_VR: length=64, unused-bit-pattern=0
          signal TPDiagnosisFlashIPBFBD_VR_Byte00: start 0, 8 bit, little-endian, data-type-policy=OVERRIDE, base-type=uint8, compu {phys=raw}, range phys 0..252
          signal TPDiagnosisFlashIPBFBD_VR_Byte01: start 8, 8 bit, little-endian, data-type-policy=OVERRIDE, base-type=uint8, compu {phys=raw}, range phys 0..252
          signal TPDiagnosisFlashIPBFBD_VR_Byte02: start 16, 8 bit, little-endian, data-type-policy=OVERRIDE, base-type=uint8, compu {phys=raw}, range phys 0..252
          signal TPDiagnosisFlashIPBFBD_VR_Byte03: start 24, 8 bit, little-endian, data-type-policy=OVERRIDE, base-type=uint8, compu {phys=raw}, range phys 0..252
          signal TPDiagnosisFlashIPBFBD_VR_Byte04: start 32, 8 bit, little-endian, data-type-policy=OVERRIDE, base-type=uint8, compu {phys=raw}, range phys 0..252
          signal TPDiagnosisFlashIPBFBD_VR_Byte05: start 40, 8 bit, little-endian, data-type-policy=OVERRIDE, base-type=uint8, compu {phys=raw}, range phys 0..252
          signal TPDiagnosisFlashIPBFBD_VR_Byte06: start 48, 8 bit, little-endian, data-type-policy=OVERRIDE, base-type=uint8, compu {phys=raw}, range phys 0..252
          signal TPDiagnosisFlashIPBFBD_VR_Byte07: start 56, 8 bit, little-endian, data-type-policy=OVERRIDE, base-type=uint8, compu {phys=raw}, range phys 0..252
          signal TPDiagnosisFlashIPBFBD_VR_Byte08: start 64, 8 bit, little-endian, data-type-policy=OVERRIDE, base-type=uint8, compu {phys=raw}, range phys 0..252
          signal TPDiagnosisFlashIPBFBD_VR_Byte09: start 72, 8 bit, little-endian, data-type-policy=OVERRIDE, base-type=uint8, compu {phys=raw}, range phys 0..252
          signal TPDiagnosisFlashIPBFBD_VR_Byte10: start 80, 8 bit, little-endian, data-type-policy=OVERRIDE, base-type=uint8, compu {phys=raw}, range phys 0..252
          signal TPDiagnosisFlashIPBFBD_VR_Byte11: start 88, 8 bit, little-endian, data-type-policy=OVERRIDE, base-type=uint8, compu {phys=raw}, range phys 0..252
          signal TPDiagnosisFlashIPBFBD_VR_Byte12: start 96, 8 bit, little-endian, data-type-policy=OVERRIDE, base-type=uint8, compu {phys=raw}, range phys 0..252
          signal TPDiagnosisFlashIPBFBD_VR_Byte13: start 104, 8 bit, little-endian, data-type-policy=OVERRIDE, base-type=uint8, compu {phys=raw}, range phys 0..252
          signal TPDiagnosisFlashIPBFBD_VR_Byte14: start 112, 8 bit, little-endian, data-type-policy=OVERRIDE, base-type=uint8, compu {phys=raw}, range phys 0..252
          signal TPDiagnosisFlashIPBFBD_VR_Byte15: start 120, 8 bit, little-endian, data-type-policy=OVERRIDE, base-type=uint8, compu {phys=raw}, range phys 0..252
          signal TPDiagnosisFlashIPBFBD_VR_Byte16: start 128, 8 bit, little-endian, data-type-policy=OVERRIDE, base-type=uint8, compu {phys=raw}, range phys 0..252
          signal TPDiagnosisFlashIPBFBD_VR_Byte17: start 136, 8 bit, little-endian, data-type-policy=OVERRIDE, base-type=uint8, compu {phys=raw}, range phys 0..252
          signal TPDiagnosisFlashIPBFBD_VR_Byte18: start 144, 8 bit, little-endian, data-type-policy=OVERRIDE, base-type=uint8, compu {phys=raw}, range phys 0..252
          signal TPDiagnosisFlashIPBFBD_VR_Byte19: start 152, 8 bit, little-endian, data-type-policy=OVERRIDE, base-type=uint8, compu {phys=raw}, range phys 0..252
          signal TPDiagnosisFlashIPBFBD_VR_Byte20: start 160, 8 bit, little-endian, data-type-policy=OVERRIDE, base-type=uint8, compu {phys=raw}, range phys 0..252
          signal TPDiagnosisFlashIPBFBD_VR_Byte21: start 168, 8 bit, little-endian, data-type-policy=OVERRIDE, base-type=uint8, compu {phys=raw}, range phys 0..252
          signal TPDiagnosisFlashIPBFBD_VR_Byte22: start 176, 8 bit, little-endian, data-type-policy=OVERRIDE, base-type=uint8, compu {phys=raw}, range phys 0..252
          signal TPDiagnosisFlashIPBFBD_VR_Byte23: start 184, 8 bit, little-endian, data-type-policy=OVERRIDE, base-type=uint8, compu {phys=raw}, range phys 0..252
          signal TPDiagnosisFlashIPBFBD_VR_Byte24: start 192, 8 bit, little-endian, data-type-policy=OVERRIDE, base-type=uint8, compu {phys=raw}, range phys 0..252
          signal TPDiagnosisFlashIPBFBD_VR_Byte25: start 200, 8 bit, little-endian, data-type-policy=OVERRIDE, base-type=uint8, compu {phys=raw}, range phys 0..252
          signal TPDiagnosisFlashIPBFBD_VR_Byte26: start 208, 8 bit, little-endian, data-type-policy=OVERRIDE, base-type=uint8, compu {phys=raw}, range phys 0..252
          signal TPDiagnosisFlashIPBFBD_VR_Byte27: start 216, 8 bit, little-endian, data-type-policy=OVERRIDE, base-type=uint8, compu {phys=raw}, range phys 0..252
          signal TPDiagnosisFlashIPBFBD_VR_Byte28: start 224, 8 bit, little-endian, data-type-policy=OVERRIDE, base-type=uint8, compu {phys=raw}, range phys 0..252
          signal TPDiagnosisFlashIPBFBD_VR_Byte29: start 232, 8 bit, little-endian, data-type-policy=OVERRIDE, base-type=uint8, compu {phys=raw}, range phys 0..252
          signal TPDiagnosisFlashIPBFBD_VR_Byte30: start 240, 8 bit, little-endian, data-type-policy=OVERRIDE, base-type=uint8, compu {phys=raw}, range phys 0..252
          signal TPDiagnosisFlashIPBFBD_VR_Byte31: start 248, 8 bit, little-endian, data-type-policy=OVERRIDE, base-type=uint8, compu {phys=raw}, range phys 0..252
          signal TPDiagnosisFlashIPBFBD_VR_Byte32: start 256, 8 bit, little-endian, data-type-policy=OVERRIDE, base-type=uint8, compu {phys=raw}, range phys 0..252
          signal TPDiagnosisFlashIPBFBD_VR_Byte33: start 264, 8 bit, little-endian, data-type-policy=OVERRIDE, base-type=uint8, compu {phys=raw}, range phys 0..252
          signal TPDiagnosisFlashIPBFBD_VR_Byte34: start 272, 8 bit, little-endian, data-type-policy=OVERRIDE, base-type=uint8, compu {phys=raw}, range phys 0..252
          signal TPDiagnosisFlashIPBFBD_VR_Byte35: start 280, 8 bit, little-endian, data-type-policy=OVERRIDE, base-type=uint8, compu {phys=raw}, range phys 0..252
          signal TPDiagnosisFlashIPBFBD_VR_Byte36: start 288, 8 bit, little-endian, data-type-policy=OVERRIDE, base-type=uint8, compu {phys=raw}, range phys 0..252
          signal TPDiagnosisFlashIPBFBD_VR_Byte37: start 296, 8 bit, little-endian, data-type-policy=OVERRIDE, base-type=uint8, compu {phys=raw}, range phys 0..252
          signal TPDiagnosisFlashIPBFBD_VR_Byte38: start 304, 8 bit, little-endian, data-type-policy=OVERRIDE, base-type=uint8, compu {phys=raw}, range phys 0..252
          signal TPDiagnosisFlashIPBFBD_VR_Byte39: start 312, 8 bit, little-endian, data-type-policy=OVERRIDE, base-type=uint8, compu {phys=raw}, range phys 0..252
          signal TPDiagnosisFlashIPBFBD_VR_Byte40: start 320, 8 bit, little-endian, data-type-policy=OVERRIDE, base-type=uint8, compu {phys=raw}, range phys 0..252
          signal TPDiagnosisFlashIPBFBD_VR_Byte41: start 328, 8 bit, little-endian, data-type-policy=OVERRIDE, base-type=uint8, compu {phys=raw}, range phys 0..252
          signal TPDiagnosisFlashIPBFBD_VR_Byte42: start 336, 8 bit, little-endian, data-type-policy=OVERRIDE, base-type=uint8, compu {phys=raw}, range phys 0..252
          signal TPDiagnosisFlashIPBFBD_VR_Byte43: start 344, 8 bit, little-endian, data-type-policy=OVERRIDE, base-type=uint8, compu {phys=raw}, range phys 0..252
          signal TPDiagnosisFlashIPBFBD_VR_Byte44: start 352, 8 bit, little-endian, data-type-policy=OVERRIDE, base-type=uint8, compu {phys=raw}, range phys 0..252
          signal TPDiagnosisFlashIPBFBD_VR_Byte45: start 360, 8 bit, little-endian, data-type-policy=OVERRIDE, base-type=uint8, compu {phys=raw}, range phys 0..252
          signal TPDiagnosisFlashIPBFBD_VR_Byte46: start 368, 8 bit, little-endian, data-type-policy=OVERRIDE, base-type=uint8, compu {phys=raw}, range phys 0..252
          signal TPDiagnosisFlashIPBFBD_VR_Byte47: start 376, 8 bit, little-endian, data-type-policy=OVERRIDE, base-type=uint8, compu {phys=raw}, range phys 0..252
          signal TPDiagnosisFlashIPBFBD_VR_Byte48: start 384, 8 bit, little-endian, data-type-policy=OVERRIDE, base-type=uint8, compu {phys=raw}, range phys 0..252
          signal TPDiagnosisFlashIPBFBD_VR_Byte49: start 392, 8 bit, little-endian, data-type-policy=OVERRIDE, base-type=uint8, compu {phys=raw}, range phys 0..252
          signal TPDiagnosisFlashIPBFBD_VR_Byte50: start 400, 8 bit, little-endian, data-type-policy=OVERRIDE, base-type=uint8, compu {phys=raw}, range phys 0..252
          signal TPDiagnosisFlashIPBFBD_VR_Byte51: start 408, 8 bit, little-endian, data-type-policy=OVERRIDE, base-type=uint8, compu {phys=raw}, range phys 0..252
          signal TPDiagnosisFlashIPBFBD_VR_Byte52: start 416, 8 bit, little-endian, data-type-policy=OVERRIDE, base-type=uint8, compu {phys=raw}, range phys 0..252
          signal TPDiagnosisFlashIPBFBD_VR_Byte53: start 424, 8 bit, little-endian, data-type-policy=OVERRIDE, base-type=uint8, compu {phys=raw}, range phys 0..252
          signal TPDiagnosisFlashIPBFBD_VR_Byte54: start 432, 8 bit, little-endian, data-type-policy=OVERRIDE, base-type=uint8, compu {phys=raw}, range phys 0..252
          signal TPDiagnosisFlashIPBFBD_VR_Byte55: start 440, 8 bit, little-endian, data-type-policy=OVERRIDE, base-type=uint8, compu {phys=raw}, range phys 0..252
          signal TPDiagnosisFlashIPBFBD_VR_Byte56: start 448, 8 bit, little-endian, data-type-policy=OVERRIDE, base-type=uint8, compu {phys=raw}, range phys 0..252
          signal TPDiagnosisFlashIPBFBD_VR_Byte57: start 456, 8 bit, little-endian, data-type-policy=OVERRIDE, base-type=uint8, compu {phys=raw}, range phys 0..252
          signal TPDiagnosisFlashIPBFBD_VR_Byte58: start 464, 8 bit, little-endian, data-type-policy=OVERRIDE, base-type=uint8, compu {phys=raw}, range phys 0..252
          signal TPDiagnosisFlashIPBFBD_VR_Byte59: start 472, 8 bit, little-endian, data-type-policy=OVERRIDE, base-type=uint8, compu {phys=raw}, range phys 0..252
          signal TPDiagnosisFlashIPBFBD_VR_Byte60: start 480, 8 bit, little-endian, data-type-policy=OVERRIDE, base-type=uint8, compu {phys=raw}, range phys 0..252
          signal TPDiagnosisFlashIPBFBD_VR_Byte61: start 488, 8 bit, little-endian, data-type-policy=OVERRIDE, base-type=uint8, compu {phys=raw}, range phys 0..252
          signal TPDiagnosisFlashIPBFBD_VR_Byte62: start 496, 8 bit, little-endian, data-type-policy=OVERRIDE, base-type=uint8, compu {phys=raw}, range phys 0..252
          signal TPDiagnosisFlashIPBFBD_VR_Byte63: start 504, 8 bit, little-endian, data-type-policy=OVERRIDE, base-type=uint8, compu {phys=raw}, range phys 0..252
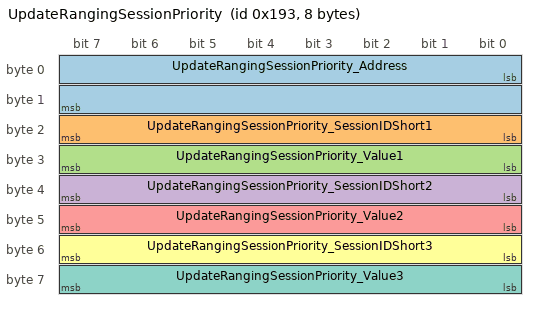
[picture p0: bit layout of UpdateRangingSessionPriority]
      frame UpdateRangingSessionPriority: id 0x193, frame-length=8, can-addressing-mode=STANDARD, can-frame-rx-behavior=CAN-20, can-frame-tx-behavior=CAN-20
        pdu UpdateRangingSessionPriority: length=8, unused-bit-pattern=0
          signal UpdateRangingSessionPriority_Address: start 0, 16 bit, little-endian, data-type-policy=OVERRIDE, compu {phys=raw}
          signal UpdateRangingSessionPriority_SessionIDShort1: start 16, 8 bit, little-endian, data-type-policy=OVERRIDE, base-type=uint8, compu {phys=raw}, range phys 0..252
          signal UpdateRangingSessionPriority_Value1: start 24, 8 bit, little-endian, data-type-policy=OVERRIDE, base-type=uint8, compu {phys=raw}, range phys 0..252
          signal UpdateRangingSessionPriority_SessionIDShort2: start 32, 8 bit, little-endian, data-type-policy=OVERRIDE, base-type=uint8, compu {phys=raw}, range phys 0..252
          signal UpdateRangingSessionPriority_Value2: start 40, 8 bit, little-endian, data-type-policy=OVERRIDE, base-type=uint8, compu {phys=raw}, range phys 0..252
          signal UpdateRangingSessionPriority_SessionIDShort3: start 48, 8 bit, little-endian, data-type-policy=OVERRIDE, base-type=uint8, compu {phys=raw}, range phys 0..252
          signal UpdateRangingSessionPriority_Value3: start 56, 8 bit, little-endian, data-type-policy=OVERRIDE, base-type=uint8, compu {phys=raw}, range phys 0..252
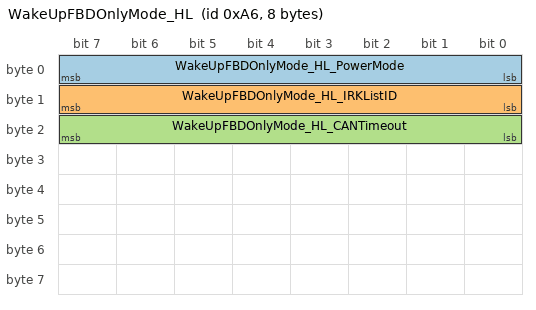
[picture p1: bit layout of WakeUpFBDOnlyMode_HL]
      frame WakeUpFBDOnlyMode_HL: id 0xA6, frame-length=8, can-addressing-mode=STANDARD, can-frame-rx-behavior=CAN-20, can-frame-tx-behavior=CAN-20
        pdu WakeUpFBDOnlyMode_HL: length=8, unused-bit-pattern=0
          signal WakeUpFBDOnlyMode_HL_PowerMode: start 0, 8 bit, little-endian, data-type-policy=OVERRIDE, compu {phys=raw}
          signal WakeUpFBDOnlyMode_HL_IRKListID: start 8, 8 bit, little-endian, data-type-policy=OVERRIDE, base-type=uint8, compu {phys=raw}, range phys 0..252
          signal WakeUpFBDOnlyMode_HL_CANTimeout: start 16, 8 bit, little-endian, data-type-policy=OVERRIDE, base-type=uint8, compu {phys=raw}, range phys 0..252
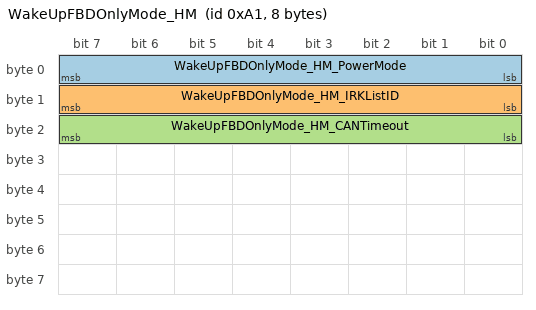
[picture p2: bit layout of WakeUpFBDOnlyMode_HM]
      frame WakeUpFBDOnlyMode_HM: id 0xA1, frame-length=8, can-addressing-mode=STANDARD, can-frame-rx-behavior=CAN-20, can-frame-tx-behavior=CAN-20
        pdu WakeUpFBDOnlyMode_HM: length=8, unused-bit-pattern=0
          signal WakeUpFBDOnlyMode_HM_PowerMode: start 0, 8 bit, little-endian, data-type-policy=OVERRIDE, compu {phys=raw}
          signal WakeUpFBDOnlyMode_HM_IRKListID: start 8, 8 bit, little-endian, data-type-policy=OVERRIDE, base-type=uint8, compu {phys=raw}, range phys 0..252
          signal WakeUpFBDOnlyMode_HM_CANTimeout: start 16, 8 bit, little-endian, data-type-policy=OVERRIDE, base-type=uint8, compu {phys=raw}, range phys 0..252
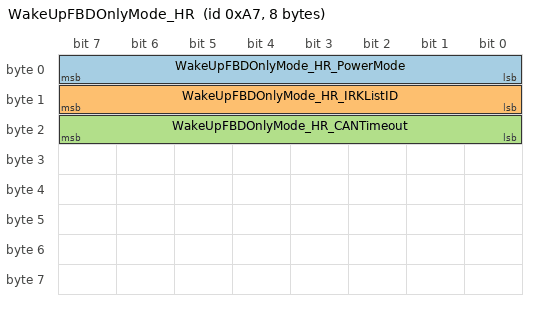
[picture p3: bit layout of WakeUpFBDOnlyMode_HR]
      frame WakeUpFBDOnlyMode_HR: id 0xA7, frame-length=8, can-addressing-mode=STANDARD, can-frame-rx-behavior=CAN-20, can-frame-tx-behavior=CAN-20
        pdu WakeUpFBDOnlyMode_HR: length=8, unused-bit-pattern=0
          signal WakeUpFBDOnlyMode_HR_PowerMode: start 0, 8 bit, little-endian, data-type-policy=OVERRIDE, compu {phys=raw}
          signal WakeUpFBDOnlyMode_HR_IRKListID: start 8, 8 bit, little-endian, data-type-policy=OVERRIDE, base-type=uint8, compu {phys=raw}, range phys 0..252
          signal WakeUpFBDOnlyMode_HR_CANTimeout: start 16, 8 bit, little-endian, data-type-policy=OVERRIDE, base-type=uint8, compu {phys=raw}, range phys 0..252
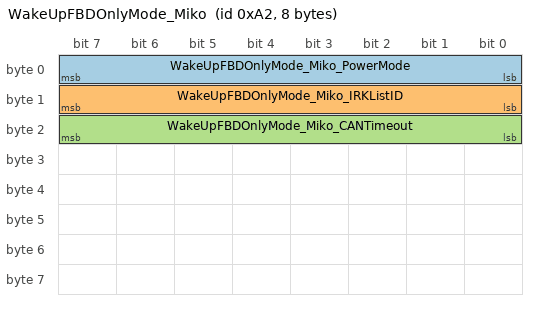
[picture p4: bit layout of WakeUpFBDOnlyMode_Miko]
      frame WakeUpFBDOnlyMode_Miko: id 0xA2, frame-length=8, can-addressing-mode=STANDARD, can-frame-rx-behavior=CAN-20, can-frame-tx-behavior=CAN-20
        pdu WakeUpFBDOnlyMode_Miko: length=8, unused-bit-pattern=0
          signal WakeUpFBDOnlyMode_Miko_PowerMode: start 0, 8 bit, little-endian, data-type-policy=OVERRIDE, compu {phys=raw}
          signal WakeUpFBDOnlyMode_Miko_IRKListID: start 8, 8 bit, little-endian, data-type-policy=OVERRIDE, base-type=uint8, compu {phys=raw}, range phys 0..252
          signal WakeUpFBDOnlyMode_Miko_CANTimeout: start 16, 8 bit, little-endian, data-type-policy=OVERRIDE, base-type=uint8, compu {phys=raw}, range phys 0..252
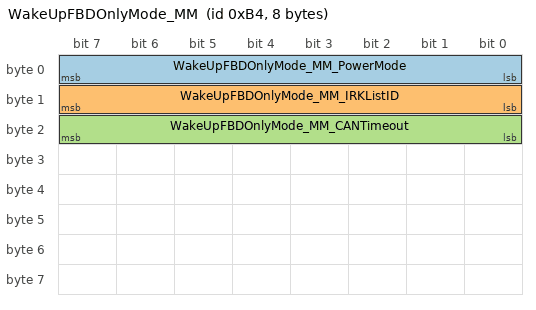
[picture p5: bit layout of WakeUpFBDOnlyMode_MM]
      frame WakeUpFBDOnlyMode_MM: id 0xB4, frame-length=8, can-addressing-mode=STANDARD, can-frame-rx-behavior=CAN-20, can-frame-tx-behavior=CAN-20
        pdu WakeUpFBDOnlyMode_MM: length=8, unused-bit-pattern=0
          signal WakeUpFBDOnlyMode_MM_PowerMode: start 0, 8 bit, little-endian, data-type-policy=OVERRIDE, compu {phys=raw}
          signal WakeUpFBDOnlyMode_MM_IRKListID: start 8, 8 bit, little-endian, data-type-policy=OVERRIDE, base-type=uint8, compu {phys=raw}, range phys 0..252
          signal WakeUpFBDOnlyMode_MM_CANTimeout: start 16, 8 bit, little-endian, data-type-policy=OVERRIDE, base-type=uint8, compu {phys=raw}, range phys 0..252
      frame WakeUpFBDOnlyMode_SML: id 0xA8, frame-length=8, can-addressing-mode=STANDARD, can-frame-rx-behavior=CAN-20, can-frame-tx-behavior=CAN-20
        pdu WakeUpFBDOnlyMode_SML: length=8, unused-bit-pattern=0
          signal WakeUpFBDOnlyMode_SML_PowerMode: start 0, 8 bit, little-endian, data-type-policy=OVERRIDE, compu {phys=raw}
          signal WakeUpFBDOnlyMode_SML_SessionIDShort: start 8, 8 bit, little-endian, data-type-policy=OVERRIDE, base-type=uint8, compu {phys=raw}, range phys 0..252
      frame WakeUpFBDOnlyMode_SMR: id 0xA9, frame-length=8, can-addressing-mode=STANDARD, can-frame-rx-behavior=CAN-20, can-frame-tx-behavior=CAN-20
        pdu WakeUpFBDOnlyMode_SMR: length=8, unused-bit-pattern=0
          signal WakeUpFBDOnlyMode_SMR_PowerMode: start 0, 8 bit, little-endian, data-type-policy=OVERRIDE, compu {phys=raw}
          signal WakeUpFBDOnlyMode_SMR_SessionIDShort: start 8, 8 bit, little-endian, data-type-policy=OVERRIDE, base-type=uint8, compu {phys=raw}, range phys 0..252
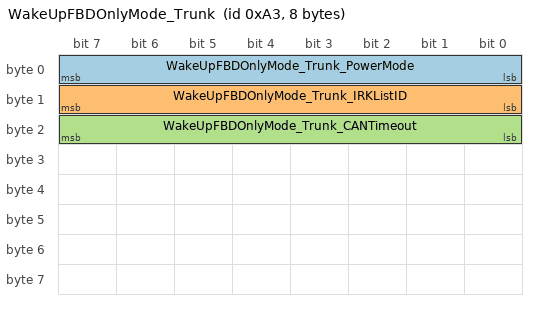
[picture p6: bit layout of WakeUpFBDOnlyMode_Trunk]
      frame WakeUpFBDOnlyMode_Trunk: id 0xA3, frame-length=8, can-addressing-mode=STANDARD, can-frame-rx-behavior=CAN-20, can-frame-tx-behavior=CAN-20
        pdu WakeUpFBDOnlyMode_Trunk: length=8, unused-bit-pattern=0
          signal WakeUpFBDOnlyMode_Trunk_PowerMode: start 0, 8 bit, little-endian, data-type-policy=OVERRIDE, compu {phys=raw}
          signal WakeUpFBDOnlyMode_Trunk_IRKListID: start 8, 8 bit, little-endian, data-type-policy=OVERRIDE, base-type=uint8, compu {phys=raw}, range phys 0..252
          signal WakeUpFBDOnlyMode_Trunk_CANTimeout: start 16, 8 bit, little-endian, data-type-policy=OVERRIDE, base-type=uint8, compu {phys=raw}, range phys 0..252
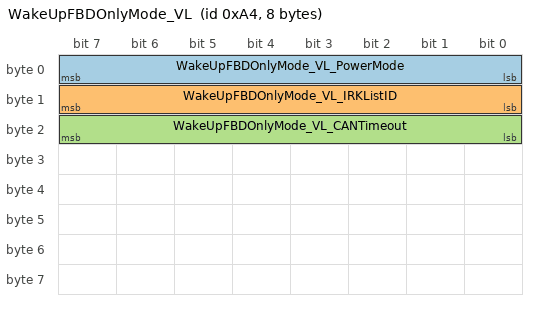
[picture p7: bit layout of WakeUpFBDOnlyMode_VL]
      frame WakeUpFBDOnlyMode_VL: id 0xA4, frame-length=8, can-addressing-mode=STANDARD, can-frame-rx-behavior=CAN-20, can-frame-tx-behavior=CAN-20
        pdu WakeUpFBDOnlyMode_VL: length=8, unused-bit-pattern=0
          signal WakeUpFBDOnlyMode_VL_PowerMode: start 0, 8 bit, little-endian, data-type-policy=OVERRIDE, compu {phys=raw}
          signal WakeUpFBDOnlyMode_VL_IRKListID: start 8, 8 bit, little-endian, data-type-policy=OVERRIDE, base-type=uint8, compu {phys=raw}, range phys 0..252
          signal WakeUpFBDOnlyMode_VL_CANTimeout: start 16, 8 bit, little-endian, data-type-policy=OVERRIDE, base-type=uint8, compu {phys=raw}, range phys 0..252
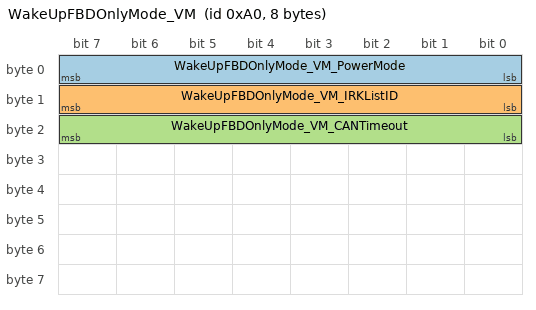
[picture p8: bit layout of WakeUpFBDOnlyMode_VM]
      frame WakeUpFBDOnlyMode_VM: id 0xA0, frame-length=8, can-addressing-mode=STANDARD, can-frame-rx-behavior=CAN-20, can-frame-tx-behavior=CAN-20
        pdu WakeUpFBDOnlyMode_VM: length=8, unused-bit-pattern=0
          signal WakeUpFBDOnlyMode_VM_PowerMode: start 0, 8 bit, little-endian, data-type-policy=OVERRIDE, compu {phys=raw}
          signal WakeUpFBDOnlyMode_VM_IRKListID: start 8, 8 bit, little-endian, data-type-policy=OVERRIDE, base-type=uint8, compu {phys=raw}, range phys 0..252
          signal WakeUpFBDOnlyMode_VM_CANTimeout: start 16, 8 bit, little-endian, data-type-policy=OVERRIDE, base-type=uint8, compu {phys=raw}, range phys 0..252
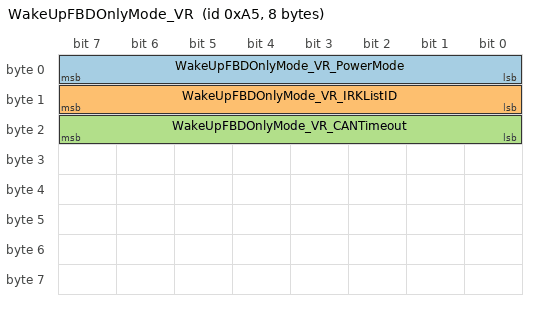
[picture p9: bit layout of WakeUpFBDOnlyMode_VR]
      frame WakeUpFBDOnlyMode_VR: id 0xA5, frame-length=8, can-addressing-mode=STANDARD, can-frame-rx-behavior=CAN-20, can-frame-tx-behavior=CAN-20
        pdu WakeUpFBDOnlyMode_VR: length=8, unused-bit-pattern=0
          signal WakeUpFBDOnlyMode_VR_PowerMode: start 0, 8 bit, little-endian, data-type-policy=OVERRIDE, compu {phys=raw}
          signal WakeUpFBDOnlyMode_VR_IRKListID: start 8, 8 bit, little-endian, data-type-policy=OVERRIDE, base-type=uint8, compu {phys=raw}, range phys 0..252
          signal WakeUpFBDOnlyMode_VR_CANTimeout: start 16, 8 bit, little-endian, data-type-policy=OVERRIDE, base-type=uint8, compu {phys=raw}, range phys 0..252
package /CANAnalyzer/DataTypes
  unit s: display-name=s
  unit ms: display-name=ms
  unit dB: display-name=dB
  unit m: display-name=m
  unit min: display-name=min
  unit cm: display-name=cm
  unit Item__: display-name=°
  unit ps: display-name=ps
  unit Item__C: display-name=°C
  unit us: display-name=us
  unit ns: display-name=ns
  unit Item___2: display-name=%
